VERSION "dbc-export 1 2026.26.6.5"

NS_ :

BS_:

BU_: ADSP APB APP APS APSB BB BMS CC CMP CMPD CP DAS DI DIF DIR DPB EPAS3P EPAS3S EPASTP EPASTS EPBL EPBR ESP EVSE FC GTW HCML HCMR HVP IBST ICR IDB LS OCS1P PARK PCS PCS2 PM PMF PMR PNCD PTC RADC RCM RCM2 RCM3 RCU SCCM SCM SCS SDCR TAS TCU TCU2 TPMS TRCM UI UIS UMC USM V2G VC VCBATT VCBATT0 VCBATT1 VCBATT2 VCCC VCFRONT VCFRONT1 VCFRONT2 VCLEFT VCRIGHT VCSEAT2L VCSEAT2R VCSEC VEH

BO_ 1065 APP_warningMatrix2: 8 APP
 SG_ APP_w129_mainCamExtNotCal : 0|1@1+ (1,0) [0|1] "" Vector__XXX
 SG_ APP_w130_narrowCamExtNotCal : 1|1@1+ (1,0) [0|1] "" Vector__XXX
 SG_ APP_w131_mainCamCalSaved : 2|1@1+ (1,0) [0|1] "" Vector__XXX
 SG_ APP_w132_narrowCamCalSaved : 3|1@1+ (1,0) [0|1] "" Vector__XXX
 SG_ APP_w133_mainCamInitFault : 4|1@1+ (1,0) [0|1] "" Vector__XXX
 SG_ APP_w134_narrowCamInitFault : 5|1@1+ (1,0) [0|1] "" Vector__XXX
 SG_ APP_w135_fisheyeCamInitFault : 6|1@1+ (1,0) [0|1] "" Vector__XXX
 SG_ APP_w136_lPillarCamInitFault : 7|1@1+ (1,0) [0|1] "" Vector__XXX
 SG_ APP_w137_rPillarCamInitFault : 8|1@1+ (1,0) [0|1] "" Vector__XXX
 SG_ APP_w138_lRepeatCamInitFault : 9|1@1+ (1,0) [0|1] "" Vector__XXX
 SG_ APP_w139_rRepeatCamInitFault : 10|1@1+ (1,0) [0|1] "" Vector__XXX
 SG_ APP_w140_backupCamInitFault : 11|1@1+ (1,0) [0|1] "" Vector__XXX
 SG_ APP_w141_ECU_Thermal_Issue : 12|1@1+ (1,0) [0|1] "" Vector__XXX
 SG_ APP_w142_fwdCamPitchProblem : 13|1@1+ (1,0) [0|1] "" Vector__XXX
 SG_ APP_w143_IDF_event : 14|1@1+ (1,0) [0|1] "" Vector__XXX
 SG_ APP_w144_fanctrldError : 15|1@1+ (1,0) [0|1] "" Vector__XXX
 SG_ APP_w145_camSelfCalIssue : 16|1@1+ (1,0) [0|1] "" Vector__XXX
 SG_ APP_w146_telemetryProblem : 17|1@1+ (1,0) [0|1] "" Vector__XXX
 SG_ APP_w147_selfieCamInitFault : 18|1@1+ (1,0) [0|1] "" Vector__XXX
 SG_ APP_w148_overlayActive : 19|1@1+ (1,0) [0|1] "" Vector__XXX
 SG_ APP_w149_diskFull : 20|1@1+ (1,0) [0|1] "" Vector__XXX
 SG_ APP_w150_diMiaPartyBus : 21|1@1+ (1,0) [0|1] "" Vector__XXX
 SG_ APP_w151_epasMiaPartyBus : 22|1@1+ (1,0) [0|1] "" Vector__XXX
 SG_ APP_w152_espMiaPartyBus : 23|1@1+ (1,0) [0|1] "" Vector__XXX
 SG_ APP_w153_rcmMiaPartyBus : 24|1@1+ (1,0) [0|1] "" Vector__XXX
 SG_ APP_w154_vcleftMiaPartyBus : 25|1@1+ (1,0) [0|1] "" Vector__XXX
 SG_ APP_w155_vcrightMiaPartyBus : 26|1@1+ (1,0) [0|1] "" Vector__XXX
 SG_ APP_w156_epblMiaVehBus : 27|1@1+ (1,0) [0|1] "" Vector__XXX
 SG_ APP_w157_sccmMiaVehBus : 28|1@1+ (1,0) [0|1] "" Vector__XXX
 SG_ APP_w158_vcfrontMiaVehBus : 29|1@1+ (1,0) [0|1] "" Vector__XXX
 SG_ APP_w159_vcleftMiaVehBus : 30|1@1+ (1,0) [0|1] "" Vector__XXX
 SG_ APP_w160_vcrightMiaVehBus : 31|1@1+ (1,0) [0|1] "" Vector__XXX
 SG_ APP_w161_backupCameraUnavailable : 32|1@1+ (1,0) [0|1] "" Vector__XXX
 SG_ APP_w162_mainCameraTypeError : 33|1@1+ (1,0) [0|1] "" Vector__XXX
 SG_ APP_w163_narrowCameraTypeError : 34|1@1+ (1,0) [0|1] "" Vector__XXX
 SG_ APP_w164_fisheyeCameraTypeError : 35|1@1+ (1,0) [0|1] "" Vector__XXX
 SG_ APP_w165_lPillarCameraTypeError : 36|1@1+ (1,0) [0|1] "" Vector__XXX
 SG_ APP_w166_rPillarCameraTypeError : 37|1@1+ (1,0) [0|1] "" Vector__XXX
 SG_ APP_w167_lRepeatCameraTypeError : 38|1@1+ (1,0) [0|1] "" Vector__XXX
 SG_ APP_w168_rRepeatCameraTypeError : 39|1@1+ (1,0) [0|1] "" Vector__XXX
 SG_ APP_w169_backupCameraTypeError : 40|1@1+ (1,0) [0|1] "" Vector__XXX
 SG_ APP_w170_selfieCameraTypeError : 41|1@1+ (1,0) [0|1] "" Vector__XXX
 SG_ APP_w171_appHighCoolantFlowReq : 42|1@1+ (1,0) [0|1] "" Vector__XXX
 SG_ APP_w172_fisheyeCamExtNotCal : 43|1@1+ (1,0) [0|1] "" Vector__XXX
 SG_ APP_w173_lPillarCamExtNotCal : 44|1@1+ (1,0) [0|1] "" Vector__XXX
 SG_ APP_w174_rPillarCamExtNotCal : 45|1@1+ (1,0) [0|1] "" Vector__XXX
 SG_ APP_w175_lRepeatCamExtNotCal : 46|1@1+ (1,0) [0|1] "" Vector__XXX
 SG_ APP_w176_rRepeatCamExtNotCal : 47|1@1+ (1,0) [0|1] "" Vector__XXX
 SG_ APP_w177_fisheyeCamCalSaved : 48|1@1+ (1,0) [0|1] "" Vector__XXX
 SG_ APP_w178_lPillarCamCalSaved : 49|1@1+ (1,0) [0|1] "" Vector__XXX
 SG_ APP_w179_rPillarCamCalSaved : 50|1@1+ (1,0) [0|1] "" Vector__XXX
 SG_ APP_w180_lRepeatCamCalSaved : 51|1@1+ (1,0) [0|1] "" Vector__XXX
 SG_ APP_w181_rRepeatCamCalSaved : 52|1@1+ (1,0) [0|1] "" Vector__XXX
 SG_ APP_w182_mainCameraStreamExit : 53|1@1+ (1,0) [0|1] "" Vector__XXX
 SG_ APP_w183_narrowCameraStreamExit : 54|1@1+ (1,0) [0|1] "" Vector__XXX
 SG_ APP_w184_fisheyeCameraStreamExit : 55|1@1+ (1,0) [0|1] "" Vector__XXX
 SG_ APP_w185_lPillarCameraStreamExit : 56|1@1+ (1,0) [0|1] "" Vector__XXX
 SG_ APP_w186_rPillarCameraStreamExit : 57|1@1+ (1,0) [0|1] "" Vector__XXX
 SG_ APP_w187_lRepeatCameraStreamExit : 58|1@1+ (1,0) [0|1] "" Vector__XXX
 SG_ APP_w188_rRepeatCameraStreamExit : 59|1@1+ (1,0) [0|1] "" Vector__XXX
 SG_ APP_w189_backupCameraStreamExit : 60|1@1+ (1,0) [0|1] "" Vector__XXX
 SG_ APP_w190_selfieCameraStreamExit : 61|1@1+ (1,0) [0|1] "" Vector__XXX
 SG_ APP_w191_autopilotAborting : 62|1@1+ (1,0) [0|1] "" Vector__XXX
 SG_ APP_w192_emergencySpeakerFail : 63|1@1+ (1,0) [0|1] "" Vector__XXX

BO_ 1081 APP_warningMatrix3: 8 APP
 SG_ APP_w193_camWindshieldUnclean : 0|1@1+ (1,0) [0|1] "" Vector__XXX
 SG_ APP_w194_accDriverResumeRqrd : 1|1@1+ (1,0) [0|1] "" Vector__XXX
 SG_ APP_w195_scwUnavailable : 2|1@1+ (1,0) [0|1] "" Vector__XXX
 SG_ APP_w196_stopSignWarning : 3|1@1+ (1,0) [0|1] "" Vector__XXX
 SG_ APP_w197_redLightWarning : 4|1@1+ (1,0) [0|1] "" Vector__XXX
 SG_ APP_w198_tsrUnavailable : 5|1@1+ (1,0) [0|1] "" Vector__XXX
 SG_ APP_w199_apcAbort : 6|1@1+ (1,0) [0|1] "" Vector__XXX
 SG_ APP_w200_lcSlowdown : 7|1@1+ (1,0) [0|1] "" Vector__XXX
 SG_ APP_w201_lcAborting : 8|1@1+ (1,0) [0|1] "" Vector__XXX
 SG_ APP_w202_scwNoisyEnvironment : 9|1@1+ (1,0) [0|1] "" Vector__XXX
 SG_ APP_w203_apcActivation : 10|1@1+ (1,0) [0|1] "" Vector__XXX
 SG_ APP_w204_apcFinalFront : 11|1@1+ (1,0) [0|1] "" Vector__XXX
 SG_ APP_w205_apcFinalRear : 12|1@1+ (1,0) [0|1] "" Vector__XXX
 SG_ APP_w206_autosteerNotEnabled : 13|1@1+ (1,0) [0|1] "" Vector__XXX
 SG_ APP_w207_autosteerUnavailable : 14|1@1+ (1,0) [0|1] "" Vector__XXX
 SG_ APP_w208_rackDetected : 15|1@1+ (1,0) [0|1] "" Vector__XXX
 SG_ APP_w209_autoSummonRequest : 16|1@1+ (1,0) [0|1] "" Vector__XXX
 SG_ APP_w210_camObstrcted : 17|1@1+ (1,0) [0|1] "" Vector__XXX
 SG_ APP_w211_accNoSeatBelt : 18|1@1+ (1,0) [0|1] "" Vector__XXX
 SG_ APP_w212_lcUnavailableStrikeOut : 19|1@1+ (1,0) [0|1] "" Vector__XXX
 SG_ APP_w213_autosteerStruckOut : 20|1@1+ (1,0) [0|1] "" Vector__XXX
 SG_ APP_w214_driverNotIntracting : 21|1@1+ (1,0) [0|1] "" Vector__XXX
 SG_ APP_w215_contDriverNotIntracting : 22|1@1+ (1,0) [0|1] "" Vector__XXX
 SG_ APP_w216_driverOverriding : 23|1@1+ (1,0) [0|1] "" Vector__XXX
 SG_ APP_w217_lcUnavailableSpeeding : 24|1@1+ (1,0) [0|1] "" Vector__XXX
 SG_ APP_w218_lcSpeedExceededLimit : 25|1@1+ (1,0) [0|1] "" Vector__XXX
 SG_ APP_w219_lcTempUnavailableSpeed : 26|1@1+ (1,0) [0|1] "" Vector__XXX
 SG_ APP_w220_lcTempUnavailableRoad : 27|1@1+ (1,0) [0|1] "" Vector__XXX
 SG_ APP_w221_accRadarBlind : 28|1@1+ (1,0) [0|1] "" Vector__XXX
 SG_ APP_w222_accCameraBlind : 29|1@1+ (1,0) [0|1] "" Vector__XXX
 SG_ APP_w223_accObjectInPath : 30|1@1+ (1,0) [0|1] "" Vector__XXX
 SG_ APP_w224_accCameraCalibration : 31|1@1+ (1,0) [0|1] "" Vector__XXX
 SG_ APP_w225_lcDegradedVisSpeedLmt : 32|1@1+ (1,0) [0|1] "" Vector__XXX
 SG_ APP_w226_lcCamCalNeededSpeedLmt : 33|1@1+ (1,0) [0|1] "" Vector__XXX
 SG_ APP_w227_virtualWallBlocked : 34|1@1+ (1,0) [0|1] "" Vector__XXX
 SG_ APP_w228_DEPRECATED : 35|1@1+ (1,0) [0|1] "" Vector__XXX
 SG_ APP_w229_alcUltrasoundDamaged : 36|1@1+ (1,0) [0|1] "" Vector__XXX
 SG_ APP_w230_alcUltrasoundBlocked : 37|1@1+ (1,0) [0|1] "" Vector__XXX
 SG_ APP_w231_idfEvent : 38|1@1+ (1,0) [0|1] "" Vector__XXX
 SG_ APP_w232_laneChangeRequested : 39|1@1+ (1,0) [0|1] "" Vector__XXX
 SG_ APP_w233_fsdQuizRequired : 40|1@1+ (1,0) [0|1] "" Vector__XXX
 SG_ APP_w234_activeSafetyTelemetry : 41|1@1+ (1,0) [0|1] "" Vector__XXX
 SG_ APP_w235_fsdRegionNotAllowed : 42|1@1+ (1,0) [0|1] "" Vector__XXX

BO_ 1097 APP_warningMatrix4: 8 APP
 SG_ APP_w257_brakeJerkEvent : 0|1@1+ (1,0) [0|1] "" Vector__XXX
 SG_ APP_w258_aebEvent : 1|1@1+ (1,0) [0|1] "" Vector__XXX
 SG_ APP_w259_aebOverrideEvent : 2|1@1+ (1,0) [0|1] "" Vector__XXX
 SG_ APP_w260_collisionWarningEvent : 3|1@1+ (1,0) [0|1] "" Vector__XXX
 SG_ APP_w261_pcieHardwareErrors : 4|1@1+ (1,0) [0|1] "" Vector__XXX
 SG_ APP_w262_apeCalibMode : 5|1@1+ (1,0) [0|1] "" Vector__XXX
 SG_ APP_w263_lssAbort : 6|1@1+ (1,0) [0|1] "" Vector__XXX
 SG_ APP_w264_lssFault : 7|1@1+ (1,0) [0|1] "" Vector__XXX
 SG_ APP_w265_drvOnNavUnavailable : 8|1@1+ (1,0) [0|1] "" Vector__XXX
 SG_ APP_w266_visionScheduleFallback : 9|1@1+ (1,0) [0|1] "" Vector__XXX
 SG_ APP_w267_benchtopEcu : 10|1@1+ (1,0) [0|1] "" Vector__XXX
 SG_ APP_w268_backupCamExtNotCal : 11|1@1+ (1,0) [0|1] "" Vector__XXX
 SG_ APP_w269_autopilotLimited : 12|1@1+ (1,0) [0|1] "" Vector__XXX
 SG_ APP_w270_blindspotRestricted : 13|1@1+ (1,0) [0|1] "" Vector__XXX
 SG_ APP_w271_laneChangeAborted : 14|1@1+ (1,0) [0|1] "" Vector__XXX
 SG_ APP_w272_laneChangeUnavailable : 15|1@1+ (1,0) [0|1] "" Vector__XXX
 SG_ APP_w273_lssEvent : 16|1@1+ (1,0) [0|1] "" Vector__XXX
 SG_ APP_w274_mainCameraStreamErr : 17|1@1+ (1,0) [0|1] "" Vector__XXX
 SG_ APP_w275_narrowCameraStreamErr : 18|1@1+ (1,0) [0|1] "" Vector__XXX
 SG_ APP_w276_fisheyeCameraStreamErr : 19|1@1+ (1,0) [0|1] "" Vector__XXX
 SG_ APP_w277_lPillarCameraStreamErr : 20|1@1+ (1,0) [0|1] "" Vector__XXX
 SG_ APP_w278_rPillarCameraStreamErr : 21|1@1+ (1,0) [0|1] "" Vector__XXX
 SG_ APP_w279_lRepeatCameraStreamErr : 22|1@1+ (1,0) [0|1] "" Vector__XXX
 SG_ APP_w280_rRepeatCameraStreamErr : 23|1@1+ (1,0) [0|1] "" Vector__XXX
 SG_ APP_w281_backupCameraStreamErr : 24|1@1+ (1,0) [0|1] "" Vector__XXX
 SG_ APP_w282_selfieCameraStreamErr : 25|1@1+ (1,0) [0|1] "" Vector__XXX
 SG_ APP_w283_enhancedSummonAbort : 26|1@1+ (1,0) [0|1] "" Vector__XXX
 SG_ APP_w284_gpsAntennaDisconnected : 27|1@1+ (1,0) [0|1] "" Vector__XXX
 SG_ APP_w285_gpsFaultReset : 28|1@1+ (1,0) [0|1] "" Vector__XXX
 SG_ APP_w286_gpsComIssue : 29|1@1+ (1,0) [0|1] "" Vector__XXX
 SG_ APP_w287_gpsFusionStatus : 30|1@1+ (1,0) [0|1] "" Vector__XXX
 SG_ APP_w288_trafficLightWarning : 31|1@1+ (1,0) [0|1] "" Vector__XXX
 SG_ APP_w289_dramCorrEccErrors : 32|1@1+ (1,0) [0|1] "" Vector__XXX
 SG_ APP_w290_dramUncorrEccErrors : 33|1@1+ (1,0) [0|1] "" Vector__XXX
 SG_ APP_w291_stopSignWarning : 34|1@1+ (1,0) [0|1] "" Vector__XXX
 SG_ APP_w293_mainCameraSyncFailed : 36|1@1+ (1,0) [0|1] "" Vector__XXX
 SG_ APP_w294_narrowCameraSyncFailed : 37|1@1+ (1,0) [0|1] "" Vector__XXX
 SG_ APP_w295_fisheyeCameraSyncFailed : 38|1@1+ (1,0) [0|1] "" Vector__XXX
 SG_ APP_w296_lPillarCameraSyncFailed : 39|1@1+ (1,0) [0|1] "" Vector__XXX
 SG_ APP_w297_rPillarCameraSyncFailed : 40|1@1+ (1,0) [0|1] "" Vector__XXX
 SG_ APP_w298_lRepeatCameraSyncFailed : 41|1@1+ (1,0) [0|1] "" Vector__XXX
 SG_ APP_w299_rRepeatCameraSyncFailed : 42|1@1+ (1,0) [0|1] "" Vector__XXX
 SG_ APP_w300_backupCameraSyncFailed : 43|1@1+ (1,0) [0|1] "" Vector__XXX
 SG_ APP_w301_selfieCameraSyncFailed : 44|1@1+ (1,0) [0|1] "" Vector__XXX
 SG_ APP_w302_vcfrontMiaPartyBus : 45|1@1+ (1,0) [0|1] "" Vector__XXX
 SG_ APP_w303_imuIrational : 46|1@1+ (1,0) [0|1] "" Vector__XXX
 SG_ APP_w304_lssCamBlockedStatus : 47|1@1+ (1,0) [0|1] "" Vector__XXX
 SG_ APP_w305_lssCamStreamExit : 48|1@1+ (1,0) [0|1] "" Vector__XXX
 SG_ APP_w306_lssUltrasonicsBlocked : 49|1@1+ (1,0) [0|1] "" Vector__XXX
 SG_ APP_w307_lssTurnSignalFault : 50|1@1+ (1,0) [0|1] "" Vector__XXX
 SG_ APP_w308_iboosterMia : 51|1@1+ (1,0) [0|1] "" Vector__XXX
 SG_ APP_w309_selfieDisabledOnCar : 52|1@1+ (1,0) [0|1] "" Vector__XXX
 SG_ APP_w310_eth0FrameErrors : 53|1@1+ (1,0) [0|1] "" Vector__XXX
 SG_ APP_w311_eth1FrameErrors : 54|1@1+ (1,0) [0|1] "" Vector__XXX
 SG_ APP_w312_mainCamTypeMismatch : 55|1@1+ (1,0) [0|1] "" Vector__XXX
 SG_ APP_w313_narrowCamTypeMismatch : 56|1@1+ (1,0) [0|1] "" Vector__XXX
 SG_ APP_w314_fisheyeCamTypeMismatch : 57|1@1+ (1,0) [0|1] "" Vector__XXX
 SG_ APP_w315_lPillarCamTypeMismatch : 58|1@1+ (1,0) [0|1] "" Vector__XXX
 SG_ APP_w316_rPillarCamTypeMismatch : 59|1@1+ (1,0) [0|1] "" Vector__XXX
 SG_ APP_w317_lRepeatCamTypeMismatch : 60|1@1+ (1,0) [0|1] "" Vector__XXX
 SG_ APP_w318_rRepeatCamTypeMismatch : 61|1@1+ (1,0) [0|1] "" Vector__XXX
 SG_ APP_w319_backupCamTypeMismatch : 62|1@1+ (1,0) [0|1] "" Vector__XXX
 SG_ APP_w320_selfieCamTypeMismatch : 63|1@1+ (1,0) [0|1] "" Vector__XXX

BO_ 1151 APP_warningMatrix5: 8 APP
 SG_ APP_w321_bmsMia : 0|1@1+ (1,0) [0|1] "" Vector__XXX
 SG_ APP_w322_autoWiperWash : 1|1@1+ (1,0) [0|1] "" Vector__XXX
 SG_ APP_w323_drivableSpaceFCW : 2|1@1+ (1,0) [0|1] "" Vector__XXX
 SG_ APP_w324_adspMia : 3|1@1+ (1,0) [0|1] "" Vector__XXX
 SG_ APP_w325_watchdogReset : 4|1@1+ (1,0) [0|1] "" Vector__XXX
 SG_ APP_w326_kernelPanic : 5|1@1+ (1,0) [0|1] "" Vector__XXX
 SG_ APP_w327_vehicleConfigMismatch : 6|1@1+ (1,0) [0|1] "" Vector__XXX
 SG_ APP_w328_autoparkDegraded : 7|1@1+ (1,0) [0|1] "" Vector__XXX
 SG_ APP_w329_evasiveManeuver : 8|1@1+ (1,0) [0|1] "" Vector__XXX
 SG_ APP_w330_cabinCameraFault : 9|1@1+ (1,0) [0|1] "" Vector__XXX
 SG_ APP_w331_fsdDegradedUnavailable : 10|1@1+ (1,0) [0|1] "" Vector__XXX
 SG_ APP_w332_cameraPositionsSwapped : 11|1@1+ (1,0) [0|1] "" Vector__XXX
 SG_ APP_w333_fsdUnavailableLocation : 12|1@1+ (1,0) [0|1] "" Vector__XXX
 SG_ APP_w334_frontCameraOccluded : 13|1@1+ (1,0) [0|1] "" Vector__XXX
 SG_ APP_w335_tradfcRfSensorError : 14|1@1+ (1,0) [0|1] "" Vector__XXX
 SG_ APP_w336_tradfcLfPmicError : 15|1@1+ (1,0) [0|1] "" Vector__XXX
 SG_ APP_w337_tradfcRfPmicError : 16|1@1+ (1,0) [0|1] "" Vector__XXX
 SG_ APP_w338_tradfcLfTempError : 17|1@1+ (1,0) [0|1] "" Vector__XXX
 SG_ APP_w339_tradfcRfTempError : 18|1@1+ (1,0) [0|1] "" Vector__XXX
 SG_ APP_w340_tradfcCsiError : 19|1@1+ (1,0) [0|1] "" Vector__XXX
 SG_ APP_w341_tradfcCalibError : 20|1@1+ (1,0) [0|1] "" Vector__XXX
 SG_ APP_w342_tradfcDspHwError : 21|1@1+ (1,0) [0|1] "" Vector__XXX
 SG_ APP_w343_tradfcDspSwError : 22|1@1+ (1,0) [0|1] "" Vector__XXX
 SG_ APP_w344_tradfcDspAlgoTimeout : 23|1@1+ (1,0) [0|1] "" Vector__XXX
 SG_ APP_w345_tradfcPerfDegraded : 24|1@1+ (1,0) [0|1] "" Vector__XXX
 SG_ APP_w346_gpsSwEvent : 25|1@1+ (1,0) [0|1] "" Vector__XXX
 SG_ APP_w347_vcbattMiaVehBus : 26|1@1+ (1,0) [0|1] "" Vector__XXX
 SG_ APP_w348_cameraSwUpdateRequired : 27|1@1+ (1,0) [0|1] "" Vector__XXX
 SG_ APP_w349_cameraPersistentlyFault : 28|1@1+ (1,0) [0|1] "" Vector__XXX
 SG_ APP_w350_tradfcSensorMisaligned : 29|1@1+ (1,0) [0|1] "" Vector__XXX
 SG_ APP_w351_csiDevice0Down : 30|1@1+ (1,0) [0|1] "" Vector__XXX
 SG_ APP_w352_csiDevice1Down : 31|1@1+ (1,0) [0|1] "" Vector__XXX
 SG_ APP_w353_csiDevice2Down : 32|1@1+ (1,0) [0|1] "" Vector__XXX
 SG_ APP_w354_tradfcMia : 33|1@1+ (1,0) [0|1] "" Vector__XXX
 SG_ APP_w355_camQuadPowerFault : 34|1@1+ (1,0) [0|1] "" Vector__XXX
 SG_ APP_w356_driverOverriding : 35|1@1+ (1,0) [0|1] "" Vector__XXX
 SG_ APP_w357_ddawSystemFault : 36|1@1+ (1,0) [0|1] "" Vector__XXX
 SG_ APP_w358_isaSystemFault : 37|1@1+ (1,0) [0|1] "" Vector__XXX
 SG_ APP_w359_aebDegraded : 38|1@1+ (1,0) [0|1] "" Vector__XXX
 SG_ APP_w360_apImuNoiseDetected : 39|1@1+ (1,0) [0|1] "" Vector__XXX
 SG_ APP_w361_cabinCameraLEDFault : 40|1@1+ (1,0) [0|1] "" Vector__XXX
 SG_ APP_w362_fasciaCamInitFault : 41|1@1+ (1,0) [0|1] "" Vector__XXX
 SG_ APP_w363_fasciaCameraStreamExit : 42|1@1+ (1,0) [0|1] "" Vector__XXX
 SG_ APP_w364_fasciaCameraTypeError : 43|1@1+ (1,0) [0|1] "" Vector__XXX
 SG_ APP_w365_fasciaCamExtNotCal : 44|1@1+ (1,0) [0|1] "" Vector__XXX
 SG_ APP_w366_fasciaCameraSyncFailed : 45|1@1+ (1,0) [0|1] "" Vector__XXX
 SG_ APP_w367_fasciaCamCalSaved : 46|1@1+ (1,0) [0|1] "" Vector__XXX
 SG_ APP_w368_fasciaCamTypeMismatch : 47|1@1+ (1,0) [0|1] "" Vector__XXX
 SG_ APP_w369_cruiseWithSingleClick : 48|1@1+ (1,0) [0|1] "" Vector__XXX
 SG_ APP_w370_accApUnavUserSettings : 49|1@1+ (1,0) [0|1] "" Vector__XXX
 SG_ APP_w371_networkLoadingIssue : 50|1@1+ (1,0) [0|1] "" Vector__XXX
 SG_ APP_w372_cabinCameraBlocked : 51|1@1+ (1,0) [0|1] "" Vector__XXX
 SG_ APP_w373_gnssUartError : 52|1@1+ (1,0) [0|1] "" Vector__XXX
 SG_ APP_w374_gnssDataMia : 53|1@1+ (1,0) [0|1] "" Vector__XXX
 SG_ APP_w375_gnssPpsMia : 54|1@1+ (1,0) [0|1] "" Vector__XXX
 SG_ APP_w376_wheeltickCountMia : 55|1@1+ (1,0) [0|1] "" Vector__XXX
 SG_ APP_w377_apImuMia : 56|1@1+ (1,0) [0|1] "" Vector__XXX
 SG_ APP_w378_ubloxImuMia : 57|1@1+ (1,0) [0|1] "" Vector__XXX
 SG_ APP_w379_positioningEngineMia : 58|1@1+ (1,0) [0|1] "" Vector__XXX
 SG_ APP_w380_gnssPpsTimestampIssue : 59|1@1+ (1,0) [0|1] "" Vector__XXX
 SG_ APP_w381_apImuTimestampIssue : 60|1@1+ (1,0) [0|1] "" Vector__XXX
 SG_ APP_w382_ubloxImuTimestampIssue : 61|1@1+ (1,0) [0|1] "" Vector__XXX
 SG_ APP_w383_manyApRebootsWhileInP : 62|1@1+ (1,0) [0|1] "" Vector__XXX
 SG_ APP_w384_posEngineInitInMotion : 63|1@1+ (1,0) [0|1] "" Vector__XXX

BO_ 1149 APP_warningMatrix6: 8 APP
 SG_ APP_w385_posEngineUnhealthy : 0|1@1+ (1,0) [0|1] "" Vector__XXX
 SG_ APP_w386_radarOnlyBrakingEvent : 1|1@1+ (1,0) [0|1] "" Vector__XXX
 SG_ APP_w387_radarBlockageDetected : 2|1@1+ (1,0) [0|1] "" Vector__XXX
 SG_ APP_w388_windshieldCameraHeaterF : 3|1@1+ (1,0) [0|1] "" Vector__XXX
 SG_ APP_w389_camFovResidueDetected : 4|1@1+ (1,0) [0|1] "" Vector__XXX
 SG_ APP_w390_cabinCamVisDegraded : 5|1@1+ (1,0) [0|1] "" Vector__XXX
 SG_ APP_w391_cabinCameraBlockedonAP : 6|1@1+ (1,0) [0|1] "" Vector__XXX
 SG_ APP_w392_fsdSuspended : 7|1@1+ (1,0) [0|1] "" Vector__XXX
 SG_ APP_w393_attnMntrUnavailable : 8|1@1+ (1,0) [0|1] "" Vector__XXX
 SG_ APP_w394_apImuGrossErrors : 9|1@1+ (1,0) [0|1] "" Vector__XXX
 SG_ APP_w395_cabinCameraLEDFaultSvc : 10|1@1+ (1,0) [0|1] "" Vector__XXX
 SG_ APP_w396_severeResidueDetected : 11|1@1+ (1,0) [0|1] "" Vector__XXX
 SG_ APP_w397_apFeatDisabledPermanent : 12|1@1+ (1,0) [0|1] "" Vector__XXX
 SG_ APP_w398_imuOutputUnhealthy : 13|1@1+ (1,0) [0|1] "" Vector__XXX
 SG_ APP_w399_brakeboosterMia : 14|1@1+ (1,0) [0|1] "" Vector__XXX
 SG_ APP_w400_selfieCameraFanFault : 15|1@1+ (1,0) [0|1] "" Vector__XXX
 SG_ APP_w401_leftPillarCameraHeaterF : 16|1@1+ (1,0) [0|1] "" Vector__XXX
 SG_ APP_w402_rightPillarCameraHeater : 17|1@1+ (1,0) [0|1] "" Vector__XXX
 SG_ APP_w403_notifyCameraSelfCleanAc : 18|1@1+ (1,0) [0|1] "" Vector__XXX
 SG_ APP_w404_epbrMiaVehBus : 19|1@1+ (1,0) [0|1] "" Vector__XXX
 SG_ APP_w405_apsMia : 20|1@1+ (1,0) [0|1] "" Vector__XXX
 SG_ APP_w406_gnssHWHealthDegraded : 21|1@1+ (1,0) [0|1] "" Vector__XXX
 SG_ APP_w407_autonomyDegraded1 : 22|1@1+ (1,0) [0|1] "" Vector__XXX
 SG_ APP_w408_autonomyDegraded2 : 23|1@1+ (1,0) [0|1] "" Vector__XXX
 SG_ APP_w409_autonomyDegraded3 : 24|1@1+ (1,0) [0|1] "" Vector__XXX
 SG_ APP_w410_autonomyDegraded4 : 25|1@1+ (1,0) [0|1] "" Vector__XXX
 SG_ APP_w411_backupCameraOccluded : 26|1@1+ (1,0) [0|1] "" Vector__XXX
 SG_ APP_w412_abortBackupCamOccluded : 27|1@1+ (1,0) [0|1] "" Vector__XXX
 SG_ APP_w413_autonomyDegraded5 : 28|1@1+ (1,0) [0|1] "" Vector__XXX
 SG_ APP_w415_autonomyUnavailableSyst : 30|1@1+ (1,0) [0|1] "" Vector__XXX
 SG_ APP_w416_autonomyDegradedSystem : 31|1@1+ (1,0) [0|1] "" Vector__XXX
 SG_ APP_w417_autonomyUnavailableVisi : 32|1@1+ (1,0) [0|1] "" Vector__XXX
 SG_ APP_w418_autonomyDegradedVisibil : 33|1@1+ (1,0) [0|1] "" Vector__XXX
 SG_ APP_w419_autonomyUnavailableApSy : 34|1@1+ (1,0) [0|1] "" Vector__XXX
 SG_ APP_w420_autonomyDegradedApSyste : 35|1@1+ (1,0) [0|1] "" Vector__XXX
 SG_ APP_w421_autonomyUnavailableUser : 36|1@1+ (1,0) [0|1] "" Vector__XXX
 SG_ APP_w422_autonomyDegradedUser : 37|1@1+ (1,0) [0|1] "" Vector__XXX
 SG_ APP_w423_cameraVisPopUpForward : 38|1@1+ (1,0) [0|1] "" Vector__XXX
 SG_ APP_w424_cameraVisPopUpLPillar : 39|1@1+ (1,0) [0|1] "" Vector__XXX
 SG_ APP_w425_cameraVisPopUpRPillar : 40|1@1+ (1,0) [0|1] "" Vector__XXX
 SG_ APP_w426_cameraVisPopUpLRepeater : 41|1@1+ (1,0) [0|1] "" Vector__XXX
 SG_ APP_w427_cameraVisPopUpRRepeater : 42|1@1+ (1,0) [0|1] "" Vector__XXX
 SG_ APP_w428_cameraVisPopUpBackup : 43|1@1+ (1,0) [0|1] "" Vector__XXX
 SG_ APP_w429_cameraVisPopUpFascia : 44|1@1+ (1,0) [0|1] "" Vector__XXX
 SG_ APP_w430_frontVisibilityDegraded : 45|1@1+ (1,0) [0|1] "" Vector__XXX
 SG_ APP_w431_frontVisibilityDegraded : 46|1@1+ (1,0) [0|1] "" Vector__XXX
 SG_ APP_w432_frontVisibilityDegraded : 47|1@1+ (1,0) [0|1] "" Vector__XXX
 SG_ APP_w433_leftRepeaterDowngradeDe : 48|1@1+ (1,0) [0|1] "" Vector__XXX
 SG_ APP_w434_rightRepeaterDowngradeD : 49|1@1+ (1,0) [0|1] "" Vector__XXX
 SG_ APP_w435_repeaterAeroRibInfoMism : 50|1@1+ (1,0) [0|1] "" Vector__XXX
 SG_ APP_w436_camCsiError : 51|1@1+ (1,0) [0|1] "" Vector__XXX
 SG_ APP_w437_missingCloudEepromData : 52|1@1+ (1,0) [0|1] "" Vector__XXX
 SG_ APP_w438_rcuMia : 53|1@1+ (1,0) [0|1] "" Vector__XXX
 SG_ APP_w439_ethernetCommFailure : 54|1@1+ (1,0) [0|1] "" Vector__XXX
 SG_ APP_w440_lensHoodOcclusion : 55|1@1+ (1,0) [0|1] "" Vector__XXX
 SG_ APP_w441_cabinCamLEDRailOff : 56|1@1+ (1,0) [0|1] "" Vector__XXX
 SG_ APP_w442_autonomyCancelMethod : 57|1@1+ (1,0) [0|1] "" Vector__XXX
 SG_ APP_w443_mainImagerConfigMismatc : 58|1@1+ (1,0) [0|1] "" Vector__XXX
 SG_ APP_w444_narrowImagerConfigMisma : 59|1@1+ (1,0) [0|1] "" Vector__XXX
 SG_ APP_w445_fisheyeImagerConfigMism : 60|1@1+ (1,0) [0|1] "" Vector__XXX
 SG_ APP_w446_leftPillarImagerConfigM : 61|1@1+ (1,0) [0|1] "" Vector__XXX
 SG_ APP_w447_rightPillarImagerConfig : 62|1@1+ (1,0) [0|1] "" Vector__XXX
 SG_ APP_w448_leftRepeaterImagerConfi : 63|1@1+ (1,0) [0|1] "" Vector__XXX

BO_ 1233 APP_warningMatrix7: 8 APP
 SG_ APP_w449_rightRepeaterImagerConf : 0|1@1+ (1,0) [0|1] "" Vector__XXX
 SG_ APP_w450_backupImagerConfigMisma : 1|1@1+ (1,0) [0|1] "" Vector__XXX
 SG_ APP_w451_fasciaImagerConfigMisma : 2|1@1+ (1,0) [0|1] "" Vector__XXX
 SG_ APP_w452_selfieImagerConfigMisma : 3|1@1+ (1,0) [0|1] "" Vector__XXX
 SG_ APP_w453_driverCancelBlinker : 4|1@1+ (1,0) [0|1] "" Vector__XXX
 SG_ APP_w454_appAutonomySystemUnheal : 5|1@1+ (1,0) [0|1] "" Vector__XXX
 SG_ APP_w455_apbAutonomySystemUnheal : 6|1@1+ (1,0) [0|1] "" Vector__XXX
 SG_ APP_w456_autonomyUnavailableColl : 7|1@1+ (1,0) [0|1] "" Vector__XXX
 SG_ APP_w457_autonomyDegradedCollisi : 8|1@1+ (1,0) [0|1] "" Vector__XXX
 SG_ APP_w458_aceEvent : 9|1@1+ (1,0) [0|1] "" Vector__XXX
 SG_ APP_w459_epbrMiaPartyBus : 10|1@1+ (1,0) [0|1] "" Vector__XXX
 SG_ APP_w460_epblMiaChBus : 11|1@1+ (1,0) [0|1] "" Vector__XXX
 SG_ APP_w461_autonomyReroute : 12|1@1+ (1,0) [0|1] "" Vector__XXX
 SG_ APP_w462_selfDrivingUnavailable : 13|1@1+ (1,0) [0|1] "" Vector__XXX
 SG_ APP_w463_selfDrivingCamObstrcted : 14|1@1+ (1,0) [0|1] "" Vector__XXX
 SG_ APP_w464_autonomyUnavailableODD : 15|1@1+ (1,0) [0|1] "" Vector__XXX
 SG_ APP_w465_autonomyDegradedODD : 16|1@1+ (1,0) [0|1] "" Vector__XXX
 SG_ APP_w466_missingSensorOTP : 17|1@1+ (1,0) [0|1] "" Vector__XXX
 SG_ APP_w467_imuDegraded : 18|1@1+ (1,0) [0|1] "" Vector__XXX
 SG_ APP_w477_driverSeatReclined : 28|1@1+ (1,0) [0|1] "" Vector__XXX
 SG_ APP_w478_runModeSwitch : 29|1@1+ (1,0) [0|1] "" Vector__XXX
 SG_ APP_w482_appVisionFailoverActiva : 33|1@1+ (1,0) [0|1] "" Vector__XXX
 SG_ APP_w483_apbVisionFailoverActiva : 34|1@1+ (1,0) [0|1] "" Vector__XXX

BO_ 1482 APSB_alertLog: 8 APSB
 SG_ APSB_alertID M : 0|14@1+ (1,0) [0|16383] "" Vector__XXX
 SG_ APSB_alertSource : 14|1@1+ (1,0) [0|1] "" Vector__XXX
 SG_ APSB_alertState : 15|1@1+ (1,0) [0|1] "" Vector__XXX
 SG_ APSB_sw010_a04calibNotDone m10 : 16|1@1+ (1,0) [0|1] "" Vector__XXX
 SG_ APSB_sw010_a05calibReqd m10 : 17|1@1+ (1,0) [0|1] "" Vector__XXX
 SG_ APSB_sw010_a06calibNotOK m10 : 18|1@1+ (1,0) [0|1] "" Vector__XXX
 SG_ APSB_sw010_a08PlantMode m10 : 19|1@1+ (1,0) [0|1] "" Vector__XXX
 SG_ APSB_sw010_HorizontalMisalignmen m10 : 20|16@1+ (0.00137332,-45) [-45|45.0005262] "" Vector__XXX
 SG_ APSB_sw010_VerticalMisalignment m10 : 36|10@1+ (0.087977,-45) [-45|45.000471] "" Vector__XXX
 SG_ APSB_sw010_unusedBits m10 : 46|2@1+ (1,0) [0|3] "" Vector__XXX
 SG_ APSB_sw010_VmaPlausibility m10 : 48|16@1+ (1.52587890625e-05,0) [0|0.999984741211] "" Vector__XXX
 SG_ APSB_sw019_taskId m19 : 16|8@1+ (1,0) [0|255] "" Vector__XXX
 SG_ APSB_sw019_numFreeBytes m19 : 24|8@1+ (1,-191) [-191|64] "" Vector__XXX
 SG_ APSB_sw019_timeStamp m19 : 32|32@1+ (1,0) [0|4294967295] "" Vector__XXX
 SG_ APSB_sw020_unusedW0 m20 : 16|16@1+ (1,0) [0|65535] "" Vector__XXX
 SG_ APSB_sw020_unusedW1 m20 : 32|16@1+ (1,0) [0|65535] "" Vector__XXX
 SG_ APSB_sw020_unusedW2 m20 : 48|16@1+ (1,0) [0|65535] "" Vector__XXX
 SG_ APSB_sw021_tempSensorId m21 : 16|8@1+ (1,0) [0|255] "" Vector__XXX
 SG_ APSB_sw021_minThreshold m21 : 24|8@1- (1,0) [-128|127] "" Vector__XXX
 SG_ APSB_sw021_maxThreshold m21 : 32|8@1- (1,0) [-128|127] "" Vector__XXX
 SG_ APSB_sw021_currentTemperature m21 : 40|8@1- (1,0) [-128|127] "" Vector__XXX
 SG_ APSB_sw021_unusedWord m21 : 48|16@1+ (1,0) [0|65535] "" Vector__XXX
 SG_ APSB_sw024_Task_ID m24 : 16|4@1+ (1,0) [0|15] "" Vector__XXX
 SG_ APSB_sw024_numVirtualLaneVeh m24 : 20|4@1+ (1,0) [0|15] "" Vector__XXX
 SG_ APSB_sw024_currentVehicleApp m24 : 24|8@1+ (1,0) [0|255] "" Vector__XXX
 SG_ APSB_sw024_taskProgramCounter m24 : 32|32@1+ (1,0) [0|4294967295] "" Vector__XXX
 SG_ APSB_sw027_JTAG_Reset m27 : 16|1@1+ (1,0) [0|1] "" Vector__XXX
 SG_ APSB_sw027_Core_Reset m27 : 17|1@1+ (1,0) [0|1] "" Vector__XXX
 SG_ APSB_sw027_Unused_Bit_0 m27 : 18|1@1+ (1,0) [0|1] "" Vector__XXX
 SG_ APSB_sw027_CPU_Checkstop_Error m27 : 19|1@1+ (1,0) [0|1] "" Vector__XXX
 SG_ APSB_sw027_PLL_0_Failure m27 : 20|1@1+ (1,0) [0|1] "" Vector__XXX
 SG_ APSB_sw027_Clock_Monitor_0_Low m27 : 21|1@1+ (1,0) [0|1] "" Vector__XXX
 SG_ APSB_sw027_Clock_Monitor_0_Off m27 : 22|1@1+ (1,0) [0|1] "" Vector__XXX
 SG_ APSB_sw027_LVD_4v5 m27 : 23|1@1+ (1,0) [0|1] "" Vector__XXX
 SG_ APSB_sw027_Flash_Fatal_Error m27 : 24|1@1+ (1,0) [0|1] "" Vector__XXX
 SG_ APSB_sw027_PLL_1_Failure m27 : 25|1@1+ (1,0) [0|1] "" Vector__XXX
 SG_ APSB_sw027_Unused_Bit_1 m27 : 26|1@1+ (1,0) [0|1] "" Vector__XXX
 SG_ APSB_sw027_f_PLL_1_Off m27 : 27|1@1+ (1,0) [0|1] "" Vector__XXX
 SG_ APSB_sw027_Unused_Nibble m27 : 28|4@1+ (1,0) [0|15] "" Vector__XXX
 SG_ APSB_sw027_LVD_1v2 m27 : 32|1@1+ (1,0) [0|1] "" Vector__XXX
 SG_ APSB_sw027_Unused_Bit_2 m27 : 33|1@1+ (1,0) [0|1] "" Vector__XXX
 SG_ APSB_sw027_Watchdog m27 : 34|1@1+ (1,0) [0|1] "" Vector__XXX
 SG_ APSB_sw027_Unused_Bit_3 m27 : 35|1@1+ (1,0) [0|1] "" Vector__XXX
 SG_ APSB_sw027_LVD_2v7_VREG m27 : 36|1@1+ (1,0) [0|1] "" Vector__XXX
 SG_ APSB_sw027_LVD_2v7_Flash m27 : 37|1@1+ (1,0) [0|1] "" Vector__XXX
 SG_ APSB_sw027_LVD_2v7_IO m27 : 38|1@1+ (1,0) [0|1] "" Vector__XXX
 SG_ APSB_sw027_Unused_Bit_4 m27 : 39|1@1+ (1,0) [0|1] "" Vector__XXX
 SG_ APSB_sw027_Unused_Byte m27 : 40|8@1+ (1,0) [0|255] "" Vector__XXX
 SG_ APSB_sw027_ESR0 m27 : 48|1@1+ (1,0) [0|1] "" Vector__XXX
 SG_ APSB_sw027_ESR1 m27 : 49|1@1+ (1,0) [0|1] "" Vector__XXX
 SG_ APSB_sw027_SW m27 : 50|1@1+ (1,0) [0|1] "" Vector__XXX
 SG_ APSB_sw027_STM0 m27 : 51|1@1+ (1,0) [0|1] "" Vector__XXX
 SG_ APSB_sw027_STM1 m27 : 52|1@1+ (1,0) [0|1] "" Vector__XXX
 SG_ APSB_sw027_STM2 m27 : 53|1@1+ (1,0) [0|1] "" Vector__XXX
 SG_ APSB_sw027_CBS_SYSTEM m27 : 54|1@1+ (1,0) [0|1] "" Vector__XXX
 SG_ APSB_sw027_CBS_DEBUG m27 : 55|1@1+ (1,0) [0|1] "" Vector__XXX
 SG_ APSB_sw027_CBS_APP m27 : 56|1@1+ (1,0) [0|1] "" Vector__XXX
 SG_ APSB_sw027_EVR13 m27 : 57|1@1+ (1,0) [0|1] "" Vector__XXX
 SG_ APSB_sw027_EVR33 m27 : 58|1@1+ (1,0) [0|1] "" Vector__XXX
 SG_ APSB_sw027_SWD m27 : 59|1@1+ (1,0) [0|1] "" Vector__XXX
 SG_ APSB_sw027_STDBY_WDG m27 : 60|1@1+ (1,0) [0|1] "" Vector__XXX
 SG_ APSB_sw027_PORST m27 : 61|1@1+ (1,0) [0|1] "" Vector__XXX
 SG_ APSB_sw027_Unused_word m27 : 62|2@1+ (1,0) [0|3] "" Vector__XXX
 SG_ APSB_sw030_heaterState m30 : 16|8@1+ (1,0) [0|255] "" Vector__XXX
 SG_ APSB_sw030_unusedByte m30 : 24|8@1+ (1,0) [0|255] "" Vector__XXX
 SG_ APSB_sw030_unusedW0 m30 : 32|16@1+ (1,0) [0|65535] "" Vector__XXX
 SG_ APSB_sw030_unusedW1 m30 : 48|16@1+ (1,0) [0|65535] "" Vector__XXX
 SG_ APSB_sw033_carConfig m33 : 16|1@1+ (1,0) [0|1] "" Vector__XXX
 SG_ APSB_sw033_chNm m33 : 17|1@1+ (1,0) [0|1] "" Vector__XXX
 SG_ APSB_sw033_vin m33 : 18|1@1+ (1,0) [0|1] "" Vector__XXX
 SG_ APSB_sw033_carState m33 : 19|1@1+ (1,0) [0|1] "" Vector__XXX
 SG_ APSB_sw034_sccmMia m34 : 16|8@1+ (1,0) [0|255] "" Vector__XXX
 SG_ APSB_sw034_unusedByte m34 : 24|8@1+ (1,0) [0|255] "" Vector__XXX
 SG_ APSB_sw034_unusedW0 m34 : 32|16@1+ (1,0) [0|65535] "" Vector__XXX
 SG_ APSB_sw034_unusedW1 m34 : 48|16@1+ (1,0) [0|65535] "" Vector__XXX
 SG_ APSB_sw035_wheelSpeeds m35 : 16|1@1+ (1,0) [0|1] "" Vector__XXX
 SG_ APSB_sw035_status m35 : 17|1@1+ (1,0) [0|1] "" Vector__XXX
 SG_ APSB_sw035_wheelRotation m35 : 18|1@1+ (1,0) [0|1] "" Vector__XXX
 SG_ APSB_sw035_redundantBrakingStatu m35 : 19|1@1+ (1,0) [0|1] "" Vector__XXX
 SG_ APSB_sw036_bdyMia m36 : 16|8@1+ (1,0) [0|255] "" Vector__XXX
 SG_ APSB_sw036_unusedByte m36 : 24|8@1+ (1,0) [0|255] "" Vector__XXX
 SG_ APSB_sw036_unusedW0 m36 : 32|16@1+ (1,0) [0|65535] "" Vector__XXX
 SG_ APSB_sw036_unusedW1 m36 : 48|16@1+ (1,0) [0|65535] "" Vector__XXX
 SG_ APSB_sw039_sdm_rcm_Mia m39 : 16|8@1+ (1,0) [0|255] "" Vector__XXX
 SG_ APSB_sw039_unusedByte m39 : 24|8@1+ (1,0) [0|255] "" Vector__XXX
 SG_ APSB_sw039_unusedW0 m39 : 32|16@1+ (1,0) [0|65535] "" Vector__XXX
 SG_ APSB_sw039_unusedW1 m39 : 48|16@1+ (1,0) [0|65535] "" Vector__XXX
 SG_ APSB_sw045_radMia m45 : 16|8@1+ (1,0) [0|255] "" Vector__XXX
 SG_ APSB_sw045_unusedByte m45 : 24|8@1+ (1,0) [0|255] "" Vector__XXX
 SG_ APSB_sw045_unusedW0 m45 : 32|16@1+ (1,0) [0|65535] "" Vector__XXX
 SG_ APSB_sw045_unusedW1 m45 : 48|16@1+ (1,0) [0|65535] "" Vector__XXX
 SG_ APSB_sw048_swAssert m48 : 16|1@1+ (1,0) [0|1] "" Vector__XXX
 SG_ APSB_sw048_thermalIssue m48 : 17|1@1+ (1,0) [0|1] "" Vector__XXX
 SG_ APSB_sw048_powerIssue m48 : 18|1@1+ (1,0) [0|1] "" Vector__XXX
 SG_ APSB_sw048_stackOverflow m48 : 19|1@1+ (1,0) [0|1] "" Vector__XXX
 SG_ APSB_sw048_checkStop m48 : 20|1@1+ (1,0) [0|1] "" Vector__XXX
 SG_ APSB_sw048_ecuWatchdog m48 : 21|1@1+ (1,0) [0|1] "" Vector__XXX
 SG_ APSB_sw048_ecuReset m48 : 22|1@1+ (1,0) [0|1] "" Vector__XXX
 SG_ APSB_sw048_radcVersionMismatch m48 : 23|1@1+ (1,0) [0|1] "" Vector__XXX
 SG_ APSB_sw048_radcCalibration m48 : 24|1@1+ (1,0) [0|1] "" Vector__XXX
 SG_ APSB_sw048_radcMia m48 : 25|1@1+ (1,0) [0|1] "" Vector__XXX
 SG_ APSB_sw048_eyeQVersionMismatch m48 : 26|1@1+ (1,0) [0|1] "" Vector__XXX
 SG_ APSB_sw048_camIssue m48 : 27|1@1+ (1,0) [0|1] "" Vector__XXX
 SG_ APSB_sw048_parkerIssue m48 : 28|1@1+ (1,0) [0|1] "" Vector__XXX
 SG_ APSB_sw048_prolongedUiMia m48 : 29|1@1+ (1,0) [0|1] "" Vector__XXX
 SG_ APSB_sw048_uiMiaAtBootup m48 : 30|1@1+ (1,0) [0|1] "" Vector__XXX
 SG_ APSB_sw051_a01ecuInternalPerf m51 : 16|1@1+ (1,0) [0|1] "" Vector__XXX
 SG_ APSB_sw051_a02flashPerformance m51 : 17|1@1+ (1,0) [0|1] "" Vector__XXX
 SG_ APSB_sw051_a03vBatHigh m51 : 18|1@1+ (1,0) [0|1] "" Vector__XXX
 SG_ APSB_sw051_a09configMismatch m51 : 19|1@1+ (1,0) [0|1] "" Vector__XXX
 SG_ APSB_sw051_a52radomeHtrInop m51 : 20|1@1+ (1,0) [0|1] "" Vector__XXX
 SG_ APSB_sw051_unused m51 : 21|3@1+ (1,0) [0|7] "" Vector__XXX
 SG_ APSB_sw051_SCUTemperature m51 : 24|8@1- (1,0) [-128|127] "" Vector__XXX
 SG_ APSB_sw051_HWFail m51 : 32|1@1+ (1,0) [0|1] "" Vector__XXX
 SG_ APSB_sw051_SGUFail m51 : 33|1@1+ (1,0) [0|1] "" Vector__XXX
 SG_ APSB_sw051_unusedBits m51 : 34|6@1+ (1,0) [0|63] "" Vector__XXX
 SG_ APSB_sw051_unusedB0 m51 : 40|8@1+ (1,0) [0|255] "" Vector__XXX
 SG_ APSB_sw051_unusedW1 m51 : 48|16@1+ (1,0) [0|65535] "" Vector__XXX
 SG_ APSB_sw052_a07sensorBlinded m52 : 16|1@1+ (1,0) [0|1] "" Vector__XXX
 SG_ APSB_sw052_sensorDirty m52 : 17|1@1+ (1,0) [0|1] "" Vector__XXX
 SG_ APSB_sw052_HWFail m52 : 18|1@1+ (1,0) [0|1] "" Vector__XXX
 SG_ APSB_sw052_overTemperature m52 : 19|1@1+ (1,0) [0|1] "" Vector__XXX
 SG_ APSB_sw052_underTemperature m52 : 20|1@1+ (1,0) [0|1] "" Vector__XXX
 SG_ APSB_sw052_chirpError m52 : 21|1@1+ (1,0) [0|1] "" Vector__XXX
 SG_ APSB_sw052_rspError m52 : 22|1@1+ (1,0) [0|1] "" Vector__XXX
 SG_ APSB_sw052_sensorBlocked m52 : 23|1@1+ (1,0) [0|1] "" Vector__XXX
 SG_ APSB_sw053_a10canBusOff m53 : 16|1@1+ (1,0) [0|1] "" Vector__XXX
 SG_ APSB_sw053_a11bdyMIA m53 : 17|1@1+ (1,0) [0|1] "" Vector__XXX
 SG_ APSB_sw053_a12espMIA m53 : 18|1@1+ (1,0) [0|1] "" Vector__XXX
 SG_ APSB_sw053_a13gtwMIA m53 : 19|1@1+ (1,0) [0|1] "" Vector__XXX
 SG_ APSB_sw053_a14sccmMIA m53 : 20|1@1+ (1,0) [0|1] "" Vector__XXX
 SG_ APSB_sw053_a15adasMIA m53 : 21|1@1+ (1,0) [0|1] "" Vector__XXX
 SG_ APSB_sw053_a16bdyInvalidCount m53 : 22|1@1+ (1,0) [0|1] "" Vector__XXX
 SG_ APSB_sw053_a17adasInvalidCount m53 : 23|1@1+ (1,0) [0|1] "" Vector__XXX
 SG_ APSB_sw053_a18espInvalidCount m53 : 24|1@1+ (1,0) [0|1] "" Vector__XXX
 SG_ APSB_sw053_a19sccmInvalidCount m53 : 25|1@1+ (1,0) [0|1] "" Vector__XXX
 SG_ APSB_sw053_a20bdyInvalidChkSm m53 : 26|1@1+ (1,0) [0|1] "" Vector__XXX
 SG_ APSB_sw053_a21espInvalidChkSm m53 : 27|1@1+ (1,0) [0|1] "" Vector__XXX
 SG_ APSB_sw053_a22sccmInvalidChkSm m53 : 28|1@1+ (1,0) [0|1] "" Vector__XXX
 SG_ APSB_sw053_a23sccmInvalidChkSm m53 : 29|1@1+ (1,0) [0|1] "" Vector__XXX
 SG_ APSB_sw053_a24absValidity m53 : 30|1@1+ (1,0) [0|1] "" Vector__XXX
 SG_ APSB_sw053_a25ambTValidity m53 : 31|1@1+ (1,0) [0|1] "" Vector__XXX
 SG_ APSB_sw053_a26brakeValidity m53 : 32|1@1+ (1,0) [0|1] "" Vector__XXX
 SG_ APSB_sw053_a27CntryCdValidity m53 : 33|1@1+ (1,0) [0|1] "" Vector__XXX
 SG_ APSB_sw053_a28espValidity m53 : 34|1@1+ (1,0) [0|1] "" Vector__XXX
 SG_ APSB_sw053_a29longAccOffValidity m53 : 35|1@1+ (1,0) [0|1] "" Vector__XXX
 SG_ APSB_sw053_a30longAccValidity m53 : 36|1@1+ (1,0) [0|1] "" Vector__XXX
 SG_ APSB_sw053_a31odoValidity m53 : 37|1@1+ (1,0) [0|1] "" Vector__XXX
 SG_ APSB_sw053_a32gearValidity m53 : 38|1@1+ (1,0) [0|1] "" Vector__XXX
 SG_ APSB_sw053_a33steerAngValidity m53 : 39|1@1+ (1,0) [0|1] "" Vector__XXX
 SG_ APSB_sw053_a34steerAngSpdValidit m53 : 40|1@1+ (1,0) [0|1] "" Vector__XXX
 SG_ APSB_sw053_a35indctrValidity m53 : 41|1@1+ (1,0) [0|1] "" Vector__XXX
 SG_ APSB_sw053_a36vehStndStllValidty m53 : 42|1@1+ (1,0) [0|1] "" Vector__XXX
 SG_ APSB_sw053_a37vinValidity m53 : 43|1@1+ (1,0) [0|1] "" Vector__XXX
 SG_ APSB_sw053_a38whlRotValidity m53 : 44|1@1+ (1,0) [0|1] "" Vector__XXX
 SG_ APSB_sw053_a39whlSpdValidity m53 : 45|1@1+ (1,0) [0|1] "" Vector__XXX
 SG_ APSB_sw053_a40whlStndStllValidty m53 : 46|1@1+ (1,0) [0|1] "" Vector__XXX
 SG_ APSB_sw053_a41wiperValidity m53 : 47|1@1+ (1,0) [0|1] "" Vector__XXX
 SG_ APSB_sw053_a42xwdValidity m53 : 48|1@1+ (1,0) [0|1] "" Vector__XXX
 SG_ APSB_sw053_a43yawOffValidity m53 : 49|1@1+ (1,0) [0|1] "" Vector__XXX
 SG_ APSB_sw053_a44yawValidity m53 : 50|1@1+ (1,0) [0|1] "" Vector__XXX
 SG_ APSB_sw053_a48steerAngOffSanity m53 : 51|1@1+ (1,0) [0|1] "" Vector__XXX
 SG_ APSB_sw053_a49tireSizeSanity m53 : 52|1@1+ (1,0) [0|1] "" Vector__XXX
 SG_ APSB_sw053_a50velocitySanity m53 : 53|1@1+ (1,0) [0|1] "" Vector__XXX
 SG_ APSB_sw053_a51yawSanity m53 : 54|1@1+ (1,0) [0|1] "" Vector__XXX
 SG_ APSB_sw053_a53espmodValidity m53 : 55|1@1+ (1,0) [0|1] "" Vector__XXX
 SG_ APSB_sw053_a54gtwmodValidity m53 : 56|1@1+ (1,0) [0|1] "" Vector__XXX
 SG_ APSB_sw053_a55stwmodValidity m53 : 57|1@1+ (1,0) [0|1] "" Vector__XXX
 SG_ APSB_sw053_a56bcmodValidity m53 : 58|1@1+ (1,0) [0|1] "" Vector__XXX
 SG_ APSB_sw053_a57dimodValidity m53 : 59|1@1+ (1,0) [0|1] "" Vector__XXX
 SG_ APSB_sw053_a59drmiInvalidChkSm m53 : 60|1@1+ (1,0) [0|1] "" Vector__XXX
 SG_ APSB_sw053_a60drmiInvalidCount m53 : 61|1@1+ (1,0) [0|1] "" Vector__XXX
 SG_ APSB_sw053_a61radPositionMismatc m53 : 62|1@1+ (1,0) [0|1] "" Vector__XXX
 SG_ APSB_sw053_a62strRackMismatch m53 : 63|1@1+ (1,0) [0|1] "" Vector__XXX
 SG_ APSB_sw055_detectedRadcVersion m55 : 16|32@1+ (1,0) [0|4294967295] "" Vector__XXX
 SG_ APSB_sw055_expectedCrcLsw m55 : 48|16@1+ (1,0) [0|65535] "" Vector__XXX
 SG_ APSB_sw056_diMia m56 : 16|8@1+ (1,0) [0|255] "" Vector__XXX
 SG_ APSB_sw056_unusedByte m56 : 24|8@1+ (1,0) [0|255] "" Vector__XXX
 SG_ APSB_sw056_unusedW0 m56 : 32|16@1+ (1,0) [0|65535] "" Vector__XXX
 SG_ APSB_sw056_unusedW1 m56 : 48|16@1+ (1,0) [0|65535] "" Vector__XXX
 SG_ APSB_sw058_epbMia m58 : 16|8@1+ (1,0) [0|255] "" Vector__XXX
 SG_ APSB_sw058_unusedByte m58 : 24|8@1+ (1,0) [0|255] "" Vector__XXX
 SG_ APSB_sw058_unusedW0 m58 : 32|16@1+ (1,0) [0|65535] "" Vector__XXX
 SG_ APSB_sw058_unusedW1 m58 : 48|16@1+ (1,0) [0|65535] "" Vector__XXX
 SG_ APSB_sw059_sdiFront m59 : 16|1@1+ (1,0) [0|1] "" Vector__XXX
 SG_ APSB_sw059_sdiRear m59 : 17|1@1+ (1,0) [0|1] "" Vector__XXX
 SG_ APSB_sw059_status m59 : 18|1@1+ (1,0) [0|1] "" Vector__XXX
 SG_ APSB_sw059_sensorStatusFront m59 : 19|1@1+ (1,0) [0|1] "" Vector__XXX
 SG_ APSB_sw059_pasFrontMiddle m59 : 20|1@1+ (1,0) [0|1] "" Vector__XXX
 SG_ APSB_sw059_sensorStatusRear m59 : 21|1@1+ (1,0) [0|1] "" Vector__XXX
 SG_ APSB_sw059_pasRearMiddle m59 : 22|1@1+ (1,0) [0|1] "" Vector__XXX
 SG_ APSB_sw059_pscStatus m59 : 23|1@1+ (1,0) [0|1] "" Vector__XXX
 SG_ APSB_sw059_pscVehSlot m59 : 24|1@1+ (1,0) [0|1] "" Vector__XXX
 SG_ APSB_sw059_status2 m59 : 25|1@1+ (1,0) [0|1] "" Vector__XXX
 SG_ APSB_sw059_oloDict m59 : 26|1@1+ (1,0) [0|1] "" Vector__XXX
 SG_ APSB_sw059_oocStatus m59 : 27|1@1+ (1,0) [0|1] "" Vector__XXX
 SG_ APSB_sw061_states m61 : 16|1@1+ (1,0) [0|1] "" Vector__XXX
 SG_ APSB_sw063_expectedMajorVer m63 : 16|8@1+ (1,0) [0|255] "" Vector__XXX
 SG_ APSB_sw063_detectedMajorVer m63 : 24|8@1+ (1,0) [0|255] "" Vector__XXX
 SG_ APSB_sw063_expectedMinorVer m63 : 32|8@1+ (1,0) [0|255] "" Vector__XXX
 SG_ APSB_sw063_detectedMinorVer m63 : 40|8@1+ (1,0) [0|255] "" Vector__XXX
 SG_ APSB_sw063_expectedSubMinorVer m63 : 48|8@1+ (1,0) [0|255] "" Vector__XXX
 SG_ APSB_sw063_detectedSubMinorVer m63 : 56|8@1+ (1,0) [0|255] "" Vector__XXX
 SG_ APSB_sw064_sysStatus m64 : 16|1@1+ (1,0) [0|1] "" Vector__XXX
 SG_ APSB_sw064_status m64 : 17|1@1+ (1,0) [0|1] "" Vector__XXX
 SG_ APSB_sw070_currTireFitment m70 : 16|3@1+ (1,0) [0|7] "" Vector__XXX
 SG_ APSB_sw070_lastTireFitment m70 : 19|3@1+ (1,0) [0|7] "" Vector__XXX
 SG_ APSB_sw070_diGear m70 : 24|3@1+ (1,0) [0|7] "" Vector__XXX
 SG_ APSB_sw070_driveRail m70 : 27|1@1+ (1,0) [0|1] "" Vector__XXX
 SG_ APSB_sw070_accRail m70 : 28|1@1+ (1,0) [0|1] "" Vector__XXX
 SG_ APSB_sw070_temperature m70 : 32|8@1+ (0.5,-40) [-40|87.5] "" Vector__XXX
 SG_ APSB_sw070_currentSpeed m70 : 40|12@1+ (0.1,-204.7) [-204.7|204.8] "" Vector__XXX
 SG_ APSB_sw071_selfParkType m71 : 16|4@1+ (1,0) [0|15] "" Vector__XXX
 SG_ APSB_sw071_endPosX m71 : 20|10@1+ (0.05,-25.6) [-25.6|25.55] "" Vector__XXX
 SG_ APSB_sw071_endPosY m71 : 30|10@1+ (0.05,-25.6) [-25.6|25.55] "" Vector__XXX
 SG_ APSB_sw071_roadClass m71 : 40|3@1+ (1,0) [0|7] "" Vector__XXX
 SG_ APSB_sw071_driverPresent m71 : 43|1@1+ (1,0) [0|1] "" Vector__XXX
 SG_ APSB_sw071_airSuspension m71 : 44|3@1+ (1,0) [0|7] "" Vector__XXX
 SG_ APSB_sw071_temperature m71 : 48|8@1+ (0.5,-40) [-40|87.5] "" Vector__XXX
 SG_ APSB_sw071_activationType m71 : 56|2@1+ (1,0) [0|3] "" Vector__XXX
 SG_ APSB_sw072_vehicleX m72 : 16|10@1+ (0.05,-25.6) [-25.6|25.55] "" Vector__XXX
 SG_ APSB_sw072_vehicleY m72 : 26|10@1+ (0.05,-25.6) [-25.6|25.55] "" Vector__XXX
 SG_ APSB_sw072_vehicleHeading m72 : 36|10@1+ (0.005,-2.56) [-2.56|2.555] "" Vector__XXX
 SG_ APSB_sw072_endDistance m72 : 48|8@1+ (1,0) [0|255] "" Vector__XXX
 SG_ APSB_sw072_guidanceComplete m72 : 56|1@1+ (1,0) [0|1] "" Vector__XXX
 SG_ APSB_sw072_guidanceRunaway m72 : 57|1@1+ (1,0) [0|1] "" Vector__XXX
 SG_ APSB_sw072_guidanceTimer m72 : 58|1@1+ (1,0) [0|1] "" Vector__XXX
 SG_ APSB_sw072_handlePress m72 : 59|1@1+ (1,0) [0|1] "" Vector__XXX
 SG_ APSB_sw072_keyfobPress m72 : 60|1@1+ (1,0) [0|1] "" Vector__XXX
 SG_ APSB_sw072_garageOpened m72 : 61|1@1+ (1,0) [0|1] "" Vector__XXX
 SG_ APSB_sw072_userTimeout m72 : 62|1@1+ (1,0) [0|1] "" Vector__XXX
 SG_ APSB_sw075_scMia m75 : 16|8@1+ (1,0) [0|255] "" Vector__XXX
 SG_ APSB_sw075_unusedByte m75 : 24|8@1+ (1,0) [0|255] "" Vector__XXX
 SG_ APSB_sw075_unusedW0 m75 : 32|16@1+ (1,0) [0|65535] "" Vector__XXX
 SG_ APSB_sw075_unusedW1 m75 : 48|16@1+ (1,0) [0|65535] "" Vector__XXX
 SG_ APSB_sw077_oocDistance m77 : 16|9@1+ (1,0) [0|511] "" Vector__XXX
 SG_ APSB_sw077_oocConfidence m77 : 25|7@1+ (1,0) [0|127] "" Vector__XXX
 SG_ APSB_sw077_oocCollisionSide m77 : 32|3@1+ (1,0) [0|7] "" Vector__XXX
 SG_ APSB_sw077_oocHeight m77 : 35|2@1+ (1,0) [0|3] "" Vector__XXX
 SG_ APSB_sw077_vehicleSpeed m77 : 37|10@1+ (0.05,-25) [-25|26.15] "" Vector__XXX
 SG_ APSB_sw077_oocUntrackedTime m77 : 48|6@1+ (0.1,0) [0|6.3] "" Vector__XXX
 SG_ APSB_sw077_oocOffCourseDist_cm m77 : 54|10@1- (1,0) [-512|511] "" Vector__XXX
 SG_ APSB_sw081_radarDistance m81 : 16|8@1+ (0.0625,0) [0|15.9375] "" Vector__XXX
 SG_ APSB_sw081_radarTTC m81 : 24|8@1+ (0.02,0) [0|5.1] "" Vector__XXX
 SG_ APSB_sw081_cameraDistance m81 : 32|8@1+ (0.0625,0) [0|15.9375] "" Vector__XXX
 SG_ APSB_sw081_cameraTTC m81 : 40|8@1+ (0.02,0) [0|5.1] "" Vector__XXX
 SG_ APSB_sw081_pedalPosition m81 : 48|7@1+ (1,0) [0|127] "" Vector__XXX
 SG_ APSB_sw129_currentVoltage m129 : 16|14@1+ (1,0) [0|16383] "" Vector__XXX
 SG_ APSB_sw129_maxThreshold m129 : 30|13@1+ (1,50) [50|8241] "" Vector__XXX
 SG_ APSB_sw129_minThreshold m129 : 43|13@1+ (1,0) [0|8191] "" Vector__XXX
 SG_ APSB_sw129_powerSequnceError m129 : 56|1@1+ (1,0) [0|1] "" Vector__XXX
 SG_ APSB_sw129_railControl m129 : 57|1@1+ (1,0) [0|1] "" Vector__XXX
 SG_ APSB_sw129_railID m129 : 58|6@1+ (1,0) [0|63] "" Vector__XXX
 SG_ APSB_sw130_currentTemperature m130 : 16|8@1- (1,0) [-128|127] "" Vector__XXX
 SG_ APSB_sw130_maxThreshold m130 : 24|8@1- (1,0) [-128|127] "" Vector__XXX
 SG_ APSB_sw130_minThreshold m130 : 32|8@1- (1,0) [-128|127] "" Vector__XXX
 SG_ APSB_sw130_tempSensorId m130 : 40|6@1+ (1,0) [0|63] "" Vector__XXX
 SG_ APSB_sw130_shouldForceApPowerOn m130 : 46|1@1+ (1,0) [0|1] "" Vector__XXX
 SG_ APSB_sw130_shouldBlockOkToPowerA m130 : 47|1@1+ (1,0) [0|1] "" Vector__XXX
 SG_ APSB_sw132_mismatchType m132 : 16|1@1+ (1,0) [0|1] "" Vector__XXX
 SG_ APSB_sw132_actualHash m132 : 24|24@1+ (1,0) [0|16777215] "" Vector__XXX
 SG_ APSB_sw132_expectedHash m132 : 48|16@1+ (1,0) [0|65535] "" Vector__XXX
 SG_ APSB_sw133_failedInitStep m133 : 16|8@1+ (1,0) [0|255] "" Vector__XXX
 SG_ APSB_sw133_switchInReset m133 : 24|1@1+ (1,0) [0|1] "" Vector__XXX
 SG_ APSB_sw133_phyIsNotRMIIMode m133 : 25|1@1+ (1,0) [0|1] "" Vector__XXX
 SG_ APSB_sw133_phyInterruptStorm m133 : 26|1@1+ (1,0) [0|1] "" Vector__XXX
 SG_ APSB_sw133_switchEthernetInterLi m133 : 27|1@1+ (1,0) [0|1] "" Vector__XXX
 SG_ APSB_sw133_ethSwitchReadFwVerFai m133 : 28|1@1+ (1,0) [0|1] "" Vector__XXX
 SG_ APSB_sw133_ethSwitchFailedToBoot m133 : 29|1@1+ (1,0) [0|1] "" Vector__XXX
 SG_ APSB_sw133_ethSwitchTimedoutUpda m133 : 30|1@1+ (1,0) [0|1] "" Vector__XXX
 SG_ APSB_sw133_ethSwitchMcuLinkFailo m133 : 31|1@1+ (1,0) [0|1] "" Vector__XXX
 SG_ APSB_sw133_ethSwitchMcuLinkDupli m133 : 32|1@1+ (1,0) [0|1] "" Vector__XXX
 SG_ APSB_sw133_ethSwitchMcuLinkDisco m133 : 33|1@1+ (1,0) [0|1] "" Vector__XXX
 SG_ APSB_sw133_unused m133 : 34|30@1+ (1,0) [0|1073741823] "" Vector__XXX
 SG_ APSB_sw134_appCamCalibStatus m134 : 16|1@1+ (1,0) [0|1] "" Vector__XXX
 SG_ APSB_sw134_appCameraLux m134 : 17|1@1+ (1,0) [0|1] "" Vector__XXX
 SG_ APSB_sw134_appInfo m134 : 18|1@1+ (1,0) [0|1] "" Vector__XXX
 SG_ APSB_sw134_appStatus m134 : 19|1@1+ (1,0) [0|1] "" Vector__XXX
 SG_ APSB_sw134_dasAutonomyControlPar m134 : 20|1@1+ (1,0) [0|1] "" Vector__XXX
 SG_ APSB_sw134_dasAutonomyControlVeh m134 : 21|1@1+ (1,0) [0|1] "" Vector__XXX
 SG_ APSB_sw134_dasBodyControlsVEH m134 : 22|1@1+ (1,0) [0|1] "" Vector__XXX
 SG_ APSB_sw134_dasControl m134 : 23|1@1+ (1,0) [0|1] "" Vector__XXX
 SG_ APSB_sw134_dasControlPty m134 : 24|1@1+ (1,0) [0|1] "" Vector__XXX
 SG_ APSB_sw134_dasIntSafetyFrontPty m134 : 25|1@1+ (1,0) [0|1] "" Vector__XXX
 SG_ APSB_sw134_dasLanes m134 : 26|1@1+ (1,0) [0|1] "" Vector__XXX
 SG_ APSB_sw134_dasObject m134 : 27|1@1+ (1,0) [0|1] "" Vector__XXX
 SG_ APSB_sw134_dasPscControl m134 : 28|1@1+ (1,0) [0|1] "" Vector__XXX
 SG_ APSB_sw134_dasStatus m134 : 29|1@1+ (1,0) [0|1] "" Vector__XXX
 SG_ APSB_sw134_dasStatus2 m134 : 30|1@1+ (1,0) [0|1] "" Vector__XXX
 SG_ APSB_sw134_dasSteeringControl m134 : 31|1@1+ (1,0) [0|1] "" Vector__XXX
 SG_ APSB_sw134_dasVisualDebug m134 : 32|1@1+ (1,0) [0|1] "" Vector__XXX
 SG_ APSB_sw134_dasSteeringControlPty m134 : 33|1@1+ (1,0) [0|1] "" Vector__XXX
 SG_ APSB_sw134_dasChNm m134 : 34|1@1+ (1,0) [0|1] "" Vector__XXX
 SG_ APSB_sw134_appSummon m134 : 35|1@1+ (1,0) [0|1] "" Vector__XXX
 SG_ APSB_sw134_appEnvironment m134 : 36|1@1+ (1,0) [0|1] "" Vector__XXX
 SG_ APSB_sw134_dasStatusPty m134 : 37|1@1+ (1,0) [0|1] "" Vector__XXX
 SG_ APSB_sw134_dasStatus2Pty m134 : 38|1@1+ (1,0) [0|1] "" Vector__XXX
 SG_ APSB_sw134_dasMatrixHighBeamRqVE m134 : 39|1@1+ (1,0) [0|1] "" Vector__XXX
 SG_ APSB_sw134_dasMatrixBendAngleRqP m134 : 40|1@1+ (1,0) [0|1] "" Vector__XXX
 SG_ APSB_sw134_dasBodyControls2VEH m134 : 41|1@1+ (1,0) [0|1] "" Vector__XXX
 SG_ APSB_sw134_dasRedundantBrakingCo m134 : 42|1@1+ (1,0) [0|1] "" Vector__XXX
 SG_ APSB_sw134_dasRedundantBrak_0001 m134 : 43|1@1+ (1,0) [0|1] "" Vector__XXX
 SG_ APSB_sw134_timeSinceLastMsg m134 : 48|16@1+ (1,0) [0|65535] "" Vector__XXX
 SG_ APSB_sw135_appCriticalReason m135 : 16|4@1+ (1,0) [0|15] "" Vector__XXX
 SG_ APSB_sw135_appTimesyncStatus m135 : 24|32@1+ (1,0) [0|4294967295] "" Vector__XXX
 SG_ APSB_sw136_gpsCommIrrecoverable m136 : 16|1@1+ (1,0) [0|1] "" Vector__XXX
 SG_ APSB_sw136_fusionIrrecoverable m136 : 17|1@1+ (1,0) [0|1] "" Vector__XXX
 SG_ APSB_sw136_antennaUnplugged m136 : 18|1@1+ (1,0) [0|1] "" Vector__XXX
 SG_ APSB_sw136_badgpsfix m136 : 19|1@1+ (1,0) [0|1] "" Vector__XXX
 SG_ APSB_sw137_gpsCommMissing m137 : 16|1@1+ (1,0) [0|1] "" Vector__XXX
 SG_ APSB_sw137_gpsJunkData m137 : 17|1@1+ (1,0) [0|1] "" Vector__XXX
 SG_ APSB_sw137_gpsNMEAmissing m137 : 18|1@1+ (1,0) [0|1] "" Vector__XXX
 SG_ APSB_sw137_gpsUBXmissing m137 : 19|1@1+ (1,0) [0|1] "" Vector__XXX
 SG_ APSB_sw137_fusionModeDisabled m137 : 20|1@1+ (1,0) [0|1] "" Vector__XXX
 SG_ APSB_sw137_gpsCfgFail m137 : 21|1@1+ (1,0) [0|1] "" Vector__XXX
 SG_ APSB_sw137_esfStatusMsgMIA m137 : 22|1@1+ (1,0) [0|1] "" Vector__XXX
 SG_ APSB_sw137_wheelTickCfgMissmatch m137 : 23|1@1+ (1,0) [0|1] "" Vector__XXX
 SG_ APSB_sw137_exitTransportMode m137 : 24|1@1+ (1,0) [0|1] "" Vector__XXX
 SG_ APSB_sw137_satRejectionTimeout m137 : 25|1@1+ (1,0) [0|1] "" Vector__XXX
 SG_ APSB_sw137_gpsPPSMissing m137 : 26|1@1+ (1,0) [0|1] "" Vector__XXX
 SG_ APSB_sw138_cfgBufNull m138 : 16|1@1+ (1,0) [0|1] "" Vector__XXX
 SG_ APSB_sw138_invalidID m138 : 17|1@1+ (1,0) [0|1] "" Vector__XXX
 SG_ APSB_sw138_gpsBufferOverflow m138 : 18|1@1+ (1,0) [0|1] "" Vector__XXX
 SG_ APSB_sw138_navx5CfgFailed m138 : 19|1@1+ (1,0) [0|1] "" Vector__XXX
 SG_ APSB_sw138_mcuNMEAmsgUDPinvalid m138 : 20|1@1+ (1,0) [0|1] "" Vector__XXX
 SG_ APSB_sw138_mcuDbgMsgInvalid m138 : 21|1@1+ (1,0) [0|1] "" Vector__XXX
 SG_ APSB_sw138_mcuDbgMsgTooBig m138 : 22|1@1+ (1,0) [0|1] "" Vector__XXX
 SG_ APSB_sw138_mcuFwdNMEAfail m138 : 23|1@1+ (1,0) [0|1] "" Vector__XXX
 SG_ APSB_sw138_NMEAinvalidChecksum m138 : 24|1@1+ (1,0) [0|1] "" Vector__XXX
 SG_ APSB_sw138_unexpectedNMEAmsg m138 : 25|1@1+ (1,0) [0|1] "" Vector__XXX
 SG_ APSB_sw138_UARTbusFull m138 : 26|1@1+ (1,0) [0|1] "" Vector__XXX
 SG_ APSB_sw138_UARTframeError m138 : 27|1@1+ (1,0) [0|1] "" Vector__XXX
 SG_ APSB_sw138_UBXrxFrameTooBig m138 : 28|1@1+ (1,0) [0|1] "" Vector__XXX
 SG_ APSB_sw138_emptyValidNMEA m138 : 29|1@1+ (1,0) [0|1] "" Vector__XXX
 SG_ APSB_sw138_invalidAsciiNMEA m138 : 30|1@1+ (1,0) [0|1] "" Vector__XXX
 SG_ APSB_sw138_wheeltickUARTfault m138 : 31|1@1+ (1,0) [0|1] "" Vector__XXX
 SG_ APSB_sw138_baudrateMismatch m138 : 32|1@1+ (1,0) [0|1] "" Vector__XXX
 SG_ APSB_sw138_wheelTickInvalidSrc m138 : 33|1@1+ (1,0) [0|1] "" Vector__XXX
 SG_ APSB_sw138_UARTparityError m138 : 34|1@1+ (1,0) [0|1] "" Vector__XXX
 SG_ APSB_sw138_UARTrxFifoOverflow m138 : 35|1@1+ (1,0) [0|1] "" Vector__XXX
 SG_ APSB_sw138_UARTrxFifoUnderflow m138 : 36|1@1+ (1,0) [0|1] "" Vector__XXX
 SG_ APSB_sw138_UARTtxFifoOverflow m138 : 37|1@1+ (1,0) [0|1] "" Vector__XXX
 SG_ APSB_sw138_esfWtMsgTimeout m138 : 38|1@1+ (1,0) [0|1] "" Vector__XXX
 SG_ APSB_sw138_PFLASHReadError m138 : 39|1@1+ (1,0) [0|1] "" Vector__XXX
 SG_ APSB_sw138_PFLASHWriteError m138 : 40|1@1+ (1,0) [0|1] "" Vector__XXX
 SG_ APSB_sw138_gpsCfgNack m138 : 41|1@1+ (1,0) [0|1] "" Vector__XXX
 SG_ APSB_sw138_gpsCfgIdFail m138 : 42|6@1+ (1,0) [0|63] "" Vector__XXX
 SG_ APSB_sw138_gpsSetCfgNoAck m138 : 48|1@1+ (1,0) [0|1] "" Vector__XXX
 SG_ APSB_sw138_gpsReadCfgNoResponse m138 : 49|1@1+ (1,0) [0|1] "" Vector__XXX
 SG_ APSB_sw138_ubxErrorReported m138 : 50|1@1+ (1,0) [0|1] "" Vector__XXX
 SG_ APSB_sw140_lvPowerState m140 : 16|1@1+ (1,0) [0|1] "" Vector__XXX
 SG_ APSB_sw140_vehicleStatus m140 : 17|1@1+ (1,0) [0|1] "" Vector__XXX
 SG_ APSB_sw140_status m140 : 18|1@1+ (1,0) [0|1] "" Vector__XXX
 SG_ APSB_sw140_lighting m140 : 19|1@1+ (1,0) [0|1] "" Vector__XXX
 SG_ APSB_sw140_sensors m140 : 20|1@1+ (1,0) [0|1] "" Vector__XXX
 SG_ APSB_sw140_coolant m140 : 21|1@1+ (1,0) [0|1] "" Vector__XXX
 SG_ APSB_sw140_okToUseHighPower m140 : 22|1@1+ (1,0) [0|1] "" Vector__XXX
 SG_ APSB_sw141_inertial1 m141 : 16|1@1+ (1,0) [0|1] "" Vector__XXX
 SG_ APSB_sw141_inertial2 m141 : 17|1@1+ (1,0) [0|1] "" Vector__XXX
 SG_ APSB_sw142_speed m142 : 16|1@1+ (1,0) [0|1] "" Vector__XXX
 SG_ APSB_sw142_locStatus m142 : 17|1@1+ (1,0) [0|1] "" Vector__XXX
 SG_ APSB_sw142_locStatus2 m142 : 18|1@1+ (1,0) [0|1] "" Vector__XXX
 SG_ APSB_sw142_systemStatus m142 : 19|1@1+ (1,0) [0|1] "" Vector__XXX
 SG_ APSB_sw142_chassisControl m142 : 20|1@1+ (1,0) [0|1] "" Vector__XXX
 SG_ APSB_sw142_epbStatus m142 : 21|1@1+ (1,0) [0|1] "" Vector__XXX
 SG_ APSB_sw142_brakeSystem m142 : 22|1@1+ (1,0) [0|1] "" Vector__XXX
 SG_ APSB_sw143_status m143 : 16|1@1+ (1,0) [0|1] "" Vector__XXX
 SG_ APSB_sw143_wheelRotation m143 : 17|1@1+ (1,0) [0|1] "" Vector__XXX
 SG_ APSB_sw143_wheelSpeeds m143 : 18|1@1+ (1,0) [0|1] "" Vector__XXX
 SG_ APSB_sw143_redundantBrakingStatu m143 : 19|1@1+ (1,0) [0|1] "" Vector__XXX
 SG_ APSB_sw144_restraintStatus m144 : 16|1@1+ (1,0) [0|1] "" Vector__XXX
 SG_ APSB_sw145_restraintStatus m145 : 16|1@1+ (1,0) [0|1] "" Vector__XXX
 SG_ APSB_sw146_sysStatus m146 : 16|1@1+ (1,0) [0|1] "" Vector__XXX
 SG_ APSB_sw146_status m146 : 17|1@1+ (1,0) [0|1] "" Vector__XXX
 SG_ APSB_sw147_doorStatus m147 : 16|1@1+ (1,0) [0|1] "" Vector__XXX
 SG_ APSB_sw147_switchStatus m147 : 17|1@1+ (1,0) [0|1] "" Vector__XXX
 SG_ APSB_sw148_doorStatus m148 : 16|1@1+ (1,0) [0|1] "" Vector__XXX
 SG_ APSB_sw148_hvacStatus m148 : 17|1@1+ (1,0) [0|1] "" Vector__XXX
 SG_ APSB_sw149_status m149 : 16|1@1+ (1,0) [0|1] "" Vector__XXX
 SG_ APSB_sw150_steeringAngleSensor m150 : 16|1@1+ (1,0) [0|1] "" Vector__XXX
 SG_ APSB_sw150_rightStalk m150 : 17|1@1+ (1,0) [0|1] "" Vector__XXX
 SG_ APSB_sw150_leftStalk m150 : 18|1@1+ (1,0) [0|1] "" Vector__XXX
 SG_ APSB_sw153_eacInhibitReason m153 : 16|4@1+ (1,0) [0|15] "" Vector__XXX
 SG_ APSB_sw153_eacInternalState m153 : 20|3@1+ (1,0) [0|7] "" Vector__XXX
 SG_ APSB_sw155_InUnicastError m155 : 16|1@1+ (1,0) [0|1] "" Vector__XXX
 SG_ APSB_sw155_UDPRecvError m155 : 17|1@1+ (1,0) [0|1] "" Vector__XXX
 SG_ APSB_sw155_UDPMiscError m155 : 18|1@1+ (1,0) [0|1] "" Vector__XXX
 SG_ APSB_sw155_UDPRTEError m155 : 19|1@1+ (1,0) [0|1] "" Vector__XXX
 SG_ APSB_sw155_UDPCheckError m155 : 20|1@1+ (1,0) [0|1] "" Vector__XXX
 SG_ APSB_sw155_UDPDropError m155 : 21|1@1+ (1,0) [0|1] "" Vector__XXX
 SG_ APSB_sw155_UDPMemError m155 : 22|1@1+ (1,0) [0|1] "" Vector__XXX
 SG_ APSB_sw155_UDPProtoError m155 : 23|1@1+ (1,0) [0|1] "" Vector__XXX
 SG_ APSB_sw155_IPRecvError m155 : 24|1@1+ (1,0) [0|1] "" Vector__XXX
 SG_ APSB_sw155_IPMiscError m155 : 25|1@1+ (1,0) [0|1] "" Vector__XXX
 SG_ APSB_sw155_IPRTEError m155 : 26|1@1+ (1,0) [0|1] "" Vector__XXX
 SG_ APSB_sw155_IPCheckError m155 : 27|1@1+ (1,0) [0|1] "" Vector__XXX
 SG_ APSB_sw155_IPMemError m155 : 28|1@1+ (1,0) [0|1] "" Vector__XXX
 SG_ APSB_sw155_IPDropError m155 : 29|1@1+ (1,0) [0|1] "" Vector__XXX
 SG_ APSB_sw155_IPProtoError m155 : 30|1@1+ (1,0) [0|1] "" Vector__XXX
 SG_ APSB_sw158_apbInfo m158 : 16|1@1+ (1,0) [0|1] "" Vector__XXX
 SG_ APSB_sw158_apbStatus m158 : 17|1@1+ (1,0) [0|1] "" Vector__XXX
 SG_ APSB_sw158_dasAutonomyControlPar m158 : 18|1@1+ (1,0) [0|1] "" Vector__XXX
 SG_ APSB_sw158_dasAutonomyControlVeh m158 : 19|1@1+ (1,0) [0|1] "" Vector__XXX
 SG_ APSB_sw158_dasBodyControlsVEH m158 : 20|1@1+ (1,0) [0|1] "" Vector__XXX
 SG_ APSB_sw158_dasControl m158 : 21|1@1+ (1,0) [0|1] "" Vector__XXX
 SG_ APSB_sw158_dasControlPty m158 : 22|1@1+ (1,0) [0|1] "" Vector__XXX
 SG_ APSB_sw158_dasIntSafetyFrontPty m158 : 23|1@1+ (1,0) [0|1] "" Vector__XXX
 SG_ APSB_sw158_dasLanes m158 : 24|1@1+ (1,0) [0|1] "" Vector__XXX
 SG_ APSB_sw158_dasObject m158 : 25|1@1+ (1,0) [0|1] "" Vector__XXX
 SG_ APSB_sw158_dasPscControl m158 : 26|1@1+ (1,0) [0|1] "" Vector__XXX
 SG_ APSB_sw158_dasStatus m158 : 27|1@1+ (1,0) [0|1] "" Vector__XXX
 SG_ APSB_sw158_dasStatus2 m158 : 28|1@1+ (1,0) [0|1] "" Vector__XXX
 SG_ APSB_sw158_dasSteeringControl m158 : 29|1@1+ (1,0) [0|1] "" Vector__XXX
 SG_ APSB_sw158_dasVisualDebug m158 : 30|1@1+ (1,0) [0|1] "" Vector__XXX
 SG_ APSB_sw158_dasSteeringControlPty m158 : 31|1@1+ (1,0) [0|1] "" Vector__XXX
 SG_ APSB_sw158_dasChNm m158 : 32|1@1+ (1,0) [0|1] "" Vector__XXX
 SG_ APSB_sw158_dasStatusPty m158 : 33|1@1+ (1,0) [0|1] "" Vector__XXX
 SG_ APSB_sw158_dasStatus2Pty m158 : 34|1@1+ (1,0) [0|1] "" Vector__XXX
 SG_ APSB_sw158_dasMatrixHighBeamRqVE m158 : 35|1@1+ (1,0) [0|1] "" Vector__XXX
 SG_ APSB_sw158_dasMatrixBendAngleRqP m158 : 36|1@1+ (1,0) [0|1] "" Vector__XXX
 SG_ APSB_sw158_dasBodyControls2VEH m158 : 37|1@1+ (1,0) [0|1] "" Vector__XXX
 SG_ APSB_sw158_dasRedundantBrakingCo m158 : 38|1@1+ (1,0) [0|1] "" Vector__XXX
 SG_ APSB_sw158_dasRedundantBrak_0001 m158 : 39|1@1+ (1,0) [0|1] "" Vector__XXX
 SG_ APSB_sw158_timeSinceLastMsg m158 : 40|24@1+ (1,0) [0|16777215] "" Vector__XXX
 SG_ APSB_sw159_apbCriticalReason m159 : 16|4@1+ (1,0) [0|15] "" Vector__XXX
 SG_ APSB_sw159_apbTimesyncStatus m159 : 24|32@1+ (1,0) [0|4294967295] "" Vector__XXX
 SG_ APSB_sw160_mismatchType m160 : 16|1@1+ (1,0) [0|1] "" Vector__XXX
 SG_ APSB_sw160_actualHash m160 : 24|24@1+ (1,0) [0|16777215] "" Vector__XXX
 SG_ APSB_sw160_expectedHash m160 : 48|16@1+ (1,0) [0|65535] "" Vector__XXX
 SG_ APSB_sw161_antennaDisconnected m161 : 16|1@1+ (1,0) [0|1] "" Vector__XXX
 SG_ APSB_sw172_prolongedUiMia m172 : 16|1@1+ (1,0) [0|1] "" Vector__XXX
 SG_ APSB_sw172_uiMiaAtBootup m172 : 17|1@1+ (1,0) [0|1] "" Vector__XXX
 SG_ APSB_sw188_otherTurbo m188 : 16|2@1+ (1,0) [0|3] "" Vector__XXX
 SG_ APSB_sw188_arbUartMiaState m188 : 18|1@1+ (1,0) [0|1] "" Vector__XXX
 SG_ APSB_sw188_powerUartMiaState m188 : 19|1@1+ (1,0) [0|1] "" Vector__XXX
 SG_ APSB_sw188_faultsUartMiaState m188 : 20|1@1+ (1,0) [0|1] "" Vector__XXX
 SG_ APSB_sw188_sleepUartMiaState m188 : 21|1@1+ (1,0) [0|1] "" Vector__XXX
 SG_ APSB_sw188_resetUartMiaState m188 : 22|1@1+ (1,0) [0|1] "" Vector__XXX
 SG_ APSB_sw188_statMonUartMiaState m188 : 23|1@1+ (1,0) [0|1] "" Vector__XXX
 SG_ APSB_sw188_wdogStateUartMiaState m188 : 24|1@1+ (1,0) [0|1] "" Vector__XXX
 SG_ APSB_sw188_critReasUartMiaState m188 : 25|1@1+ (1,0) [0|1] "" Vector__XXX
 SG_ APSB_sw189_AP_vehicleState10Hz m189 : 16|1@1+ (1,0) [0|1] "" Vector__XXX
 SG_ APSB_sw189_AP_vehicleState1Hz m189 : 17|1@1+ (1,0) [0|1] "" Vector__XXX
 SG_ APSB_sw190_IBST_status m190 : 16|1@1+ (1,0) [0|1] "" Vector__XXX
 SG_ APSB_sw192_CANbus m192 : 16|3@1+ (1,0) [0|7] "" Vector__XXX
 SG_ APSB_sw192_SWTxQueueFull m192 : 19|1@1+ (1,0) [0|1] "" Vector__XXX
 SG_ APSB_sw192_Busoff m192 : 20|1@1+ (1,0) [0|1] "" Vector__XXX
 SG_ APSB_sw192_UncorrectedBitError m192 : 21|1@1+ (1,0) [0|1] "" Vector__XXX
 SG_ APSB_sw192_CorrectedBitError m192 : 22|1@1+ (1,0) [0|1] "" Vector__XXX
 SG_ APSB_sw192_ErrorPassive m192 : 23|1@1+ (1,0) [0|1] "" Vector__XXX
 SG_ APSB_sw192_RamAccessFailed m192 : 24|1@1+ (1,0) [0|1] "" Vector__XXX
 SG_ APSB_sw192_RxMsgLost m192 : 25|1@1+ (1,0) [0|1] "" Vector__XXX
 SG_ APSB_sw192_msgIo m192 : 26|2@1+ (1,0) [0|3] "" Vector__XXX
 SG_ APSB_sw192_queueFailure m192 : 28|2@1+ (1,0) [0|3] "" Vector__XXX
 SG_ APSB_sw192_msgId m192 : 32|11@1+ (1,0) [0|2047] "" Vector__XXX
 SG_ APSB_sw199_abortCodeDas m199 : 16|6@1+ (1,0) [0|63] "" Vector__XXX
 SG_ APSB_sw199_abortCodePARK m199 : 22|5@1+ (1,0) [0|31] "" Vector__XXX
 SG_ APSB_sw199_currentSTW m199 : 27|14@1+ (0.1,-819.2) [-819.2|819.1] "" Vector__XXX
 SG_ APSB_sw199_currentSpeed m199 : 41|8@1+ (0.1,-12.2) [-12.2|13.3] "" Vector__XXX
 SG_ APSB_sw199_internalState m199 : 49|4@1+ (1,0) [0|15] "" Vector__XXX
 SG_ APSB_sw199_maxSpeed m199 : 53|7@1+ (0.2,-12.2) [-12.2|13.2] "" Vector__XXX
 SG_ APSB_sw199_numShifts m199 : 60|4@1+ (1,0) [0|15] "" Vector__XXX
 SG_ APSB_sw203_controlType m203 : 16|4@1+ (1,0) [0|15] "" Vector__XXX
 SG_ APSB_sw203_curbType m203 : 20|2@1+ (1,0) [0|3] "" Vector__XXX
 SG_ APSB_sw203_roadClass m203 : 22|3@1+ (1,0) [0|7] "" Vector__XXX
 SG_ APSB_sw203_slotSizeX m203 : 25|8@1+ (4,0) [0|1020] "" Vector__XXX
 SG_ APSB_sw203_slotSizeY m203 : 33|8@1+ (4,0) [0|1020] "" Vector__XXX
 SG_ APSB_sw203_startDistance m203 : 41|11@1+ (1,0) [0|2047] "" Vector__XXX
 SG_ APSB_sw203_vehicleSkew m203 : 52|12@1+ (0.002,0) [0|8.19] "" Vector__XXX
 SG_ APSB_sw204_frLeft m204 : 16|8@1+ (1,0) [0|255] "" Vector__XXX
 SG_ APSB_sw204_frLeftMiddle m204 : 24|8@1+ (1,0) [0|255] "" Vector__XXX
 SG_ APSB_sw204_frMiddle m204 : 32|8@1+ (1,0) [0|255] "" Vector__XXX
 SG_ APSB_sw204_frRight m204 : 40|8@1+ (1,0) [0|255] "" Vector__XXX
 SG_ APSB_sw204_frRightMiddle m204 : 48|8@1+ (1,0) [0|255] "" Vector__XXX
 SG_ APSB_sw204_maxSpeed m204 : 56|8@1+ (0.1,-12.2) [-12.2|13.3] "" Vector__XXX
 SG_ APSB_sw205_oocDistance m205 : 16|8@1+ (1,0) [0|255] "" Vector__XXX
 SG_ APSB_sw205_rrLeft m205 : 24|8@1+ (1,0) [0|255] "" Vector__XXX
 SG_ APSB_sw205_rrLeftMiddle m205 : 32|8@1+ (1,0) [0|255] "" Vector__XXX
 SG_ APSB_sw205_rrMiddle m205 : 40|8@1+ (1,0) [0|255] "" Vector__XXX
 SG_ APSB_sw205_rrRight m205 : 48|8@1+ (1,0) [0|255] "" Vector__XXX
 SG_ APSB_sw205_rrRightMiddle m205 : 56|8@1+ (1,0) [0|255] "" Vector__XXX
 SG_ APSB_sw235_resetOrigin m235 : 16|2@1+ (1,0) [0|3] "" Vector__XXX
 SG_ APSB_sw235_generalUnrecoverable m235 : 18|1@1+ (1,0) [0|1] "" Vector__XXX
 SG_ APSB_sw235_pgoodUnrecoverable m235 : 19|1@1+ (1,0) [0|1] "" Vector__XXX
 SG_ APSB_sw235_faultUnrecoverable m235 : 20|1@1+ (1,0) [0|1] "" Vector__XXX
 SG_ APSB_sw235_12VFuseUnrecoverable m235 : 21|1@1+ (1,0) [0|1] "" Vector__XXX
 SG_ APSB_sw235_pgoodLevelUnrcvrble m235 : 22|1@1+ (1,0) [0|1] "" Vector__XXX
 SG_ APSB_sw235_faultLevelUnrcvrble m235 : 23|1@1+ (1,0) [0|1] "" Vector__XXX
 SG_ APSB_sw235_12VFuseLvlUnrcvrble m235 : 24|1@1+ (1,0) [0|1] "" Vector__XXX
 SG_ APSB_sw235_localSoftwareFault m235 : 25|1@1+ (1,0) [0|1] "" Vector__XXX
 SG_ APSB_sw235_unrecoverableFailRese m235 : 26|1@1+ (1,0) [0|1] "" Vector__XXX
 SG_ APSB_sw235_generalGic m235 : 27|1@1+ (1,0) [0|1] "" Vector__XXX
 SG_ APSB_sw235_a72WdtTimeout m235 : 28|1@1+ (1,0) [0|1] "" Vector__XXX
 SG_ APSB_sw235_generalScs m235 : 29|1@1+ (1,0) [0|1] "" Vector__XXX
 SG_ APSB_sw235_generalUnexpected m235 : 30|1@1+ (1,0) [0|1] "" Vector__XXX
 SG_ APSB_sw235_canUncorrectedBitErro m235 : 31|1@1+ (1,0) [0|1] "" Vector__XXX
 SG_ APSB_sw235_canExitBusoffFailed m235 : 32|1@1+ (1,0) [0|1] "" Vector__XXX
 SG_ APSB_sw235_txEnFdbckNotExpected m235 : 33|1@1+ (1,0) [0|1] "" Vector__XXX
 SG_ APSB_sw235_nocSmsFailed m235 : 34|1@1+ (1,0) [0|1] "" Vector__XXX
 SG_ APSB_sw235_nocCamFailed m235 : 35|1@1+ (1,0) [0|1] "" Vector__XXX
 SG_ APSB_sw235_nocCoreFailed m235 : 36|1@1+ (1,0) [0|1] "" Vector__XXX
 SG_ APSB_sw235_nocScsFailed m235 : 37|1@1+ (1,0) [0|1] "" Vector__XXX
 SG_ APSB_sw235_model3UiReset m235 : 38|1@1+ (1,0) [0|1] "" Vector__XXX
 SG_ APSB_sw235_modelsUiReset m235 : 39|1@1+ (1,0) [0|1] "" Vector__XXX
 SG_ APSB_sw235_pmicApOnPrpUnrcvrble m235 : 40|1@1+ (1,0) [0|1] "" Vector__XXX
 SG_ APSB_sw235_apOnReadyTimeout m235 : 41|1@1+ (1,0) [0|1] "" Vector__XXX
 SG_ APSB_sw235_pmicApOnWaitUnrcvrble m235 : 42|1@1+ (1,0) [0|1] "" Vector__XXX
 SG_ APSB_sw235_apBootingTimeout m235 : 43|1@1+ (1,0) [0|1] "" Vector__XXX
 SG_ APSB_sw235_pmicApOffWaitUnrcvrbl m235 : 44|1@1+ (1,0) [0|1] "" Vector__XXX
 SG_ APSB_sw235_resetBeingSent m235 : 45|1@1+ (1,0) [0|1] "" Vector__XXX
 SG_ APSB_sw235_udsResetBeingSent m235 : 46|1@1+ (1,0) [0|1] "" Vector__XXX
 SG_ APSB_sw235_smsWdtTimeout m235 : 47|1@1+ (1,0) [0|1] "" Vector__XXX
 SG_ APSB_sw235_smsCanApHealthTimeout m235 : 48|1@1+ (1,0) [0|1] "" Vector__XXX
 SG_ APSB_sw235_smsTaskWdtTimeout m235 : 49|1@1+ (1,0) [0|1] "" Vector__XXX
 SG_ APSB_sw237_faultSource m237 : 16|7@1+ (1,0) [0|127] "" Vector__XXX
 SG_ APSB_sw237_peerSoCFaulted m237 : 23|1@1+ (1,0) [0|1] "" Vector__XXX
 SG_ APSB_sw241_unknownVendorOnResume m241 : 16|1@1+ (1,0) [0|1] "" Vector__XXX
 SG_ APSB_sw241_unknownVendorOnNonRes m241 : 17|1@1+ (1,0) [0|1] "" Vector__XXX
 SG_ APSB_sw241_phyReinitFailedOnResu m241 : 18|1@1+ (1,0) [0|1] "" Vector__XXX
 SG_ APSB_sw241_phyReinitFailedOnNonR m241 : 19|1@1+ (1,0) [0|1] "" Vector__XXX
 SG_ APSB_sw241_illTestFailed m241 : 20|1@1+ (1,0) [0|1] "" Vector__XXX
 SG_ APSB_sw241_memTestFailed m241 : 21|1@1+ (1,0) [0|1] "" Vector__XXX
 SG_ APSB_sw241_dfiInitCompleteTimeou m241 : 22|1@1+ (1,0) [0|1] "" Vector__XXX
 SG_ APSB_sw241_phy0TimeoutWaitingFor m241 : 23|1@1+ (1,0) [0|1] "" Vector__XXX
 SG_ APSB_sw241_phy0Ch0ReadGateOffset m241 : 24|1@1+ (1,0) [0|1] "" Vector__XXX
 SG_ APSB_sw241_phy0Ch1ReadGateOffset m241 : 25|1@1+ (1,0) [0|1] "" Vector__XXX
 SG_ APSB_sw241_phy0RdlvlReinitTraini m241 : 26|1@1+ (1,0) [0|1] "" Vector__XXX
 SG_ APSB_sw241_phy0RdlvlReinitFailed m241 : 27|1@1+ (1,0) [0|1] "" Vector__XXX
 SG_ APSB_sw241_phy0WdqlvlReinitTrain m241 : 28|1@1+ (1,0) [0|1] "" Vector__XXX
 SG_ APSB_sw241_phy0WdqlvlPhaseMargin m241 : 29|1@1+ (1,0) [0|1] "" Vector__XXX
 SG_ APSB_sw241_phy0WdqlvlReinitFaile m241 : 30|1@1+ (1,0) [0|1] "" Vector__XXX
 SG_ APSB_sw241_phy1TimeoutWaitingFor m241 : 31|1@1+ (1,0) [0|1] "" Vector__XXX
 SG_ APSB_sw241_phy1Ch0ReadGateOffset m241 : 32|1@1+ (1,0) [0|1] "" Vector__XXX
 SG_ APSB_sw241_phy1Ch1ReadGateOffset m241 : 33|1@1+ (1,0) [0|1] "" Vector__XXX
 SG_ APSB_sw241_phy1RdlvlReinitTraini m241 : 34|1@1+ (1,0) [0|1] "" Vector__XXX
 SG_ APSB_sw241_phy1RdlvlReinitFailed m241 : 35|1@1+ (1,0) [0|1] "" Vector__XXX
 SG_ APSB_sw241_phy1WdqlvlReinitTrain m241 : 36|1@1+ (1,0) [0|1] "" Vector__XXX
 SG_ APSB_sw241_phy1WdqlvlPhaseMargin m241 : 37|1@1+ (1,0) [0|1] "" Vector__XXX
 SG_ APSB_sw241_phy1WdqlvlReinitFaile m241 : 38|1@1+ (1,0) [0|1] "" Vector__XXX
 SG_ APSB_sw241_phy2TimeoutWaitingFor m241 : 39|1@1+ (1,0) [0|1] "" Vector__XXX
 SG_ APSB_sw241_phy2Ch0ReadGateOffset m241 : 40|1@1+ (1,0) [0|1] "" Vector__XXX
 SG_ APSB_sw241_phy2Ch1ReadGateOffset m241 : 41|1@1+ (1,0) [0|1] "" Vector__XXX
 SG_ APSB_sw241_phy2RdlvlReinitTraini m241 : 42|1@1+ (1,0) [0|1] "" Vector__XXX
 SG_ APSB_sw241_phy2RdlvlReinitFailed m241 : 43|1@1+ (1,0) [0|1] "" Vector__XXX
 SG_ APSB_sw241_phy2WdqlvlReinitTrain m241 : 44|1@1+ (1,0) [0|1] "" Vector__XXX
 SG_ APSB_sw241_phy2WdqlvlPhaseMargin m241 : 45|1@1+ (1,0) [0|1] "" Vector__XXX
 SG_ APSB_sw241_phy2WdqlvlReinitFaile m241 : 46|1@1+ (1,0) [0|1] "" Vector__XXX
 SG_ APSB_sw241_phy3TimeoutWaitingFor m241 : 47|1@1+ (1,0) [0|1] "" Vector__XXX
 SG_ APSB_sw241_phy3Ch0ReadGateOffset m241 : 48|1@1+ (1,0) [0|1] "" Vector__XXX
 SG_ APSB_sw241_phy3Ch1ReadGateOffset m241 : 49|1@1+ (1,0) [0|1] "" Vector__XXX
 SG_ APSB_sw241_phy3RdlvlReinitTraini m241 : 50|1@1+ (1,0) [0|1] "" Vector__XXX
 SG_ APSB_sw241_phy3RdlvlReinitFailed m241 : 51|1@1+ (1,0) [0|1] "" Vector__XXX
 SG_ APSB_sw241_phy3WdqlvlReinitTrain m241 : 52|1@1+ (1,0) [0|1] "" Vector__XXX
 SG_ APSB_sw241_phy3WdqlvlPhaseMargin m241 : 53|1@1+ (1,0) [0|1] "" Vector__XXX
 SG_ APSB_sw241_phy3WdqlvlReinitFaile m241 : 54|1@1+ (1,0) [0|1] "" Vector__XXX
 SG_ APSB_sw242_instance m242 : 16|3@1+ (1,0) [0|7] "" Vector__XXX
 SG_ APSB_sw242_clusterSRAMMBISTFaile m242 : 19|1@1+ (1,0) [0|1] "" Vector__XXX
 SG_ APSB_sw242_SRAMBankMBISTFailed m242 : 20|1@1+ (1,0) [0|1] "" Vector__XXX
 SG_ APSB_sw243_instance m243 : 16|3@1+ (1,0) [0|7] "" Vector__XXX
 SG_ APSB_sw243_errorStatus m243 : 24|8@1+ (1,0) [0|255] "" Vector__XXX
 SG_ APSB_sw243_extendedErrorStatus m243 : 32|24@1+ (1,0) [0|16777215] "" Vector__XXX
 SG_ APSB_sw244_instance m244 : 16|3@1+ (1,0) [0|7] "" Vector__XXX
 SG_ APSB_sw244_exceptionCode m244 : 24|8@1+ (1,0) [0|255] "" Vector__XXX
 SG_ APSB_sw245_unknownMACAddrByte0 m245 : 16|8@1+ (1,0) [0|255] "" Vector__XXX
 SG_ APSB_sw245_unknownMACAddrByte1 m245 : 24|8@1+ (1,0) [0|255] "" Vector__XXX
 SG_ APSB_sw245_unknownMACAddrByte2 m245 : 32|8@1+ (1,0) [0|255] "" Vector__XXX
 SG_ APSB_sw245_unknownMACAddrByte3 m245 : 40|8@1+ (1,0) [0|255] "" Vector__XXX
 SG_ APSB_sw245_unknownMACAddrByte4 m245 : 48|8@1+ (1,0) [0|255] "" Vector__XXX
 SG_ APSB_sw245_unknownMACAddrByte5 m245 : 56|8@1+ (1,0) [0|255] "" Vector__XXX
 SG_ APSB_sw246_ethloopSwitchPort0 m246 : 16|1@1+ (1,0) [0|1] "" Vector__XXX
 SG_ APSB_sw246_ethloopSwitchPort1 m246 : 17|1@1+ (1,0) [0|1] "" Vector__XXX
 SG_ APSB_sw246_ethloopSwitchPort2 m246 : 18|1@1+ (1,0) [0|1] "" Vector__XXX
 SG_ APSB_sw246_ethloopSwitchPort3 m246 : 19|1@1+ (1,0) [0|1] "" Vector__XXX
 SG_ APSB_sw246_ethloopSwitchPort4 m246 : 20|1@1+ (1,0) [0|1] "" Vector__XXX
 SG_ APSB_sw246_ethloopSwitchPort5 m246 : 21|1@1+ (1,0) [0|1] "" Vector__XXX
 SG_ APSB_sw246_ethloopSwitchPort6 m246 : 22|1@1+ (1,0) [0|1] "" Vector__XXX
 SG_ APSB_sw246_ethloopSwitchPort7 m246 : 23|1@1+ (1,0) [0|1] "" Vector__XXX
 SG_ APSB_sw247_crcError m247 : 16|1@1+ (1,0) [0|1] "" Vector__XXX
 SG_ APSB_sw247_dribbleError m247 : 17|1@1+ (1,0) [0|1] "" Vector__XXX
 SG_ APSB_sw247_receiveError m247 : 18|1@1+ (1,0) [0|1] "" Vector__XXX
 SG_ APSB_sw247_wdogTimeout m247 : 19|1@1+ (1,0) [0|1] "" Vector__XXX
 SG_ APSB_sw247_overflowError m247 : 20|1@1+ (1,0) [0|1] "" Vector__XXX
 SG_ APSB_sw247_giantPacket m247 : 21|1@1+ (1,0) [0|1] "" Vector__XXX
 SG_ APSB_sw247_destAddrFilterFail m247 : 22|1@1+ (1,0) [0|1] "" Vector__XXX
 SG_ APSB_sw247_saAddressFilterFail m247 : 23|1@1+ (1,0) [0|1] "" Vector__XXX
 SG_ APSB_sw248_ethloopSwitchPort2Sqi m248 : 16|3@1+ (1,0) [0|7] "" Vector__XXX
 SG_ APSB_sw248_ethloopSwitchPort3Sqi m248 : 19|3@1+ (1,0) [0|7] "" Vector__XXX
 SG_ APSB_sw249_ufsInitFailureReason m249 : 16|3@1+ (1,0) [0|7] "" Vector__XXX
 SG_ APSB_sw252_ethSwitchPort2 m252 : 16|1@1+ (1,0) [0|1] "" Vector__XXX
 SG_ APSB_sw253_apWaitForShutdownTime m253 : 16|1@1+ (1,0) [0|1] "" Vector__XXX
 SG_ APSB_sw253_apOffPrepareTimeout m253 : 17|1@1+ (1,0) [0|1] "" Vector__XXX
 SG_ APSB_sw253_apSuspendedTimeout m253 : 18|1@1+ (1,0) [0|1] "" Vector__XXX
 SG_ APSB_sw253_socOffReadyTimeout m253 : 19|1@1+ (1,0) [0|1] "" Vector__XXX
 SG_ APSB_sw253_apInLinuxTimeout m253 : 20|1@1+ (1,0) [0|1] "" Vector__XXX
 SG_ APSB_sw253_apInCorebootTimeout m253 : 21|1@1+ (1,0) [0|1] "" Vector__XXX
 SG_ APSB_sw253_apBootingTimeout m253 : 22|1@1+ (1,0) [0|1] "" Vector__XXX
 SG_ APSB_sw253_apOnTimeout m253 : 23|1@1+ (1,0) [0|1] "" Vector__XXX
 SG_ APSB_sw254_waitForBusSilenceTime m254 : 16|1@1+ (1,0) [0|1] "" Vector__XXX
 SG_ APSB_sw254_sleepReadyTimeout m254 : 17|1@1+ (1,0) [0|1] "" Vector__XXX
 SG_ APSB_sw254_sleepingTimeout m254 : 18|1@1+ (1,0) [0|1] "" Vector__XXX
 SG_ APSB_sw255_unknownBootError m255 : 16|1@1+ (1,0) [0|1] "" Vector__XXX
 SG_ APSB_sw255_adcWrapperInitBootErr m255 : 17|1@1+ (1,0) [0|1] "" Vector__XXX
 SG_ APSB_sw255_boardRevisionInitBoot m255 : 18|1@1+ (1,0) [0|1] "" Vector__XXX
 SG_ APSB_sw255_i2cInitBootError m255 : 19|1@1+ (1,0) [0|1] "" Vector__XXX
 SG_ APSB_sw255_provisionInitBootErro m255 : 20|1@1+ (1,0) [0|1] "" Vector__XXX
 SG_ APSB_sw255_rtcInitBootError m255 : 21|1@1+ (1,0) [0|1] "" Vector__XXX
 SG_ APSB_sw255_vrmInitConfigBootErro m255 : 22|1@1+ (1,0) [0|1] "" Vector__XXX
 SG_ APSB_sw255_powerAonIoBootError m255 : 23|1@1+ (1,0) [0|1] "" Vector__XXX
 SG_ APSB_sw255_bl1TocInitBootError m255 : 24|1@1+ (1,0) [0|1] "" Vector__XXX
 SG_ APSB_sw255_tmuInitBootError m255 : 25|1@1+ (1,0) [0|1] "" Vector__XXX
 SG_ APSB_sw255_udpInitBootError m255 : 26|1@1+ (1,0) [0|1] "" Vector__XXX
 SG_ APSB_sw255_gpsInitBootError m255 : 27|1@1+ (1,0) [0|1] "" Vector__XXX
 SG_ APSB_sw255_canInitBootError m255 : 28|1@1+ (1,0) [0|1] "" Vector__XXX
 SG_ APSB_sw255_dfuCheckinSubsystemBo m255 : 29|1@1+ (1,0) [0|1] "" Vector__XXX
 SG_ APSB_sw255_sectorProtectionBootE m255 : 30|1@1+ (1,0) [0|1] "" Vector__XXX
 SG_ APSB_sw255_flashOpBootError m255 : 31|1@1+ (1,0) [0|1] "" Vector__XXX
 SG_ APSB_sw255_socIdInitBootError m255 : 32|1@1+ (1,0) [0|1] "" Vector__XXX
 SG_ APSB_sw260_pgoodTripSramStatus m260 : 16|8@1+ (1,0) [0|255] "" Vector__XXX
 SG_ APSB_sw260_pgoodPmicFaultSd0 m260 : 24|1@1+ (1,0) [0|1] "" Vector__XXX
 SG_ APSB_sw260_pgoodPmicFaultSd1 m260 : 25|1@1+ (1,0) [0|1] "" Vector__XXX
 SG_ APSB_sw260_pgoodPmicFaultSd2 m260 : 26|1@1+ (1,0) [0|1] "" Vector__XXX
 SG_ APSB_sw260_pgoodPmicFaultSd3 m260 : 27|1@1+ (1,0) [0|1] "" Vector__XXX
 SG_ APSB_sw260_pgoodPmicFaultSd4 m260 : 28|1@1+ (1,0) [0|1] "" Vector__XXX
 SG_ APSB_sw260_pgoodPmicFaultLdo0 m260 : 29|1@1+ (1,0) [0|1] "" Vector__XXX
 SG_ APSB_sw260_pgoodPmicFaultLdo1 m260 : 30|1@1+ (1,0) [0|1] "" Vector__XXX
 SG_ APSB_sw260_pgoodPmicFaultLdo2 m260 : 31|1@1+ (1,0) [0|1] "" Vector__XXX
 SG_ APSB_sw260_pgoodPmicFaultLdo3 m260 : 32|1@1+ (1,0) [0|1] "" Vector__XXX
 SG_ APSB_sw260_pgoodPmicFaultLdo4 m260 : 33|1@1+ (1,0) [0|1] "" Vector__XXX
 SG_ APSB_sw260_pgoodPmicFaultLdo5 m260 : 34|1@1+ (1,0) [0|1] "" Vector__XXX
 SG_ APSB_sw260_pgoodPmicFaultLdo6 m260 : 35|1@1+ (1,0) [0|1] "" Vector__XXX
 SG_ APSB_sw260_pgoodPmicFaultLdo7 m260 : 36|1@1+ (1,0) [0|1] "" Vector__XXX
 SG_ APSB_sw260_pgoodPmicFaultLdo8 m260 : 37|1@1+ (1,0) [0|1] "" Vector__XXX
 SG_ APSB_sw260_pgoodUfs3V3Fail m260 : 38|1@1+ (1,0) [0|1] "" Vector__XXX
 SG_ APSB_sw260_pgoodTripVrmRailFail m260 : 39|1@1+ (1,0) [0|1] "" Vector__XXX
 SG_ APSB_sw260_pgoodIntVrmRailFail m260 : 40|1@1+ (1,0) [0|1] "" Vector__XXX
 SG_ APSB_sw260_pgoodCpuVrmRailFail m260 : 41|1@1+ (1,0) [0|1] "" Vector__XXX
 SG_ APSB_sw260_pgoodGpuVrmRailFail m260 : 42|1@1+ (1,0) [0|1] "" Vector__XXX
 SG_ APSB_sw260_pgoodDdr0V75VrmRailFa m260 : 43|1@1+ (1,0) [0|1] "" Vector__XXX
 SG_ APSB_sw260_pgoodDdr1V25VrmRailFa m260 : 44|1@1+ (1,0) [0|1] "" Vector__XXX
 SG_ APSB_sw260_unknownSource m260 : 45|1@1+ (1,0) [0|1] "" Vector__XXX
 SG_ APSB_sw261_vrmPublicFaultValues m261 : 16|16@1+ (1,0) [0|65535] "" Vector__XXX
 SG_ APSB_sw261_vrmRail1FaultValues m261 : 32|8@1+ (1,0) [0|255] "" Vector__XXX
 SG_ APSB_sw261_vrmRail2FaultValues m261 : 40|8@1+ (1,0) [0|255] "" Vector__XXX
 SG_ APSB_sw261_vrmRail3FaultValues m261 : 48|8@1+ (1,0) [0|255] "" Vector__XXX
 SG_ APSB_sw261_vrmType m261 : 56|3@1+ (1,0) [0|7] "" Vector__XXX
 SG_ APSB_sw262_vrmPublicFaultValues m262 : 16|16@1+ (1,0) [0|65535] "" Vector__XXX
 SG_ APSB_sw262_vrmRail1FaultValues m262 : 32|8@1+ (1,0) [0|255] "" Vector__XXX
 SG_ APSB_sw262_vrmRail2FaultValues m262 : 40|8@1+ (1,0) [0|255] "" Vector__XXX
 SG_ APSB_sw262_vrmRail3FaultValues m262 : 48|8@1+ (1,0) [0|255] "" Vector__XXX
 SG_ APSB_sw262_vrmType m262 : 56|3@1+ (1,0) [0|7] "" Vector__XXX
 SG_ APSB_sw263_vrmPublicFaultValues m263 : 16|16@1+ (1,0) [0|65535] "" Vector__XXX
 SG_ APSB_sw263_vrmRail1FaultValues m263 : 32|8@1+ (1,0) [0|255] "" Vector__XXX
 SG_ APSB_sw263_vrmRail2FaultValues m263 : 40|8@1+ (1,0) [0|255] "" Vector__XXX
 SG_ APSB_sw263_vrmType m263 : 48|3@1+ (1,0) [0|7] "" Vector__XXX
 SG_ APSB_sw279_corruptDirectorySourc m279 : 16|3@1+ (1,0) [0|7] "" Vector__XXX
 SG_ APSB_sw279_errorCode m279 : 24|8@1+ (1,0) [0|255] "" Vector__XXX
 SG_ APSB_sw280_pepsStatus m280 : 16|1@1+ (1,0) [0|1] "" Vector__XXX
 SG_ APSB_sw281_rearSteerStatus m281 : 16|1@1+ (1,0) [0|1] "" Vector__XXX
 SG_ APSB_sw283_psfaStatus m283 : 16|1@1+ (1,0) [0|1] "" Vector__XXX
 SG_ APSB_sw288_status m288 : 16|1@1+ (1,0) [0|1] "" Vector__XXX
 SG_ APSB_sw289_turboTemperature m289 : 16|8@1- (1,0) [-128|127] "" Vector__XXX
 SG_ APSB_sw289_turboProbe m289 : 24|6@1+ (1,0) [0|63] "" Vector__XXX
 SG_ APSB_sw289_peer_turboTemperature m289 : 32|8@1- (1,0) [-128|127] "" Vector__XXX
 SG_ APSB_sw289_peer_turboProbe m289 : 40|6@1+ (1,0) [0|63] "" Vector__XXX
 SG_ APSB_sw315_sysStatus m315 : 16|1@1+ (1,0) [0|1] "" Vector__XXX
 SG_ APSB_sw315_status m315 : 17|1@1+ (1,0) [0|1] "" Vector__XXX
 SG_ APSB_sw317_motionControlCommand m317 : 16|1@1+ (1,0) [0|1] "" Vector__XXX
 SG_ APSB_sw317_vehicleControl2 m317 : 17|1@1+ (1,0) [0|1] "" Vector__XXX

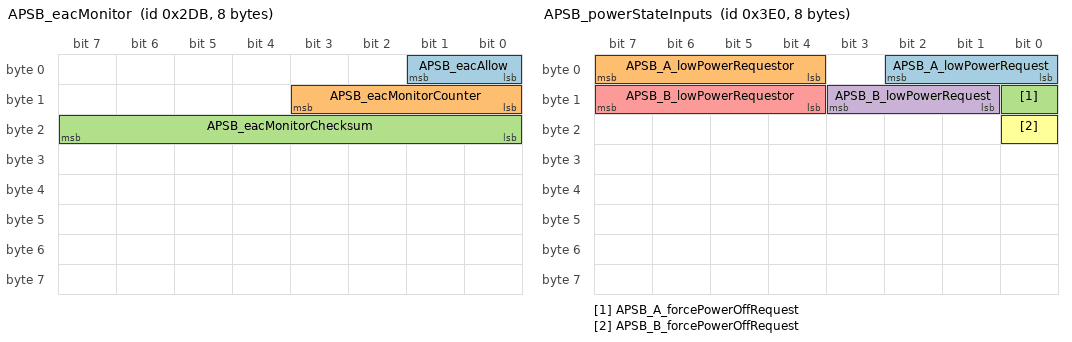
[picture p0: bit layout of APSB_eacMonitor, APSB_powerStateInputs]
BO_ 731 APSB_eacMonitor: 8 APSB
 SG_ APSB_eacAllow : 0|2@1+ (1,0) [0|3] "" Vector__XXX
 SG_ APSB_eacMonitorCounter : 8|4@1+ (1,0) [0|15] "" Vector__XXX
 SG_ APSB_eacMonitorChecksum : 16|8@1+ (1,0) [0|255] "" Vector__XXX

BO_ 992 APSB_powerStateInputs: 8 APSB
 SG_ APSB_A_lowPowerRequest : 0|3@1+ (1,0) [0|7] "" Vector__XXX
 SG_ APSB_A_lowPowerRequestor : 4|4@1+ (1,0) [0|15] "" Vector__XXX
 SG_ APSB_A_forcePowerOffRequest : 8|1@1+ (1,0) [0|1] "" Vector__XXX
 SG_ APSB_B_lowPowerRequest : 9|3@1+ (1,0) [0|7] "" Vector__XXX
 SG_ APSB_B_lowPowerRequestor : 12|4@1+ (1,0) [0|15] "" Vector__XXX
 SG_ APSB_B_forcePowerOffRequest : 16|1@1+ (1,0) [0|1] "" Vector__XXX

BO_ 1864 APSB_state: 8 APSB
 SG_ APSB_primaryTurbo : 0|2@1+ (1,0) [0|3] "" Vector__XXX
 SG_ APSB_A_arbState : 2|3@1+ (1,0) [0|7] "" Vector__XXX
 SG_ APSB_A_powerState : 5|5@1+ (1,0) [0|31] "" Vector__XXX
 SG_ APSB_A_sleepState : 10|4@1+ (1,0) [0|15] "" Vector__XXX
 SG_ APSB_A_resetState : 14|3@1+ (1,0) [0|7] "" Vector__XXX
 SG_ APSB_A_faultState : 17|5@1+ (1,0) [0|31] "" Vector__XXX
 SG_ APSB_secondaryTurbo : 22|2@1+ (1,0) [0|3] "" Vector__XXX
 SG_ APSB_B_arbState : 24|3@1+ (1,0) [0|7] "" Vector__XXX
 SG_ APSB_B_powerState : 27|5@1+ (1,0) [0|31] "" Vector__XXX
 SG_ APSB_B_sleepState : 32|4@1+ (1,0) [0|15] "" Vector__XXX
 SG_ APSB_B_resetState : 36|3@1+ (1,0) [0|7] "" Vector__XXX
 SG_ APSB_B_faultState : 39|5@1+ (1,0) [0|31] "" Vector__XXX
 SG_ APSB_A_autosteerMonitorState : 44|3@1+ (1,0) [0|7] "" Vector__XXX
 SG_ APSB_B_autosteerMonitorState : 47|3@1+ (1,0) [0|7] "" Vector__XXX
 SG_ APSB_eplannerState : 50|3@1+ (1,0) [0|7] "" Vector__XXX
 SG_ APSB_A_faultInduced : 53|1@1+ (1,0) [0|1] "" Vector__XXX
 SG_ APSB_B_faultInduced : 54|1@1+ (1,0) [0|1] "" Vector__XXX
 SG_ APSB_stateCounter : 55|4@1+ (1,0) [0|15] "" Vector__XXX

BO_ 971 APSB_status: 8 APSB
 SG_ APSB_appStatusMonitorState : 0|3@1+ (1,0) [0|7] "" Vector__XXX
 SG_ APSB_vehBehaviorState : 4|4@1+ (1,0) [0|15] "" Vector__XXX
 SG_ APSB_canMaster : 8|2@1+ (1,0) [0|3] "" Vector__XXX
 SG_ APSB_appGpioState : 10|2@1+ (1,0) [0|3] "" Vector__XXX
 SG_ APSB_eacInternalState : 12|3@1+ (1,0) [0|7] "" Vector__XXX
 SG_ APSB_switchState : 15|1@1+ (1,0) [0|1] "" Vector__XXX
 SG_ APSB_apbStatusMonitorState : 16|3@1+ (1,0) [0|7] "" Vector__XXX
 SG_ APSB_apbGpioState : 20|2@1+ (1,0) [0|3] "" Vector__XXX
 SG_ APSB_statusCounter : 22|4@1+ (1,0) [0|15] "" Vector__XXX
 SG_ APSB_locLimitReason : 26|3@1+ (1,0) [0|7] "" Vector__XXX
 SG_ APSB_appPowerStateRequest : 29|2@1+ (1,0) [0|3] "" Vector__XXX
 SG_ APSB_appPowerStateReason : 31|4@1+ (1,0) [0|15] "" Vector__XXX
 SG_ APSB_apbPowerStateRequest : 36|2@1+ (1,0) [0|3] "" Vector__XXX
 SG_ APSB_apbPowerStateReason : 38|4@1+ (1,0) [0|15] "" Vector__XXX
 SG_ APSB_heaterStateDebug : 43|3@1+ (1,0) [0|7] "" Vector__XXX
 SG_ APSB_autosummonCounter : 46|3@1+ (1,0) [0|7] "" Vector__XXX
 SG_ APSB_autosummonAlert : 49|1@1+ (1,0) [0|1] "" Vector__XXX
 SG_ APSB_gpsAntennaState : 50|2@1+ (1,0) [0|3] "" Vector__XXX
 SG_ APSB_arbState : 52|3@1+ (1,0) [0|7] "" Vector__XXX
 SG_ APSB_socPowerOperatingMode : 55|2@1+ (1,0) [0|3] "" Vector__XXX

CM_ BO_ 1065 "Driver assistance computer (primary) message: warning matrix2";
CM_ SG_ 1065 APP_w129_mainCamExtNotCal "Driver assistance computer (primary): w129 main cam ext not cal";
CM_ SG_ 1065 APP_w130_narrowCamExtNotCal "Driver assistance computer (primary): w130 narrow cam ext not cal";
CM_ SG_ 1065 APP_w131_mainCamCalSaved "Driver assistance computer (primary): w131 main cam cal saved";
CM_ SG_ 1065 APP_w132_narrowCamCalSaved "Driver assistance computer (primary): w132 narrow cam cal saved";
CM_ SG_ 1065 APP_w133_mainCamInitFault "Driver assistance computer (primary): w133 main cam init fault";
CM_ SG_ 1065 APP_w134_narrowCamInitFault "Driver assistance computer (primary): w134 narrow cam init fault";
CM_ SG_ 1065 APP_w135_fisheyeCamInitFault "Driver assistance computer (primary): w135 fisheye cam init fault";
CM_ SG_ 1065 APP_w136_lPillarCamInitFault "Driver assistance computer (primary): w136 l pillar cam init fault";
CM_ SG_ 1065 APP_w137_rPillarCamInitFault "Driver assistance computer (primary): w137 r pillar cam init fault";
CM_ SG_ 1065 APP_w138_lRepeatCamInitFault "Driver assistance computer (primary): w138 l repeat cam init fault";
CM_ SG_ 1065 APP_w139_rRepeatCamInitFault "Driver assistance computer (primary): w139 r repeat cam init fault";
CM_ SG_ 1065 APP_w140_backupCamInitFault "Driver assistance computer (primary): w140 backup cam init fault";
CM_ SG_ 1065 APP_w141_ECU_Thermal_Issue "Driver assistance computer (primary): w141 ECU thermal issue";
CM_ SG_ 1065 APP_w142_fwdCamPitchProblem "Driver assistance computer (primary): w142 fwd cam pitch problem";
CM_ SG_ 1065 APP_w143_IDF_event "Driver assistance computer (primary): w143 IDF event";
CM_ SG_ 1065 APP_w144_fanctrldError "Driver assistance computer (primary): w144 fanctrld error";
CM_ SG_ 1065 APP_w145_camSelfCalIssue "Driver assistance computer (primary): w145 cam self cal issue";
CM_ SG_ 1065 APP_w146_telemetryProblem "Driver assistance computer (primary): w146 telemetry problem";
CM_ SG_ 1065 APP_w147_selfieCamInitFault "Driver assistance computer (primary): w147 selfie cam init fault";
CM_ SG_ 1065 APP_w148_overlayActive "Driver assistance computer (primary): w148 overlay active";
CM_ SG_ 1065 APP_w149_diskFull "Driver assistance computer (primary): w149 disk full";
CM_ SG_ 1065 APP_w150_diMiaPartyBus "Driver assistance computer (primary): w150 di mia party bus";
CM_ SG_ 1065 APP_w151_epasMiaPartyBus "Driver assistance computer (primary): w151 epas mia party bus";
CM_ SG_ 1065 APP_w152_espMiaPartyBus "Driver assistance computer (primary): w152 esp mia party bus";
CM_ SG_ 1065 APP_w153_rcmMiaPartyBus "Driver assistance computer (primary): w153 rcm mia party bus";
CM_ SG_ 1065 APP_w154_vcleftMiaPartyBus "Driver assistance computer (primary): w154 vcleft mia party bus";
CM_ SG_ 1065 APP_w155_vcrightMiaPartyBus "Driver assistance computer (primary): w155 vcright mia party bus";
CM_ SG_ 1065 APP_w156_epblMiaVehBus "Driver assistance computer (primary): w156 epbl mia veh bus";
CM_ SG_ 1065 APP_w157_sccmMiaVehBus "Driver assistance computer (primary): w157 sccm mia veh bus";
CM_ SG_ 1065 APP_w158_vcfrontMiaVehBus "Driver assistance computer (primary): w158 vcfront mia veh bus";
CM_ SG_ 1065 APP_w159_vcleftMiaVehBus "Driver assistance computer (primary): w159 vcleft mia veh bus";
CM_ SG_ 1065 APP_w160_vcrightMiaVehBus "Driver assistance computer (primary): w160 vcright mia veh bus";
CM_ SG_ 1065 APP_w161_backupCameraUnavailable "Driver assistance computer (primary): w161 backup camera unavailable";
CM_ SG_ 1065 APP_w162_mainCameraTypeError "Driver assistance computer (primary): w162 main camera type error";
CM_ SG_ 1065 APP_w163_narrowCameraTypeError "Driver assistance computer (primary): w163 narrow camera type error";
CM_ SG_ 1065 APP_w164_fisheyeCameraTypeError "Driver assistance computer (primary): w164 fisheye camera type error";
CM_ SG_ 1065 APP_w165_lPillarCameraTypeError "Driver assistance computer (primary): w165 l pillar camera type error";
CM_ SG_ 1065 APP_w166_rPillarCameraTypeError "Driver assistance computer (primary): w166 r pillar camera type error";
CM_ SG_ 1065 APP_w167_lRepeatCameraTypeError "Driver assistance computer (primary): w167 l repeat camera type error";
CM_ SG_ 1065 APP_w168_rRepeatCameraTypeError "Driver assistance computer (primary): w168 r repeat camera type error";
CM_ SG_ 1065 APP_w169_backupCameraTypeError "Driver assistance computer (primary): w169 backup camera type error";
CM_ SG_ 1065 APP_w170_selfieCameraTypeError "Driver assistance computer (primary): w170 selfie camera type error";
CM_ SG_ 1065 APP_w171_appHighCoolantFlowReq "Driver assistance computer (primary): w171 app high coolant flow req";
CM_ SG_ 1065 APP_w172_fisheyeCamExtNotCal "Driver assistance computer (primary): w172 fisheye cam ext not cal";
CM_ SG_ 1065 APP_w173_lPillarCamExtNotCal "Driver assistance computer (primary): w173 l pillar cam ext not cal";
CM_ SG_ 1065 APP_w174_rPillarCamExtNotCal "Driver assistance computer (primary): w174 r pillar cam ext not cal";
CM_ SG_ 1065 APP_w175_lRepeatCamExtNotCal "Driver assistance computer (primary): w175 l repeat cam ext not cal";
CM_ SG_ 1065 APP_w176_rRepeatCamExtNotCal "Driver assistance computer (primary): w176 r repeat cam ext not cal";
CM_ SG_ 1065 APP_w177_fisheyeCamCalSaved "Driver assistance computer (primary): w177 fisheye cam cal saved";
CM_ SG_ 1065 APP_w178_lPillarCamCalSaved "Driver assistance computer (primary): w178 l pillar cam cal saved";
CM_ SG_ 1065 APP_w179_rPillarCamCalSaved "Driver assistance computer (primary): w179 r pillar cam cal saved";
CM_ SG_ 1065 APP_w180_lRepeatCamCalSaved "Driver assistance computer (primary): w180 l repeat cam cal saved";
CM_ SG_ 1065 APP_w181_rRepeatCamCalSaved "Driver assistance computer (primary): w181 r repeat cam cal saved";
CM_ SG_ 1065 APP_w182_mainCameraStreamExit "Driver assistance computer (primary): w182 main camera stream exit";
CM_ SG_ 1065 APP_w183_narrowCameraStreamExit "Driver assistance computer (primary): w183 narrow camera stream exit";
CM_ SG_ 1065 APP_w184_fisheyeCameraStreamExit "Driver assistance computer (primary): w184 fisheye camera stream exit";
CM_ SG_ 1065 APP_w185_lPillarCameraStreamExit "Driver assistance computer (primary): w185 l pillar camera stream exit";
CM_ SG_ 1065 APP_w186_rPillarCameraStreamExit "Driver assistance computer (primary): w186 r pillar camera stream exit";
CM_ SG_ 1065 APP_w187_lRepeatCameraStreamExit "Driver assistance computer (primary): w187 l repeat camera stream exit";
CM_ SG_ 1065 APP_w188_rRepeatCameraStreamExit "Driver assistance computer (primary): w188 r repeat camera stream exit";
CM_ SG_ 1065 APP_w189_backupCameraStreamExit "Driver assistance computer (primary): w189 backup camera stream exit";
CM_ SG_ 1065 APP_w190_selfieCameraStreamExit "Driver assistance computer (primary): w190 selfie camera stream exit";
CM_ SG_ 1065 APP_w191_autopilotAborting "Driver assistance computer (primary): w191 autopilot aborting";
CM_ SG_ 1065 APP_w192_emergencySpeakerFail "Driver assistance computer (primary): w192 emergency speaker fail";
CM_ BO_ 1081 "Driver assistance computer (primary) message: warning matrix3";
CM_ SG_ 1081 APP_w193_camWindshieldUnclean "Driver assistance computer (primary): w193 cam windshield unclean";
CM_ SG_ 1081 APP_w194_accDriverResumeRqrd "Driver assistance computer (primary): w194 acc driver resume rqrd";
CM_ SG_ 1081 APP_w195_scwUnavailable "Driver assistance computer (primary): w195 scw unavailable";
CM_ SG_ 1081 APP_w196_stopSignWarning "Driver assistance computer (primary): w196 stop sign warning";
CM_ SG_ 1081 APP_w197_redLightWarning "Driver assistance computer (primary): w197 red light warning";
CM_ SG_ 1081 APP_w198_tsrUnavailable "Driver assistance computer (primary): w198 tsr unavailable";
CM_ SG_ 1081 APP_w199_apcAbort "Driver assistance computer (primary): w199 apc abort";
CM_ SG_ 1081 APP_w200_lcSlowdown "Driver assistance computer (primary): w200 lc slowdown";
CM_ SG_ 1081 APP_w201_lcAborting "Driver assistance computer (primary): w201 lc aborting";
CM_ SG_ 1081 APP_w202_scwNoisyEnvironment "Driver assistance computer (primary): w202 scw noisy environment";
CM_ SG_ 1081 APP_w203_apcActivation "Driver assistance computer (primary): w203 apc activation";
CM_ SG_ 1081 APP_w204_apcFinalFront "Driver assistance computer (primary): w204 apc final front";
CM_ SG_ 1081 APP_w205_apcFinalRear "Driver assistance computer (primary): w205 apc final rear";
CM_ SG_ 1081 APP_w206_autosteerNotEnabled "Driver assistance computer (primary): w206 autosteer not enabled";
CM_ SG_ 1081 APP_w207_autosteerUnavailable "Driver assistance computer (primary): w207 autosteer unavailable";
CM_ SG_ 1081 APP_w208_rackDetected "Driver assistance computer (primary): w208 rack detected";
CM_ SG_ 1081 APP_w209_autoSummonRequest "Driver assistance computer (primary): w209 auto summon request";
CM_ SG_ 1081 APP_w210_camObstrcted "Driver assistance computer (primary): w210 cam obstrcted";
CM_ SG_ 1081 APP_w211_accNoSeatBelt "Driver assistance computer (primary): w211 acc no seat belt";
CM_ SG_ 1081 APP_w212_lcUnavailableStrikeOut "Driver assistance computer (primary): w212 lc unavailable strike out";
CM_ SG_ 1081 APP_w213_autosteerStruckOut "Driver assistance computer (primary): w213 autosteer struck out";
CM_ SG_ 1081 APP_w214_driverNotIntracting "Driver assistance computer (primary): w214 driver not intracting";
CM_ SG_ 1081 APP_w215_contDriverNotIntracting "Driver assistance computer (primary): w215 cont driver not intracting";
CM_ SG_ 1081 APP_w216_driverOverriding "Driver assistance computer (primary): w216 driver overriding";
CM_ SG_ 1081 APP_w217_lcUnavailableSpeeding "Driver assistance computer (primary): w217 lc unavailable speeding";
CM_ SG_ 1081 APP_w218_lcSpeedExceededLimit "Driver assistance computer (primary): w218 lc speed exceeded limit";
CM_ SG_ 1081 APP_w219_lcTempUnavailableSpeed "Driver assistance computer (primary): w219 lc temp unavailable speed";
CM_ SG_ 1081 APP_w220_lcTempUnavailableRoad "Driver assistance computer (primary): w220 lc temp unavailable road";
CM_ SG_ 1081 APP_w221_accRadarBlind "Driver assistance computer (primary): w221 acc radar blind";
CM_ SG_ 1081 APP_w222_accCameraBlind "Driver assistance computer (primary): w222 acc camera blind";
CM_ SG_ 1081 APP_w223_accObjectInPath "Driver assistance computer (primary): w223 acc object in path";
CM_ SG_ 1081 APP_w224_accCameraCalibration "Driver assistance computer (primary): w224 acc camera calibration";
CM_ SG_ 1081 APP_w225_lcDegradedVisSpeedLmt "Driver assistance computer (primary): w225 lc degraded vis speed lmt";
CM_ SG_ 1081 APP_w226_lcCamCalNeededSpeedLmt "Driver assistance computer (primary): w226 lc cam cal needed speed lmt";
CM_ SG_ 1081 APP_w227_virtualWallBlocked "Driver assistance computer (primary): w227 virtual wall blocked";
CM_ SG_ 1081 APP_w228_DEPRECATED "Driver assistance computer (primary): w228 DEPRECATED";
CM_ SG_ 1081 APP_w229_alcUltrasoundDamaged "Driver assistance computer (primary): w229 alc ultrasound damaged";
CM_ SG_ 1081 APP_w230_alcUltrasoundBlocked "Driver assistance computer (primary): w230 alc ultrasound blocked";
CM_ SG_ 1081 APP_w231_idfEvent "Driver assistance computer (primary): w231 idf event";
CM_ SG_ 1081 APP_w232_laneChangeRequested "Driver assistance computer (primary): w232 lane change requested";
CM_ SG_ 1081 APP_w233_fsdQuizRequired "Driver assistance computer (primary): w233 fsd quiz required";
CM_ SG_ 1081 APP_w234_activeSafetyTelemetry "Driver assistance computer (primary): w234 active safety telemetry";
CM_ SG_ 1081 APP_w235_fsdRegionNotAllowed "Driver assistance computer (primary): w235 fsd region not allowed";
CM_ BO_ 1097 "Driver assistance computer (primary) message: warning matrix4";
CM_ SG_ 1097 APP_w257_brakeJerkEvent "Driver assistance computer (primary): w257 brake jerk event";
CM_ SG_ 1097 APP_w258_aebEvent "Driver assistance computer (primary): w258 aeb event";
CM_ SG_ 1097 APP_w259_aebOverrideEvent "Driver assistance computer (primary): w259 aeb override event";
CM_ SG_ 1097 APP_w260_collisionWarningEvent "Driver assistance computer (primary): w260 collision warning event";
CM_ SG_ 1097 APP_w261_pcieHardwareErrors "Driver assistance computer (primary): w261 pcie hardware errors";
CM_ SG_ 1097 APP_w262_apeCalibMode "Driver assistance computer (primary): w262 ape calib mode";
CM_ SG_ 1097 APP_w263_lssAbort "Driver assistance computer (primary): w263 lss abort";
CM_ SG_ 1097 APP_w264_lssFault "Driver assistance computer (primary): w264 lss fault";
CM_ SG_ 1097 APP_w265_drvOnNavUnavailable "Driver assistance computer (primary): w265 drv on nav unavailable";
CM_ SG_ 1097 APP_w266_visionScheduleFallback "Driver assistance computer (primary): w266 vision schedule fallback";
CM_ SG_ 1097 APP_w267_benchtopEcu "Driver assistance computer (primary): w267 benchtop ecu";
CM_ SG_ 1097 APP_w268_backupCamExtNotCal "Driver assistance computer (primary): w268 backup cam ext not cal";
CM_ SG_ 1097 APP_w269_autopilotLimited "Driver assistance computer (primary): w269 autopilot limited";
CM_ SG_ 1097 APP_w270_blindspotRestricted "Driver assistance computer (primary): w270 blindspot restricted";
CM_ SG_ 1097 APP_w271_laneChangeAborted "Driver assistance computer (primary): w271 lane change aborted";
CM_ SG_ 1097 APP_w272_laneChangeUnavailable "Driver assistance computer (primary): w272 lane change unavailable";
CM_ SG_ 1097 APP_w273_lssEvent "Driver assistance computer (primary): w273 lss event";
CM_ SG_ 1097 APP_w274_mainCameraStreamErr "Driver assistance computer (primary): w274 main camera stream err";
CM_ SG_ 1097 APP_w275_narrowCameraStreamErr "Driver assistance computer (primary): w275 narrow camera stream err";
CM_ SG_ 1097 APP_w276_fisheyeCameraStreamErr "Driver assistance computer (primary): w276 fisheye camera stream err";
CM_ SG_ 1097 APP_w277_lPillarCameraStreamErr "Driver assistance computer (primary): w277 l pillar camera stream err";
CM_ SG_ 1097 APP_w278_rPillarCameraStreamErr "Driver assistance computer (primary): w278 r pillar camera stream err";
CM_ SG_ 1097 APP_w279_lRepeatCameraStreamErr "Driver assistance computer (primary): w279 l repeat camera stream err";
CM_ SG_ 1097 APP_w280_rRepeatCameraStreamErr "Driver assistance computer (primary): w280 r repeat camera stream err";
CM_ SG_ 1097 APP_w281_backupCameraStreamErr "Driver assistance computer (primary): w281 backup camera stream err";
CM_ SG_ 1097 APP_w282_selfieCameraStreamErr "Driver assistance computer (primary): w282 selfie camera stream err";
CM_ SG_ 1097 APP_w283_enhancedSummonAbort "Driver assistance computer (primary): w283 enhanced summon abort";
CM_ SG_ 1097 APP_w284_gpsAntennaDisconnected "Driver assistance computer (primary): w284 gps antenna disconnected";
CM_ SG_ 1097 APP_w285_gpsFaultReset "Driver assistance computer (primary): w285 gps fault reset";
CM_ SG_ 1097 APP_w286_gpsComIssue "Driver assistance computer (primary): w286 gps com issue";
CM_ SG_ 1097 APP_w287_gpsFusionStatus "Driver assistance computer (primary): w287 gps fusion status";
CM_ SG_ 1097 APP_w288_trafficLightWarning "Driver assistance computer (primary): w288 traffic light warning";
CM_ SG_ 1097 APP_w289_dramCorrEccErrors "Driver assistance computer (primary): w289 dram corr ecc errors";
CM_ SG_ 1097 APP_w290_dramUncorrEccErrors "Driver assistance computer (primary): w290 dram uncorr ecc errors";
CM_ SG_ 1097 APP_w291_stopSignWarning "Driver assistance computer (primary): w291 stop sign warning";
CM_ SG_ 1097 APP_w293_mainCameraSyncFailed "Driver assistance computer (primary): w293 main camera sync failed";
CM_ SG_ 1097 APP_w294_narrowCameraSyncFailed "Driver assistance computer (primary): w294 narrow camera sync failed";
CM_ SG_ 1097 APP_w295_fisheyeCameraSyncFailed "Driver assistance computer (primary): w295 fisheye camera sync failed";
CM_ SG_ 1097 APP_w296_lPillarCameraSyncFailed "Driver assistance computer (primary): w296 l pillar camera sync failed";
CM_ SG_ 1097 APP_w297_rPillarCameraSyncFailed "Driver assistance computer (primary): w297 r pillar camera sync failed";
CM_ SG_ 1097 APP_w298_lRepeatCameraSyncFailed "Driver assistance computer (primary): w298 l repeat camera sync failed";
CM_ SG_ 1097 APP_w299_rRepeatCameraSyncFailed "Driver assistance computer (primary): w299 r repeat camera sync failed";
CM_ SG_ 1097 APP_w300_backupCameraSyncFailed "Driver assistance computer (primary): w300 backup camera sync failed";
CM_ SG_ 1097 APP_w301_selfieCameraSyncFailed "Driver assistance computer (primary): w301 selfie camera sync failed";
CM_ SG_ 1097 APP_w302_vcfrontMiaPartyBus "Driver assistance computer (primary): w302 vcfront mia party bus";
CM_ SG_ 1097 APP_w303_imuIrational "Driver assistance computer (primary): w303 imu irational";
CM_ SG_ 1097 APP_w304_lssCamBlockedStatus "Driver assistance computer (primary): w304 lss cam blocked status";
CM_ SG_ 1097 APP_w305_lssCamStreamExit "Driver assistance computer (primary): w305 lss cam stream exit";
CM_ SG_ 1097 APP_w306_lssUltrasonicsBlocked "Driver assistance computer (primary): w306 lss ultrasonics blocked";
CM_ SG_ 1097 APP_w307_lssTurnSignalFault "Driver assistance computer (primary): w307 lss turn signal fault";
CM_ SG_ 1097 APP_w308_iboosterMia "Driver assistance computer (primary): w308 ibooster mia";
CM_ SG_ 1097 APP_w309_selfieDisabledOnCar "Driver assistance computer (primary): w309 selfie disabled on car";
CM_ SG_ 1097 APP_w310_eth0FrameErrors "Driver assistance computer (primary): w310 eth0 frame errors";
CM_ SG_ 1097 APP_w311_eth1FrameErrors "Driver assistance computer (primary): w311 eth1 frame errors";
CM_ SG_ 1097 APP_w312_mainCamTypeMismatch "Driver assistance computer (primary): w312 main cam type mismatch";
CM_ SG_ 1097 APP_w313_narrowCamTypeMismatch "Driver assistance computer (primary): w313 narrow cam type mismatch";
CM_ SG_ 1097 APP_w314_fisheyeCamTypeMismatch "Driver assistance computer (primary): w314 fisheye cam type mismatch";
CM_ SG_ 1097 APP_w315_lPillarCamTypeMismatch "Driver assistance computer (primary): w315 l pillar cam type mismatch";
CM_ SG_ 1097 APP_w316_rPillarCamTypeMismatch "Driver assistance computer (primary): w316 r pillar cam type mismatch";
CM_ SG_ 1097 APP_w317_lRepeatCamTypeMismatch "Driver assistance computer (primary): w317 l repeat cam type mismatch";
CM_ SG_ 1097 APP_w318_rRepeatCamTypeMismatch "Driver assistance computer (primary): w318 r repeat cam type mismatch";
CM_ SG_ 1097 APP_w319_backupCamTypeMismatch "Driver assistance computer (primary): w319 backup cam type mismatch";
CM_ SG_ 1097 APP_w320_selfieCamTypeMismatch "Driver assistance computer (primary): w320 selfie cam type mismatch";
CM_ BO_ 1151 "Driver assistance computer (primary) message: warning matrix5";
CM_ SG_ 1151 APP_w321_bmsMia "Driver assistance computer (primary): w321 bms mia";
CM_ SG_ 1151 APP_w322_autoWiperWash "Driver assistance computer (primary): w322 auto wiper wash";
CM_ SG_ 1151 APP_w323_drivableSpaceFCW "Driver assistance computer (primary): w323 drivable space FCW";
CM_ SG_ 1151 APP_w324_adspMia "Driver assistance computer (primary): w324 adsp mia";
CM_ SG_ 1151 APP_w325_watchdogReset "Driver assistance computer (primary): w325 watchdog reset";
CM_ SG_ 1151 APP_w326_kernelPanic "Driver assistance computer (primary): w326 kernel panic";
CM_ SG_ 1151 APP_w327_vehicleConfigMismatch "Driver assistance computer (primary): w327 vehicle config mismatch";
CM_ SG_ 1151 APP_w328_autoparkDegraded "Driver assistance computer (primary): w328 autopark degraded";
CM_ SG_ 1151 APP_w329_evasiveManeuver "Driver assistance computer (primary): w329 evasive maneuver";
CM_ SG_ 1151 APP_w330_cabinCameraFault "Driver assistance computer (primary): w330 cabin camera fault";
CM_ SG_ 1151 APP_w331_fsdDegradedUnavailable "Driver assistance computer (primary): w331 fsd degraded unavailable";
CM_ SG_ 1151 APP_w332_cameraPositionsSwapped "Driver assistance computer (primary): w332 camera positions swapped";
CM_ SG_ 1151 APP_w333_fsdUnavailableLocation "Driver assistance computer (primary): w333 fsd unavailable location";
CM_ SG_ 1151 APP_w334_frontCameraOccluded "Driver assistance computer (primary): w334 front camera occluded";
CM_ SG_ 1151 APP_w335_tradfcRfSensorError "Driver assistance computer (primary): w335 tradfc rf sensor error";
CM_ SG_ 1151 APP_w336_tradfcLfPmicError "Driver assistance computer (primary): w336 tradfc lf pmic error";
CM_ SG_ 1151 APP_w337_tradfcRfPmicError "Driver assistance computer (primary): w337 tradfc rf pmic error";
CM_ SG_ 1151 APP_w338_tradfcLfTempError "Driver assistance computer (primary): w338 tradfc lf temp error";
CM_ SG_ 1151 APP_w339_tradfcRfTempError "Driver assistance computer (primary): w339 tradfc rf temp error";
CM_ SG_ 1151 APP_w340_tradfcCsiError "Driver assistance computer (primary): w340 tradfc csi error";
CM_ SG_ 1151 APP_w341_tradfcCalibError "Driver assistance computer (primary): w341 tradfc calib error";
CM_ SG_ 1151 APP_w342_tradfcDspHwError "Driver assistance computer (primary): w342 tradfc dsp hw error";
CM_ SG_ 1151 APP_w343_tradfcDspSwError "Driver assistance computer (primary): w343 tradfc dsp sw error";
CM_ SG_ 1151 APP_w344_tradfcDspAlgoTimeout "Driver assistance computer (primary): w344 tradfc dsp algo timeout";
CM_ SG_ 1151 APP_w345_tradfcPerfDegraded "Driver assistance computer (primary): w345 tradfc perf degraded";
CM_ SG_ 1151 APP_w346_gpsSwEvent "Driver assistance computer (primary): w346 gps sw event";
CM_ SG_ 1151 APP_w347_vcbattMiaVehBus "Driver assistance computer (primary): w347 vcbatt mia veh bus";
CM_ SG_ 1151 APP_w348_cameraSwUpdateRequired "Driver assistance computer (primary): w348 camera sw update required";
CM_ SG_ 1151 APP_w349_cameraPersistentlyFault "Driver assistance computer (primary): w349 camera persistently faulted";
CM_ SG_ 1151 APP_w350_tradfcSensorMisaligned "Driver assistance computer (primary): w350 tradfc sensor misaligned";
CM_ SG_ 1151 APP_w351_csiDevice0Down "Driver assistance computer (primary): w351 csi device0 down";
CM_ SG_ 1151 APP_w352_csiDevice1Down "Driver assistance computer (primary): w352 csi device1 down";
CM_ SG_ 1151 APP_w353_csiDevice2Down "Driver assistance computer (primary): w353 csi device2 down";
CM_ SG_ 1151 APP_w354_tradfcMia "Driver assistance computer (primary): w354 tradfc mia";
CM_ SG_ 1151 APP_w355_camQuadPowerFault "Driver assistance computer (primary): w355 cam quad power fault";
CM_ SG_ 1151 APP_w356_driverOverriding "Driver assistance computer (primary): w356 driver overriding";
CM_ SG_ 1151 APP_w357_ddawSystemFault "Driver assistance computer (primary): w357 ddaw system fault";
CM_ SG_ 1151 APP_w358_isaSystemFault "Driver assistance computer (primary): w358 isa system fault";
CM_ SG_ 1151 APP_w359_aebDegraded "Driver assistance computer (primary): w359 aeb degraded";
CM_ SG_ 1151 APP_w360_apImuNoiseDetected "Driver assistance computer (primary): w360 ap imu noise detected";
CM_ SG_ 1151 APP_w361_cabinCameraLEDFault "Driver assistance computer (primary): w361 cabin camera LED fault";
CM_ SG_ 1151 APP_w362_fasciaCamInitFault "Driver assistance computer (primary): w362 fascia cam init fault";
CM_ SG_ 1151 APP_w363_fasciaCameraStreamExit "Driver assistance computer (primary): w363 fascia camera stream exit";
CM_ SG_ 1151 APP_w364_fasciaCameraTypeError "Driver assistance computer (primary): w364 fascia camera type error";
CM_ SG_ 1151 APP_w365_fasciaCamExtNotCal "Driver assistance computer (primary): w365 fascia cam ext not cal";
CM_ SG_ 1151 APP_w366_fasciaCameraSyncFailed "Driver assistance computer (primary): w366 fascia camera sync failed";
CM_ SG_ 1151 APP_w367_fasciaCamCalSaved "Driver assistance computer (primary): w367 fascia cam cal saved";
CM_ SG_ 1151 APP_w368_fasciaCamTypeMismatch "Driver assistance computer (primary): w368 fascia cam type mismatch";
CM_ SG_ 1151 APP_w369_cruiseWithSingleClick "Driver assistance computer (primary): w369 cruise with single click";
CM_ SG_ 1151 APP_w370_accApUnavUserSettings "Driver assistance computer (primary): w370 acc ap unav user settings";
CM_ SG_ 1151 APP_w371_networkLoadingIssue "Driver assistance computer (primary): w371 network loading issue";
CM_ SG_ 1151 APP_w372_cabinCameraBlocked "Driver assistance computer (primary): w372 cabin camera blocked";
CM_ SG_ 1151 APP_w373_gnssUartError "Driver assistance computer (primary): w373 gnss uart error";
CM_ SG_ 1151 APP_w374_gnssDataMia "Driver assistance computer (primary): w374 gnss data mia";
CM_ SG_ 1151 APP_w375_gnssPpsMia "Driver assistance computer (primary): w375 gnss pps mia";
CM_ SG_ 1151 APP_w376_wheeltickCountMia "Driver assistance computer (primary): w376 wheeltick count mia";
CM_ SG_ 1151 APP_w377_apImuMia "Driver assistance computer (primary): w377 ap imu mia";
CM_ SG_ 1151 APP_w378_ubloxImuMia "Driver assistance computer (primary): w378 ublox imu mia";
CM_ SG_ 1151 APP_w379_positioningEngineMia "Driver assistance computer (primary): w379 positioning engine mia";
CM_ SG_ 1151 APP_w380_gnssPpsTimestampIssue "Driver assistance computer (primary): w380 gnss pps timestamp issue";
CM_ SG_ 1151 APP_w381_apImuTimestampIssue "Driver assistance computer (primary): w381 ap imu timestamp issue";
CM_ SG_ 1151 APP_w382_ubloxImuTimestampIssue "Driver assistance computer (primary): w382 ublox imu timestamp issue";
CM_ SG_ 1151 APP_w383_manyApRebootsWhileInP "Driver assistance computer (primary): w383 many ap reboots while in p";
CM_ SG_ 1151 APP_w384_posEngineInitInMotion "Driver assistance computer (primary): w384 pos engine init in motion";
CM_ BO_ 1149 "Driver assistance computer (primary) message: warning matrix6";
CM_ SG_ 1149 APP_w385_posEngineUnhealthy "Driver assistance computer (primary): w385 pos engine unhealthy";
CM_ SG_ 1149 APP_w386_radarOnlyBrakingEvent "Driver assistance computer (primary): w386 radar only braking event";
CM_ SG_ 1149 APP_w387_radarBlockageDetected "Driver assistance computer (primary): w387 radar blockage detected";
CM_ SG_ 1149 APP_w388_windshieldCameraHeaterF "Driver assistance computer (primary): w388 windshield camera heater faulted";
CM_ SG_ 1149 APP_w389_camFovResidueDetected "Driver assistance computer (primary): w389 cam fov residue detected";
CM_ SG_ 1149 APP_w390_cabinCamVisDegraded "Driver assistance computer (primary): w390 cabin cam vis degraded";
CM_ SG_ 1149 APP_w391_cabinCameraBlockedonAP "Driver assistance computer (primary): w391 cabin camera blockedon AP";
CM_ SG_ 1149 APP_w392_fsdSuspended "Driver assistance computer (primary): w392 fsd suspended";
CM_ SG_ 1149 APP_w393_attnMntrUnavailable "Driver assistance computer (primary): w393 attn mntr unavailable";
CM_ SG_ 1149 APP_w394_apImuGrossErrors "Driver assistance computer (primary): w394 ap imu gross errors";
CM_ SG_ 1149 APP_w395_cabinCameraLEDFaultSvc "Driver assistance computer (primary): w395 cabin camera LED fault svc";
CM_ SG_ 1149 APP_w396_severeResidueDetected "Driver assistance computer (primary): w396 severe residue detected";
CM_ SG_ 1149 APP_w397_apFeatDisabledPermanent "Driver assistance computer (primary): w397 ap feat disabled permanent";
CM_ SG_ 1149 APP_w398_imuOutputUnhealthy "Driver assistance computer (primary): w398 imu output unhealthy";
CM_ SG_ 1149 APP_w399_brakeboosterMia "Driver assistance computer (primary): w399 brakebooster mia";
CM_ SG_ 1149 APP_w400_selfieCameraFanFault "Driver assistance computer (primary): w400 selfie camera fan fault";
CM_ SG_ 1149 APP_w401_leftPillarCameraHeaterF "Driver assistance computer (primary): w401 left pillar camera heater faulted";
CM_ SG_ 1149 APP_w402_rightPillarCameraHeater "Driver assistance computer (primary): w402 right pillar camera heater faulted";
CM_ SG_ 1149 APP_w403_notifyCameraSelfCleanAc "Driver assistance computer (primary): w403 notify camera self clean action";
CM_ SG_ 1149 APP_w404_epbrMiaVehBus "Driver assistance computer (primary): w404 epbr mia veh bus";
CM_ SG_ 1149 APP_w405_apsMia "Driver assistance computer (primary): w405 aps mia";
CM_ SG_ 1149 APP_w406_gnssHWHealthDegraded "Driver assistance computer (primary): w406 gnss HW health degraded";
CM_ SG_ 1149 APP_w407_autonomyDegraded1 "Driver assistance computer (primary): w407 autonomy degraded1";
CM_ SG_ 1149 APP_w408_autonomyDegraded2 "Driver assistance computer (primary): w408 autonomy degraded2";
CM_ SG_ 1149 APP_w409_autonomyDegraded3 "Driver assistance computer (primary): w409 autonomy degraded3";
CM_ SG_ 1149 APP_w410_autonomyDegraded4 "Driver assistance computer (primary): w410 autonomy degraded4";
CM_ SG_ 1149 APP_w411_backupCameraOccluded "Driver assistance computer (primary): w411 backup camera occluded";
CM_ SG_ 1149 APP_w412_abortBackupCamOccluded "Driver assistance computer (primary): w412 abort backup cam occluded";
CM_ SG_ 1149 APP_w413_autonomyDegraded5 "Driver assistance computer (primary): w413 autonomy degraded5";
CM_ SG_ 1149 APP_w415_autonomyUnavailableSyst "Driver assistance computer (primary): w415 autonomy unavailable system";
CM_ SG_ 1149 APP_w416_autonomyDegradedSystem "Driver assistance computer (primary): w416 autonomy degraded system";
CM_ SG_ 1149 APP_w417_autonomyUnavailableVisi "Driver assistance computer (primary): w417 autonomy unavailable visibility";
CM_ SG_ 1149 APP_w418_autonomyDegradedVisibil "Driver assistance computer (primary): w418 autonomy degraded visibility";
CM_ SG_ 1149 APP_w419_autonomyUnavailableApSy "Driver assistance computer (primary): w419 autonomy unavailable ap system";
CM_ SG_ 1149 APP_w420_autonomyDegradedApSyste "Driver assistance computer (primary): w420 autonomy degraded ap system";
CM_ SG_ 1149 APP_w421_autonomyUnavailableUser "Driver assistance computer (primary): w421 autonomy unavailable user";
CM_ SG_ 1149 APP_w422_autonomyDegradedUser "Driver assistance computer (primary): w422 autonomy degraded user";
CM_ SG_ 1149 APP_w423_cameraVisPopUpForward "Driver assistance computer (primary): w423 camera vis pop up forward";
CM_ SG_ 1149 APP_w424_cameraVisPopUpLPillar "Driver assistance computer (primary): w424 camera vis pop up l pillar";
CM_ SG_ 1149 APP_w425_cameraVisPopUpRPillar "Driver assistance computer (primary): w425 camera vis pop up r pillar";
CM_ SG_ 1149 APP_w426_cameraVisPopUpLRepeater "Driver assistance computer (primary): w426 camera vis pop up l repeater";
CM_ SG_ 1149 APP_w427_cameraVisPopUpRRepeater "Driver assistance computer (primary): w427 camera vis pop up r repeater";
CM_ SG_ 1149 APP_w428_cameraVisPopUpBackup "Driver assistance computer (primary): w428 camera vis pop up backup";
CM_ SG_ 1149 APP_w429_cameraVisPopUpFascia "Driver assistance computer (primary): w429 camera vis pop up fascia";
CM_ SG_ 1149 APP_w430_frontVisibilityDegraded "Driver assistance computer (primary): w430 front visibility degraded LOW";
CM_ SG_ 1149 APP_w431_frontVisibilityDegraded "Driver assistance computer (primary): w431 front visibility degraded MEDIUM";
CM_ SG_ 1149 APP_w432_frontVisibilityDegraded "Driver assistance computer (primary): w432 front visibility degraded HIGH";
CM_ SG_ 1149 APP_w433_leftRepeaterDowngradeDe "Driver assistance computer (primary): w433 left repeater downgrade detected";
CM_ SG_ 1149 APP_w434_rightRepeaterDowngradeD "Driver assistance computer (primary): w434 right repeater downgrade detected";
CM_ SG_ 1149 APP_w435_repeaterAeroRibInfoMism "Driver assistance computer (primary): w435 repeater aero rib info mismatched";
CM_ SG_ 1149 APP_w436_camCsiError "Driver assistance computer (primary): w436 cam csi error";
CM_ SG_ 1149 APP_w437_missingCloudEepromData "Driver assistance computer (primary): w437 missing cloud eeprom data";
CM_ SG_ 1149 APP_w438_rcuMia "Driver assistance computer (primary): w438 rcu mia";
CM_ SG_ 1149 APP_w439_ethernetCommFailure "Driver assistance computer (primary): w439 ethernet comm failure";
CM_ SG_ 1149 APP_w440_lensHoodOcclusion "Driver assistance computer (primary): w440 lens hood occlusion";
CM_ SG_ 1149 APP_w441_cabinCamLEDRailOff "Driver assistance computer (primary): w441 cabin cam LED rail off";
CM_ SG_ 1149 APP_w442_autonomyCancelMethod "Driver assistance computer (primary): w442 autonomy cancel method";
CM_ SG_ 1149 APP_w443_mainImagerConfigMismatc "Driver assistance computer (primary): w443 main imager config mismatch";
CM_ SG_ 1149 APP_w444_narrowImagerConfigMisma "Driver assistance computer (primary): w444 narrow imager config mismatch";
CM_ SG_ 1149 APP_w445_fisheyeImagerConfigMism "Driver assistance computer (primary): w445 fisheye imager config mismatch";
CM_ SG_ 1149 APP_w446_leftPillarImagerConfigM "Driver assistance computer (primary): w446 left pillar imager config mismatch";
CM_ SG_ 1149 APP_w447_rightPillarImagerConfig "Driver assistance computer (primary): w447 right pillar imager config mismatch";
CM_ SG_ 1149 APP_w448_leftRepeaterImagerConfi "Driver assistance computer (primary): w448 left repeater imager config mismatch";
CM_ BO_ 1233 "Driver assistance computer (primary) message: warning matrix7";
CM_ SG_ 1233 APP_w449_rightRepeaterImagerConf "Driver assistance computer (primary): w449 right repeater imager config mismatch";
CM_ SG_ 1233 APP_w450_backupImagerConfigMisma "Driver assistance computer (primary): w450 backup imager config mismatch";
CM_ SG_ 1233 APP_w451_fasciaImagerConfigMisma "Driver assistance computer (primary): w451 fascia imager config mismatch";
CM_ SG_ 1233 APP_w452_selfieImagerConfigMisma "Driver assistance computer (primary): w452 selfie imager config mismatch";
CM_ SG_ 1233 APP_w453_driverCancelBlinker "Driver assistance computer (primary): w453 driver cancel blinker";
CM_ SG_ 1233 APP_w454_appAutonomySystemUnheal "Driver assistance computer (primary): w454 app autonomy system unhealthy";
CM_ SG_ 1233 APP_w455_apbAutonomySystemUnheal "Driver assistance computer (primary): w455 apb autonomy system unhealthy";
CM_ SG_ 1233 APP_w456_autonomyUnavailableColl "Driver assistance computer (primary): w456 autonomy unavailable collision";
CM_ SG_ 1233 APP_w457_autonomyDegradedCollisi "Driver assistance computer (primary): w457 autonomy degraded collision";
CM_ SG_ 1233 APP_w458_aceEvent "Driver assistance computer (primary): w458 ace event";
CM_ SG_ 1233 APP_w459_epbrMiaPartyBus "Driver assistance computer (primary): w459 epbr mia party bus";
CM_ SG_ 1233 APP_w460_epblMiaChBus "Driver assistance computer (primary): w460 epbl mia ch bus";
CM_ SG_ 1233 APP_w461_autonomyReroute "Driver assistance computer (primary): w461 autonomy reroute";
CM_ SG_ 1233 APP_w462_selfDrivingUnavailable "Driver assistance computer (primary): w462 self driving unavailable";
CM_ SG_ 1233 APP_w463_selfDrivingCamObstrcted "Driver assistance computer (primary): w463 self driving cam obstrcted";
CM_ SG_ 1233 APP_w464_autonomyUnavailableODD "Driver assistance computer (primary): w464 autonomy unavailable ODD";
CM_ SG_ 1233 APP_w465_autonomyDegradedODD "Driver assistance computer (primary): w465 autonomy degraded ODD";
CM_ SG_ 1233 APP_w466_missingSensorOTP "Driver assistance computer (primary): w466 missing sensor OTP";
CM_ SG_ 1233 APP_w467_imuDegraded "Driver assistance computer (primary): w467 imu degraded";
CM_ SG_ 1233 APP_w477_driverSeatReclined "Driver assistance computer (primary): w477 driver seat reclined";
CM_ SG_ 1233 APP_w478_runModeSwitch "Driver assistance computer (primary): w478 run mode switch";
CM_ SG_ 1233 APP_w482_appVisionFailoverActiva "Driver assistance computer (primary): w482 app vision failover activated";
CM_ SG_ 1233 APP_w483_apbVisionFailoverActiva "Driver assistance computer (primary): w483 apb vision failover activated";
CM_ BO_ 1482 "APSB ECU message: alert log";
CM_ SG_ 1482 APSB_alertID "APSB ECU: alert ID";
CM_ SG_ 1482 APSB_alertSource "APSB ECU: alert source";
CM_ SG_ 1482 APSB_alertState "APSB ECU: alert state";
CM_ SG_ 1482 APSB_sw010_a04calibNotDone "APSB ECU: sw010 a04calib not done";
CM_ SG_ 1482 APSB_sw010_a05calibReqd "APSB ECU: sw010 a05calib reqd";
CM_ SG_ 1482 APSB_sw010_a06calibNotOK "APSB ECU: sw010 a06calib not OK";
CM_ SG_ 1482 APSB_sw010_a08PlantMode "APSB ECU: sw010 a08 plant mode";
CM_ SG_ 1482 APSB_sw010_HorizontalMisalignmen "APSB ECU: sw010 horizontal misalignment";
CM_ SG_ 1482 APSB_sw010_VerticalMisalignment "APSB ECU: sw010 vertical misalignment";
CM_ SG_ 1482 APSB_sw010_unusedBits "APSB ECU: sw010 unused bits";
CM_ SG_ 1482 APSB_sw010_VmaPlausibility "APSB ECU: sw010 vma plausibility";
CM_ SG_ 1482 APSB_sw019_taskId "APSB ECU: sw019 task id";
CM_ SG_ 1482 APSB_sw019_numFreeBytes "APSB ECU: sw019 num free bytes";
CM_ SG_ 1482 APSB_sw019_timeStamp "APSB ECU: sw019 time stamp";
CM_ SG_ 1482 APSB_sw020_unusedW0 "APSB ECU: sw020 unused W0";
CM_ SG_ 1482 APSB_sw020_unusedW1 "APSB ECU: sw020 unused W1";
CM_ SG_ 1482 APSB_sw020_unusedW2 "APSB ECU: sw020 unused W2";
CM_ SG_ 1482 APSB_sw021_tempSensorId "APSB ECU: sw021 temp sensor id";
CM_ SG_ 1482 APSB_sw021_minThreshold "APSB ECU: sw021 min threshold";
CM_ SG_ 1482 APSB_sw021_maxThreshold "APSB ECU: sw021 max threshold";
CM_ SG_ 1482 APSB_sw021_currentTemperature "APSB ECU: sw021 current temperature";
CM_ SG_ 1482 APSB_sw021_unusedWord "APSB ECU: sw021 unused word";
CM_ SG_ 1482 APSB_sw024_Task_ID "APSB ECU: sw024 task ID";
CM_ SG_ 1482 APSB_sw024_numVirtualLaneVeh "APSB ECU: sw024 num virtual lane veh";
CM_ SG_ 1482 APSB_sw024_currentVehicleApp "APSB ECU: sw024 current vehicle app";
CM_ SG_ 1482 APSB_sw024_taskProgramCounter "APSB ECU: sw024 task program counter";
CM_ SG_ 1482 APSB_sw027_JTAG_Reset "APSB ECU: sw027 JTAG reset";
CM_ SG_ 1482 APSB_sw027_Core_Reset "APSB ECU: sw027 core reset";
CM_ SG_ 1482 APSB_sw027_Unused_Bit_0 "APSB ECU: sw027 unused bit 0";
CM_ SG_ 1482 APSB_sw027_CPU_Checkstop_Error "APSB ECU: sw027 CPU checkstop error";
CM_ SG_ 1482 APSB_sw027_PLL_0_Failure "APSB ECU: sw027 PLL 0 failure";
CM_ SG_ 1482 APSB_sw027_Clock_Monitor_0_Low "APSB ECU: sw027 clock monitor 0 low";
CM_ SG_ 1482 APSB_sw027_Clock_Monitor_0_Off "APSB ECU: sw027 clock monitor 0 off";
CM_ SG_ 1482 APSB_sw027_LVD_4v5 "APSB ECU: sw027 LVD 4v5";
CM_ SG_ 1482 APSB_sw027_Flash_Fatal_Error "APSB ECU: sw027 flash fatal error";
CM_ SG_ 1482 APSB_sw027_PLL_1_Failure "APSB ECU: sw027 PLL 1 failure";
CM_ SG_ 1482 APSB_sw027_Unused_Bit_1 "APSB ECU: sw027 unused bit 1";
CM_ SG_ 1482 APSB_sw027_f_PLL_1_Off "APSB ECU: sw027 f PLL 1 off";
CM_ SG_ 1482 APSB_sw027_Unused_Nibble "APSB ECU: sw027 unused nibble";
CM_ SG_ 1482 APSB_sw027_LVD_1v2 "APSB ECU: sw027 LVD 1v2";
CM_ SG_ 1482 APSB_sw027_Unused_Bit_2 "APSB ECU: sw027 unused bit 2";
CM_ SG_ 1482 APSB_sw027_Watchdog "APSB ECU: sw027 watchdog";
CM_ SG_ 1482 APSB_sw027_Unused_Bit_3 "APSB ECU: sw027 unused bit 3";
CM_ SG_ 1482 APSB_sw027_LVD_2v7_VREG "APSB ECU: sw027 LVD 2v7 VREG";
CM_ SG_ 1482 APSB_sw027_LVD_2v7_Flash "APSB ECU: sw027 LVD 2v7 flash";
CM_ SG_ 1482 APSB_sw027_LVD_2v7_IO "APSB ECU: sw027 LVD 2v7 IO";
CM_ SG_ 1482 APSB_sw027_Unused_Bit_4 "APSB ECU: sw027 unused bit 4";
CM_ SG_ 1482 APSB_sw027_Unused_Byte "APSB ECU: sw027 unused byte";
CM_ SG_ 1482 APSB_sw027_ESR0 "APSB ECU: sw027 ESR0";
CM_ SG_ 1482 APSB_sw027_ESR1 "APSB ECU: sw027 ESR1";
CM_ SG_ 1482 APSB_sw027_SW "APSB ECU: sw027 SW";
CM_ SG_ 1482 APSB_sw027_STM0 "APSB ECU: sw027 STM0";
CM_ SG_ 1482 APSB_sw027_STM1 "APSB ECU: sw027 STM1";
CM_ SG_ 1482 APSB_sw027_STM2 "APSB ECU: sw027 STM2";
CM_ SG_ 1482 APSB_sw027_CBS_SYSTEM "APSB ECU: sw027 CBS SYSTEM";
CM_ SG_ 1482 APSB_sw027_CBS_DEBUG "APSB ECU: sw027 CBS DEBUG";
CM_ SG_ 1482 APSB_sw027_CBS_APP "APSB ECU: sw027 CBS APP";
CM_ SG_ 1482 APSB_sw027_EVR13 "APSB ECU: sw027 EVR13";
CM_ SG_ 1482 APSB_sw027_EVR33 "APSB ECU: sw027 EVR33";
CM_ SG_ 1482 APSB_sw027_SWD "APSB ECU: sw027 SWD";
CM_ SG_ 1482 APSB_sw027_STDBY_WDG "APSB ECU: sw027 STDBY WDG";
CM_ SG_ 1482 APSB_sw027_PORST "APSB ECU: sw027 PORST";
CM_ SG_ 1482 APSB_sw027_Unused_word "APSB ECU: sw027 unused word";
CM_ SG_ 1482 APSB_sw030_heaterState "APSB ECU: sw030 heater state";
CM_ SG_ 1482 APSB_sw030_unusedByte "APSB ECU: sw030 unused byte";
CM_ SG_ 1482 APSB_sw030_unusedW0 "APSB ECU: sw030 unused W0";
CM_ SG_ 1482 APSB_sw030_unusedW1 "APSB ECU: sw030 unused W1";
CM_ SG_ 1482 APSB_sw033_carConfig "APSB ECU: sw033 car config";
CM_ SG_ 1482 APSB_sw033_chNm "APSB ECU: sw033 ch nm";
CM_ SG_ 1482 APSB_sw033_vin "APSB ECU: sw033 vin";
CM_ SG_ 1482 APSB_sw033_carState "APSB ECU: sw033 car state";
CM_ SG_ 1482 APSB_sw034_sccmMia "APSB ECU: sw034 sccm mia";
CM_ SG_ 1482 APSB_sw034_unusedByte "APSB ECU: sw034 unused byte";
CM_ SG_ 1482 APSB_sw034_unusedW0 "APSB ECU: sw034 unused W0";
CM_ SG_ 1482 APSB_sw034_unusedW1 "APSB ECU: sw034 unused W1";
CM_ SG_ 1482 APSB_sw035_wheelSpeeds "APSB ECU: sw035 wheel speeds";
CM_ SG_ 1482 APSB_sw035_status "APSB ECU: sw035 status";
CM_ SG_ 1482 APSB_sw035_wheelRotation "APSB ECU: sw035 wheel rotation";
CM_ SG_ 1482 APSB_sw035_redundantBrakingStatu "APSB ECU: sw035 redundant braking status";
CM_ SG_ 1482 APSB_sw036_bdyMia "APSB ECU: sw036 bdy mia";
CM_ SG_ 1482 APSB_sw036_unusedByte "APSB ECU: sw036 unused byte";
CM_ SG_ 1482 APSB_sw036_unusedW0 "APSB ECU: sw036 unused W0";
CM_ SG_ 1482 APSB_sw036_unusedW1 "APSB ECU: sw036 unused W1";
CM_ SG_ 1482 APSB_sw039_sdm_rcm_Mia "APSB ECU: sw039 sdm rcm mia";
CM_ SG_ 1482 APSB_sw039_unusedByte "APSB ECU: sw039 unused byte";
CM_ SG_ 1482 APSB_sw039_unusedW0 "APSB ECU: sw039 unused W0";
CM_ SG_ 1482 APSB_sw039_unusedW1 "APSB ECU: sw039 unused W1";
CM_ SG_ 1482 APSB_sw045_radMia "APSB ECU: sw045 rad mia";
CM_ SG_ 1482 APSB_sw045_unusedByte "APSB ECU: sw045 unused byte";
CM_ SG_ 1482 APSB_sw045_unusedW0 "APSB ECU: sw045 unused W0";
CM_ SG_ 1482 APSB_sw045_unusedW1 "APSB ECU: sw045 unused W1";
CM_ SG_ 1482 APSB_sw048_swAssert "APSB ECU: sw048 sw assert";
CM_ SG_ 1482 APSB_sw048_thermalIssue "APSB ECU: sw048 thermal issue";
CM_ SG_ 1482 APSB_sw048_powerIssue "APSB ECU: sw048 power issue";
CM_ SG_ 1482 APSB_sw048_stackOverflow "APSB ECU: sw048 stack overflow";
CM_ SG_ 1482 APSB_sw048_checkStop "APSB ECU: sw048 check stop";
CM_ SG_ 1482 APSB_sw048_ecuWatchdog "APSB ECU: sw048 ecu watchdog";
CM_ SG_ 1482 APSB_sw048_ecuReset "APSB ECU: sw048 ecu reset";
CM_ SG_ 1482 APSB_sw048_radcVersionMismatch "APSB ECU: sw048 radc version mismatch";
CM_ SG_ 1482 APSB_sw048_radcCalibration "APSB ECU: sw048 radc calibration";
CM_ SG_ 1482 APSB_sw048_radcMia "APSB ECU: sw048 radc mia";
CM_ SG_ 1482 APSB_sw048_eyeQVersionMismatch "APSB ECU: sw048 eye q version mismatch";
CM_ SG_ 1482 APSB_sw048_camIssue "APSB ECU: sw048 cam issue";
CM_ SG_ 1482 APSB_sw048_parkerIssue "APSB ECU: sw048 parker issue";
CM_ SG_ 1482 APSB_sw048_prolongedUiMia "APSB ECU: sw048 prolonged ui mia";
CM_ SG_ 1482 APSB_sw048_uiMiaAtBootup "APSB ECU: sw048 ui mia at bootup";
CM_ SG_ 1482 APSB_sw051_a01ecuInternalPerf "APSB ECU: sw051 a01ecu internal perf";
CM_ SG_ 1482 APSB_sw051_a02flashPerformance "APSB ECU: sw051 a02flash performance";
CM_ SG_ 1482 APSB_sw051_a03vBatHigh "APSB ECU: sw051 a03v bat high";
CM_ SG_ 1482 APSB_sw051_a09configMismatch "APSB ECU: sw051 a09config mismatch";
CM_ SG_ 1482 APSB_sw051_a52radomeHtrInop "APSB ECU: sw051 a52radome htr inop";
CM_ SG_ 1482 APSB_sw051_unused "APSB ECU: sw051 unused";
CM_ SG_ 1482 APSB_sw051_SCUTemperature "APSB ECU: sw051 SCU temperature";
CM_ SG_ 1482 APSB_sw051_HWFail "APSB ECU: sw051 HW fail";
CM_ SG_ 1482 APSB_sw051_SGUFail "APSB ECU: sw051 SGU fail";
CM_ SG_ 1482 APSB_sw051_unusedBits "APSB ECU: sw051 unused bits";
CM_ SG_ 1482 APSB_sw051_unusedB0 "APSB ECU: sw051 unused B0";
CM_ SG_ 1482 APSB_sw051_unusedW1 "APSB ECU: sw051 unused W1";
CM_ SG_ 1482 APSB_sw052_a07sensorBlinded "APSB ECU: sw052 a07sensor blinded";
CM_ SG_ 1482 APSB_sw052_sensorDirty "APSB ECU: sw052 sensor dirty";
CM_ SG_ 1482 APSB_sw052_HWFail "APSB ECU: sw052 HW fail";
CM_ SG_ 1482 APSB_sw052_overTemperature "APSB ECU: sw052 over temperature";
CM_ SG_ 1482 APSB_sw052_underTemperature "APSB ECU: sw052 under temperature";
CM_ SG_ 1482 APSB_sw052_chirpError "APSB ECU: sw052 chirp error";
CM_ SG_ 1482 APSB_sw052_rspError "APSB ECU: sw052 rsp error";
CM_ SG_ 1482 APSB_sw052_sensorBlocked "APSB ECU: sw052 sensor blocked";
CM_ SG_ 1482 APSB_sw053_a10canBusOff "APSB ECU: sw053 a10can bus off";
CM_ SG_ 1482 APSB_sw053_a11bdyMIA "APSB ECU: sw053 a11bdy MIA";
CM_ SG_ 1482 APSB_sw053_a12espMIA "APSB ECU: sw053 a12esp MIA";
CM_ SG_ 1482 APSB_sw053_a13gtwMIA "APSB ECU: sw053 a13gtw MIA";
CM_ SG_ 1482 APSB_sw053_a14sccmMIA "APSB ECU: sw053 a14sccm MIA";
CM_ SG_ 1482 APSB_sw053_a15adasMIA "APSB ECU: sw053 a15adas MIA";
CM_ SG_ 1482 APSB_sw053_a16bdyInvalidCount "APSB ECU: sw053 a16bdy invalid count";
CM_ SG_ 1482 APSB_sw053_a17adasInvalidCount "APSB ECU: sw053 a17adas invalid count";
CM_ SG_ 1482 APSB_sw053_a18espInvalidCount "APSB ECU: sw053 a18esp invalid count";
CM_ SG_ 1482 APSB_sw053_a19sccmInvalidCount "APSB ECU: sw053 a19sccm invalid count";
CM_ SG_ 1482 APSB_sw053_a20bdyInvalidChkSm "APSB ECU: sw053 a20bdy invalid chk sm";
CM_ SG_ 1482 APSB_sw053_a21espInvalidChkSm "APSB ECU: sw053 a21esp invalid chk sm";
CM_ SG_ 1482 APSB_sw053_a22sccmInvalidChkSm "APSB ECU: sw053 a22sccm invalid chk sm";
CM_ SG_ 1482 APSB_sw053_a23sccmInvalidChkSm "APSB ECU: sw053 a23sccm invalid chk sm";
CM_ SG_ 1482 APSB_sw053_a24absValidity "APSB ECU: sw053 a24abs validity";
CM_ SG_ 1482 APSB_sw053_a25ambTValidity "APSB ECU: sw053 a25amb t validity";
CM_ SG_ 1482 APSB_sw053_a26brakeValidity "APSB ECU: sw053 a26brake validity";
CM_ SG_ 1482 APSB_sw053_a27CntryCdValidity "APSB ECU: sw053 a27 cntry cd validity";
CM_ SG_ 1482 APSB_sw053_a28espValidity "APSB ECU: sw053 a28esp validity";
CM_ SG_ 1482 APSB_sw053_a29longAccOffValidity "APSB ECU: sw053 a29long acc off validity";
CM_ SG_ 1482 APSB_sw053_a30longAccValidity "APSB ECU: sw053 a30long acc validity";
CM_ SG_ 1482 APSB_sw053_a31odoValidity "APSB ECU: sw053 a31odo validity";
CM_ SG_ 1482 APSB_sw053_a32gearValidity "APSB ECU: sw053 a32gear validity";
CM_ SG_ 1482 APSB_sw053_a33steerAngValidity "APSB ECU: sw053 a33steer ang validity";
CM_ SG_ 1482 APSB_sw053_a34steerAngSpdValidit "APSB ECU: sw053 a34steer ang spd validity";
CM_ SG_ 1482 APSB_sw053_a35indctrValidity "APSB ECU: sw053 a35indctr validity";
CM_ SG_ 1482 APSB_sw053_a36vehStndStllValidty "APSB ECU: sw053 a36veh stnd stll validty";
CM_ SG_ 1482 APSB_sw053_a37vinValidity "APSB ECU: sw053 a37vin validity";
CM_ SG_ 1482 APSB_sw053_a38whlRotValidity "APSB ECU: sw053 a38whl rot validity";
CM_ SG_ 1482 APSB_sw053_a39whlSpdValidity "APSB ECU: sw053 a39whl spd validity";
CM_ SG_ 1482 APSB_sw053_a40whlStndStllValidty "APSB ECU: sw053 a40whl stnd stll validty";
CM_ SG_ 1482 APSB_sw053_a41wiperValidity "APSB ECU: sw053 a41wiper validity";
CM_ SG_ 1482 APSB_sw053_a42xwdValidity "APSB ECU: sw053 a42xwd validity";
CM_ SG_ 1482 APSB_sw053_a43yawOffValidity "APSB ECU: sw053 a43yaw off validity";
CM_ SG_ 1482 APSB_sw053_a44yawValidity "APSB ECU: sw053 a44yaw validity";
CM_ SG_ 1482 APSB_sw053_a48steerAngOffSanity "APSB ECU: sw053 a48steer ang off sanity";
CM_ SG_ 1482 APSB_sw053_a49tireSizeSanity "APSB ECU: sw053 a49tire size sanity";
CM_ SG_ 1482 APSB_sw053_a50velocitySanity "APSB ECU: sw053 a50velocity sanity";
CM_ SG_ 1482 APSB_sw053_a51yawSanity "APSB ECU: sw053 a51yaw sanity";
CM_ SG_ 1482 APSB_sw053_a53espmodValidity "APSB ECU: sw053 a53espmod validity";
CM_ SG_ 1482 APSB_sw053_a54gtwmodValidity "APSB ECU: sw053 a54gtwmod validity";
CM_ SG_ 1482 APSB_sw053_a55stwmodValidity "APSB ECU: sw053 a55stwmod validity";
CM_ SG_ 1482 APSB_sw053_a56bcmodValidity "APSB ECU: sw053 a56bcmod validity";
CM_ SG_ 1482 APSB_sw053_a57dimodValidity "APSB ECU: sw053 a57dimod validity";
CM_ SG_ 1482 APSB_sw053_a59drmiInvalidChkSm "APSB ECU: sw053 a59drmi invalid chk sm";
CM_ SG_ 1482 APSB_sw053_a60drmiInvalidCount "APSB ECU: sw053 a60drmi invalid count";
CM_ SG_ 1482 APSB_sw053_a61radPositionMismatc "APSB ECU: sw053 a61rad position mismatch";
CM_ SG_ 1482 APSB_sw053_a62strRackMismatch "APSB ECU: sw053 a62str rack mismatch";
CM_ SG_ 1482 APSB_sw055_detectedRadcVersion "APSB ECU: sw055 detected radc version";
CM_ SG_ 1482 APSB_sw055_expectedCrcLsw "APSB ECU: sw055 expected crc lsw";
CM_ SG_ 1482 APSB_sw056_diMia "APSB ECU: sw056 di mia";
CM_ SG_ 1482 APSB_sw056_unusedByte "APSB ECU: sw056 unused byte";
CM_ SG_ 1482 APSB_sw056_unusedW0 "APSB ECU: sw056 unused W0";
CM_ SG_ 1482 APSB_sw056_unusedW1 "APSB ECU: sw056 unused W1";
CM_ SG_ 1482 APSB_sw058_epbMia "APSB ECU: sw058 epb mia";
CM_ SG_ 1482 APSB_sw058_unusedByte "APSB ECU: sw058 unused byte";
CM_ SG_ 1482 APSB_sw058_unusedW0 "APSB ECU: sw058 unused W0";
CM_ SG_ 1482 APSB_sw058_unusedW1 "APSB ECU: sw058 unused W1";
CM_ SG_ 1482 APSB_sw059_sdiFront "APSB ECU: sw059 sdi front";
CM_ SG_ 1482 APSB_sw059_sdiRear "APSB ECU: sw059 sdi rear";
CM_ SG_ 1482 APSB_sw059_status "APSB ECU: sw059 status";
CM_ SG_ 1482 APSB_sw059_sensorStatusFront "APSB ECU: sw059 sensor status front";
CM_ SG_ 1482 APSB_sw059_pasFrontMiddle "APSB ECU: sw059 pas front middle";
CM_ SG_ 1482 APSB_sw059_sensorStatusRear "APSB ECU: sw059 sensor status rear";
CM_ SG_ 1482 APSB_sw059_pasRearMiddle "APSB ECU: sw059 pas rear middle";
CM_ SG_ 1482 APSB_sw059_pscStatus "APSB ECU: sw059 psc status";
CM_ SG_ 1482 APSB_sw059_pscVehSlot "APSB ECU: sw059 psc veh slot";
CM_ SG_ 1482 APSB_sw059_status2 "APSB ECU: sw059 status2";
CM_ SG_ 1482 APSB_sw059_oloDict "APSB ECU: sw059 olo dict";
CM_ SG_ 1482 APSB_sw059_oocStatus "APSB ECU: sw059 ooc status";
CM_ SG_ 1482 APSB_sw061_states "APSB ECU: sw061 states";
CM_ SG_ 1482 APSB_sw063_expectedMajorVer "APSB ECU: sw063 expected major ver";
CM_ SG_ 1482 APSB_sw063_detectedMajorVer "APSB ECU: sw063 detected major ver";
CM_ SG_ 1482 APSB_sw063_expectedMinorVer "APSB ECU: sw063 expected minor ver";
CM_ SG_ 1482 APSB_sw063_detectedMinorVer "APSB ECU: sw063 detected minor ver";
CM_ SG_ 1482 APSB_sw063_expectedSubMinorVer "APSB ECU: sw063 expected sub minor ver";
CM_ SG_ 1482 APSB_sw063_detectedSubMinorVer "APSB ECU: sw063 detected sub minor ver";
CM_ SG_ 1482 APSB_sw064_sysStatus "APSB ECU: sw064 sys status";
CM_ SG_ 1482 APSB_sw064_status "APSB ECU: sw064 status";
CM_ SG_ 1482 APSB_sw070_currTireFitment "APSB ECU: sw070 curr tire fitment";
CM_ SG_ 1482 APSB_sw070_lastTireFitment "APSB ECU: sw070 last tire fitment";
CM_ SG_ 1482 APSB_sw070_diGear "APSB ECU: sw070 di gear";
CM_ SG_ 1482 APSB_sw070_driveRail "APSB ECU: sw070 drive rail";
CM_ SG_ 1482 APSB_sw070_accRail "APSB ECU: sw070 acc rail";
CM_ SG_ 1482 APSB_sw070_temperature "APSB ECU: sw070 temperature";
CM_ SG_ 1482 APSB_sw070_currentSpeed "APSB ECU: sw070 current speed";
CM_ SG_ 1482 APSB_sw071_selfParkType "APSB ECU: sw071 self park type";
CM_ SG_ 1482 APSB_sw071_endPosX "APSB ECU: sw071 end pos x";
CM_ SG_ 1482 APSB_sw071_endPosY "APSB ECU: sw071 end pos y";
CM_ SG_ 1482 APSB_sw071_roadClass "APSB ECU: sw071 road class";
CM_ SG_ 1482 APSB_sw071_driverPresent "APSB ECU: sw071 driver present";
CM_ SG_ 1482 APSB_sw071_airSuspension "APSB ECU: sw071 air suspension";
CM_ SG_ 1482 APSB_sw071_temperature "APSB ECU: sw071 temperature";
CM_ SG_ 1482 APSB_sw071_activationType "APSB ECU: sw071 activation type";
CM_ SG_ 1482 APSB_sw072_vehicleX "APSB ECU: sw072 vehicle x";
CM_ SG_ 1482 APSB_sw072_vehicleY "APSB ECU: sw072 vehicle y";
CM_ SG_ 1482 APSB_sw072_vehicleHeading "APSB ECU: sw072 vehicle heading";
CM_ SG_ 1482 APSB_sw072_endDistance "APSB ECU: sw072 end distance";
CM_ SG_ 1482 APSB_sw072_guidanceComplete "APSB ECU: sw072 guidance complete";
CM_ SG_ 1482 APSB_sw072_guidanceRunaway "APSB ECU: sw072 guidance runaway";
CM_ SG_ 1482 APSB_sw072_guidanceTimer "APSB ECU: sw072 guidance timer";
CM_ SG_ 1482 APSB_sw072_handlePress "APSB ECU: sw072 handle press";
CM_ SG_ 1482 APSB_sw072_keyfobPress "APSB ECU: sw072 keyfob press";
CM_ SG_ 1482 APSB_sw072_garageOpened "APSB ECU: sw072 garage opened";
CM_ SG_ 1482 APSB_sw072_userTimeout "APSB ECU: sw072 user timeout";
CM_ SG_ 1482 APSB_sw075_scMia "APSB ECU: sw075 sc mia";
CM_ SG_ 1482 APSB_sw075_unusedByte "APSB ECU: sw075 unused byte";
CM_ SG_ 1482 APSB_sw075_unusedW0 "APSB ECU: sw075 unused W0";
CM_ SG_ 1482 APSB_sw075_unusedW1 "APSB ECU: sw075 unused W1";
CM_ SG_ 1482 APSB_sw077_oocDistance "APSB ECU: sw077 ooc distance";
CM_ SG_ 1482 APSB_sw077_oocConfidence "APSB ECU: sw077 ooc confidence";
CM_ SG_ 1482 APSB_sw077_oocCollisionSide "APSB ECU: sw077 ooc collision side";
CM_ SG_ 1482 APSB_sw077_oocHeight "APSB ECU: sw077 ooc height";
CM_ SG_ 1482 APSB_sw077_vehicleSpeed "APSB ECU: sw077 vehicle speed";
CM_ SG_ 1482 APSB_sw077_oocUntrackedTime "APSB ECU: sw077 ooc untracked time";
CM_ SG_ 1482 APSB_sw077_oocOffCourseDist_cm "APSB ECU: sw077 ooc off course dist cm";
CM_ SG_ 1482 APSB_sw081_radarDistance "APSB ECU: sw081 radar distance";
CM_ SG_ 1482 APSB_sw081_radarTTC "APSB ECU: sw081 radar TTC";
CM_ SG_ 1482 APSB_sw081_cameraDistance "APSB ECU: sw081 camera distance";
CM_ SG_ 1482 APSB_sw081_cameraTTC "APSB ECU: sw081 camera TTC";
CM_ SG_ 1482 APSB_sw081_pedalPosition "APSB ECU: sw081 pedal position";
CM_ SG_ 1482 APSB_sw129_currentVoltage "APSB ECU: sw129 current voltage";
CM_ SG_ 1482 APSB_sw129_maxThreshold "APSB ECU: sw129 max threshold";
CM_ SG_ 1482 APSB_sw129_minThreshold "APSB ECU: sw129 min threshold";
CM_ SG_ 1482 APSB_sw129_powerSequnceError "APSB ECU: sw129 power sequnce error";
CM_ SG_ 1482 APSB_sw129_railControl "APSB ECU: sw129 rail control";
CM_ SG_ 1482 APSB_sw129_railID "APSB ECU: sw129 rail ID";
CM_ SG_ 1482 APSB_sw130_currentTemperature "APSB ECU: sw130 current temperature";
CM_ SG_ 1482 APSB_sw130_maxThreshold "APSB ECU: sw130 max threshold";
CM_ SG_ 1482 APSB_sw130_minThreshold "APSB ECU: sw130 min threshold";
CM_ SG_ 1482 APSB_sw130_tempSensorId "APSB ECU: sw130 temp sensor id";
CM_ SG_ 1482 APSB_sw130_shouldForceApPowerOn "APSB ECU: sw130 should force ap power on";
CM_ SG_ 1482 APSB_sw130_shouldBlockOkToPowerA "APSB ECU: sw130 should block ok to power ap";
CM_ SG_ 1482 APSB_sw132_mismatchType "APSB ECU: sw132 mismatch type";
CM_ SG_ 1482 APSB_sw132_actualHash "APSB ECU: sw132 actual hash";
CM_ SG_ 1482 APSB_sw132_expectedHash "APSB ECU: sw132 expected hash";
CM_ SG_ 1482 APSB_sw133_failedInitStep "APSB ECU: sw133 failed init step";
CM_ SG_ 1482 APSB_sw133_switchInReset "APSB ECU: sw133 switch in reset";
CM_ SG_ 1482 APSB_sw133_phyIsNotRMIIMode "APSB ECU: sw133 phy is not RMII mode";
CM_ SG_ 1482 APSB_sw133_phyInterruptStorm "APSB ECU: sw133 phy interrupt storm";
CM_ SG_ 1482 APSB_sw133_switchEthernetInterLi "APSB ECU: sw133 switch ethernet inter link down";
CM_ SG_ 1482 APSB_sw133_ethSwitchReadFwVerFai "APSB ECU: sw133 eth switch read fw ver failed";
CM_ SG_ 1482 APSB_sw133_ethSwitchFailedToBoot "APSB ECU: sw133 eth switch failed to boot";
CM_ SG_ 1482 APSB_sw133_ethSwitchTimedoutUpda "APSB ECU: sw133 eth switch timedout update";
CM_ SG_ 1482 APSB_sw133_ethSwitchMcuLinkFailo "APSB ECU: sw133 eth switch mcu link failover";
CM_ SG_ 1482 APSB_sw133_ethSwitchMcuLinkDupli "APSB ECU: sw133 eth switch mcu link duplicated";
CM_ SG_ 1482 APSB_sw133_ethSwitchMcuLinkDisco "APSB ECU: sw133 eth switch mcu link disconnected";
CM_ SG_ 1482 APSB_sw133_unused "APSB ECU: sw133 unused";
CM_ SG_ 1482 APSB_sw134_appCamCalibStatus "APSB ECU: sw134 app cam calib status";
CM_ SG_ 1482 APSB_sw134_appCameraLux "APSB ECU: sw134 app camera lux";
CM_ SG_ 1482 APSB_sw134_appInfo "APSB ECU: sw134 app info";
CM_ SG_ 1482 APSB_sw134_appStatus "APSB ECU: sw134 app status";
CM_ SG_ 1482 APSB_sw134_dasAutonomyControlPar "APSB ECU: sw134 das autonomy control party";
CM_ SG_ 1482 APSB_sw134_dasAutonomyControlVeh "APSB ECU: sw134 das autonomy control veh";
CM_ SG_ 1482 APSB_sw134_dasBodyControlsVEH "APSB ECU: sw134 das body controls VEH";
CM_ SG_ 1482 APSB_sw134_dasControl "APSB ECU: sw134 das control";
CM_ SG_ 1482 APSB_sw134_dasControlPty "APSB ECU: sw134 das control pty";
CM_ SG_ 1482 APSB_sw134_dasIntSafetyFrontPty "APSB ECU: sw134 das int safety front pty";
CM_ SG_ 1482 APSB_sw134_dasLanes "APSB ECU: sw134 das lanes";
CM_ SG_ 1482 APSB_sw134_dasObject "APSB ECU: sw134 das object";
CM_ SG_ 1482 APSB_sw134_dasPscControl "APSB ECU: sw134 das psc control";
CM_ SG_ 1482 APSB_sw134_dasStatus "APSB ECU: sw134 das status";
CM_ SG_ 1482 APSB_sw134_dasStatus2 "APSB ECU: sw134 das status2";
CM_ SG_ 1482 APSB_sw134_dasSteeringControl "APSB ECU: sw134 das steering control";
CM_ SG_ 1482 APSB_sw134_dasVisualDebug "APSB ECU: sw134 das visual debug";
CM_ SG_ 1482 APSB_sw134_dasSteeringControlPty "APSB ECU: sw134 das steering control pty";
CM_ SG_ 1482 APSB_sw134_dasChNm "APSB ECU: sw134 das ch nm";
CM_ SG_ 1482 APSB_sw134_appSummon "APSB ECU: sw134 app summon";
CM_ SG_ 1482 APSB_sw134_appEnvironment "APSB ECU: sw134 app environment";
CM_ SG_ 1482 APSB_sw134_dasStatusPty "APSB ECU: sw134 das status pty";
CM_ SG_ 1482 APSB_sw134_dasStatus2Pty "APSB ECU: sw134 das status2 pty";
CM_ SG_ 1482 APSB_sw134_dasMatrixHighBeamRqVE "APSB ECU: sw134 das matrix high beam rq VEH";
CM_ SG_ 1482 APSB_sw134_dasMatrixBendAngleRqP "APSB ECU: sw134 das matrix bend angle rq pty";
CM_ SG_ 1482 APSB_sw134_dasBodyControls2VEH "APSB ECU: sw134 das body controls2 VEH";
CM_ SG_ 1482 APSB_sw134_dasRedundantBrakingCo "APSB ECU: sw134 das redundant braking control";
CM_ SG_ 1482 APSB_sw134_dasRedundantBrak_0001 "APSB ECU: sw134 das redundant braking control pty";
CM_ SG_ 1482 APSB_sw134_timeSinceLastMsg "APSB ECU: sw134 time since last msg";
CM_ SG_ 1482 APSB_sw135_appCriticalReason "APSB ECU: sw135 app critical reason";
CM_ SG_ 1482 APSB_sw135_appTimesyncStatus "APSB ECU: sw135 app timesync status";
CM_ SG_ 1482 APSB_sw136_gpsCommIrrecoverable "APSB ECU: sw136 gps comm irrecoverable";
CM_ SG_ 1482 APSB_sw136_fusionIrrecoverable "APSB ECU: sw136 fusion irrecoverable";
CM_ SG_ 1482 APSB_sw136_antennaUnplugged "APSB ECU: sw136 antenna unplugged";
CM_ SG_ 1482 APSB_sw136_badgpsfix "APSB ECU: sw136 badgpsfix";
CM_ SG_ 1482 APSB_sw137_gpsCommMissing "APSB ECU: sw137 gps comm missing";
CM_ SG_ 1482 APSB_sw137_gpsJunkData "APSB ECU: sw137 gps junk data";
CM_ SG_ 1482 APSB_sw137_gpsNMEAmissing "APSB ECU: sw137 gps NME amissing";
CM_ SG_ 1482 APSB_sw137_gpsUBXmissing "APSB ECU: sw137 gps UB xmissing";
CM_ SG_ 1482 APSB_sw137_fusionModeDisabled "APSB ECU: sw137 fusion mode disabled";
CM_ SG_ 1482 APSB_sw137_gpsCfgFail "APSB ECU: sw137 gps cfg fail";
CM_ SG_ 1482 APSB_sw137_esfStatusMsgMIA "APSB ECU: sw137 esf status msg MIA";
CM_ SG_ 1482 APSB_sw137_wheelTickCfgMissmatch "APSB ECU: sw137 wheel tick cfg missmatch";
CM_ SG_ 1482 APSB_sw137_exitTransportMode "APSB ECU: sw137 exit transport mode";
CM_ SG_ 1482 APSB_sw137_satRejectionTimeout "APSB ECU: sw137 sat rejection timeout";
CM_ SG_ 1482 APSB_sw137_gpsPPSMissing "APSB ECU: sw137 gps PPS missing";
CM_ SG_ 1482 APSB_sw138_cfgBufNull "APSB ECU: sw138 cfg buf null";
CM_ SG_ 1482 APSB_sw138_invalidID "APSB ECU: sw138 invalid ID";
CM_ SG_ 1482 APSB_sw138_gpsBufferOverflow "APSB ECU: sw138 gps buffer overflow";
CM_ SG_ 1482 APSB_sw138_navx5CfgFailed "APSB ECU: sw138 navx5 cfg failed";
CM_ SG_ 1482 APSB_sw138_mcuNMEAmsgUDPinvalid "APSB ECU: sw138 mcu NME amsg UD pinvalid";
CM_ SG_ 1482 APSB_sw138_mcuDbgMsgInvalid "APSB ECU: sw138 mcu dbg msg invalid";
CM_ SG_ 1482 APSB_sw138_mcuDbgMsgTooBig "APSB ECU: sw138 mcu dbg msg too big";
CM_ SG_ 1482 APSB_sw138_mcuFwdNMEAfail "APSB ECU: sw138 mcu fwd NME afail";
CM_ SG_ 1482 APSB_sw138_NMEAinvalidChecksum "APSB ECU: sw138 NME ainvalid checksum";
CM_ SG_ 1482 APSB_sw138_unexpectedNMEAmsg "APSB ECU: sw138 unexpected NME amsg";
CM_ SG_ 1482 APSB_sw138_UARTbusFull "APSB ECU: sw138 UAR tbus full";
CM_ SG_ 1482 APSB_sw138_UARTframeError "APSB ECU: sw138 UAR tframe error";
CM_ SG_ 1482 APSB_sw138_UBXrxFrameTooBig "APSB ECU: sw138 UB xrx frame too big";
CM_ SG_ 1482 APSB_sw138_emptyValidNMEA "APSB ECU: sw138 empty valid NMEA";
CM_ SG_ 1482 APSB_sw138_invalidAsciiNMEA "APSB ECU: sw138 invalid ascii NMEA";
CM_ SG_ 1482 APSB_sw138_wheeltickUARTfault "APSB ECU: sw138 wheeltick UAR tfault";
CM_ SG_ 1482 APSB_sw138_baudrateMismatch "APSB ECU: sw138 baudrate mismatch";
CM_ SG_ 1482 APSB_sw138_wheelTickInvalidSrc "APSB ECU: sw138 wheel tick invalid src";
CM_ SG_ 1482 APSB_sw138_UARTparityError "APSB ECU: sw138 UAR tparity error";
CM_ SG_ 1482 APSB_sw138_UARTrxFifoOverflow "APSB ECU: sw138 UAR trx fifo overflow";
CM_ SG_ 1482 APSB_sw138_UARTrxFifoUnderflow "APSB ECU: sw138 UAR trx fifo underflow";
CM_ SG_ 1482 APSB_sw138_UARTtxFifoOverflow "APSB ECU: sw138 UAR ttx fifo overflow";
CM_ SG_ 1482 APSB_sw138_esfWtMsgTimeout "APSB ECU: sw138 esf wt msg timeout";
CM_ SG_ 1482 APSB_sw138_PFLASHReadError "APSB ECU: sw138 PFLASH read error";
CM_ SG_ 1482 APSB_sw138_PFLASHWriteError "APSB ECU: sw138 PFLASH write error";
CM_ SG_ 1482 APSB_sw138_gpsCfgNack "APSB ECU: sw138 gps cfg nack";
CM_ SG_ 1482 APSB_sw138_gpsCfgIdFail "APSB ECU: sw138 gps cfg id fail";
CM_ SG_ 1482 APSB_sw138_gpsSetCfgNoAck "APSB ECU: sw138 gps set cfg no ack";
CM_ SG_ 1482 APSB_sw138_gpsReadCfgNoResponse "APSB ECU: sw138 gps read cfg no response";
CM_ SG_ 1482 APSB_sw138_ubxErrorReported "APSB ECU: sw138 ubx error reported";
CM_ SG_ 1482 APSB_sw140_lvPowerState "APSB ECU: sw140 lv power state";
CM_ SG_ 1482 APSB_sw140_vehicleStatus "APSB ECU: sw140 vehicle status";
CM_ SG_ 1482 APSB_sw140_status "APSB ECU: sw140 status";
CM_ SG_ 1482 APSB_sw140_lighting "APSB ECU: sw140 lighting";
CM_ SG_ 1482 APSB_sw140_sensors "APSB ECU: sw140 sensors";
CM_ SG_ 1482 APSB_sw140_coolant "APSB ECU: sw140 coolant";
CM_ SG_ 1482 APSB_sw140_okToUseHighPower "APSB ECU: sw140 ok to use high power";
CM_ SG_ 1482 APSB_sw141_inertial1 "APSB ECU: sw141 inertial1";
CM_ SG_ 1482 APSB_sw141_inertial2 "APSB ECU: sw141 inertial2";
CM_ SG_ 1482 APSB_sw142_speed "APSB ECU: sw142 speed";
CM_ SG_ 1482 APSB_sw142_locStatus "APSB ECU: sw142 loc status";
CM_ SG_ 1482 APSB_sw142_locStatus2 "APSB ECU: sw142 loc status2";
CM_ SG_ 1482 APSB_sw142_systemStatus "APSB ECU: sw142 system status";
CM_ SG_ 1482 APSB_sw142_chassisControl "APSB ECU: sw142 chassis control";
CM_ SG_ 1482 APSB_sw142_epbStatus "APSB ECU: sw142 epb status";
CM_ SG_ 1482 APSB_sw142_brakeSystem "APSB ECU: sw142 brake system";
CM_ SG_ 1482 APSB_sw143_status "APSB ECU: sw143 status";
CM_ SG_ 1482 APSB_sw143_wheelRotation "APSB ECU: sw143 wheel rotation";
CM_ SG_ 1482 APSB_sw143_wheelSpeeds "APSB ECU: sw143 wheel speeds";
CM_ SG_ 1482 APSB_sw143_redundantBrakingStatu "APSB ECU: sw143 redundant braking status";
CM_ SG_ 1482 APSB_sw144_restraintStatus "APSB ECU: sw144 restraint status";
CM_ SG_ 1482 APSB_sw145_restraintStatus "APSB ECU: sw145 restraint status";
CM_ SG_ 1482 APSB_sw146_sysStatus "APSB ECU: sw146 sys status";
CM_ SG_ 1482 APSB_sw146_status "APSB ECU: sw146 status";
CM_ SG_ 1482 APSB_sw147_doorStatus "APSB ECU: sw147 door status";
CM_ SG_ 1482 APSB_sw147_switchStatus "APSB ECU: sw147 switch status";
CM_ SG_ 1482 APSB_sw148_doorStatus "APSB ECU: sw148 door status";
CM_ SG_ 1482 APSB_sw148_hvacStatus "APSB ECU: sw148 hvac status";
CM_ SG_ 1482 APSB_sw149_status "APSB ECU: sw149 status";
CM_ SG_ 1482 APSB_sw150_steeringAngleSensor "APSB ECU: sw150 steering angle sensor";
CM_ SG_ 1482 APSB_sw150_rightStalk "APSB ECU: sw150 right stalk";
CM_ SG_ 1482 APSB_sw150_leftStalk "APSB ECU: sw150 left stalk";
CM_ SG_ 1482 APSB_sw153_eacInhibitReason "APSB ECU: sw153 eac inhibit reason";
CM_ SG_ 1482 APSB_sw153_eacInternalState "APSB ECU: sw153 eac internal state";
CM_ SG_ 1482 APSB_sw155_InUnicastError "APSB ECU: sw155 in unicast error";
CM_ SG_ 1482 APSB_sw155_UDPRecvError "APSB ECU: sw155 UDP recv error";
CM_ SG_ 1482 APSB_sw155_UDPMiscError "APSB ECU: sw155 UDP misc error";
CM_ SG_ 1482 APSB_sw155_UDPRTEError "APSB ECU: sw155 UDPRTE error";
CM_ SG_ 1482 APSB_sw155_UDPCheckError "APSB ECU: sw155 UDP check error";
CM_ SG_ 1482 APSB_sw155_UDPDropError "APSB ECU: sw155 UDP drop error";
CM_ SG_ 1482 APSB_sw155_UDPMemError "APSB ECU: sw155 UDP mem error";
CM_ SG_ 1482 APSB_sw155_UDPProtoError "APSB ECU: sw155 UDP proto error";
CM_ SG_ 1482 APSB_sw155_IPRecvError "APSB ECU: sw155 IP recv error";
CM_ SG_ 1482 APSB_sw155_IPMiscError "APSB ECU: sw155 IP misc error";
CM_ SG_ 1482 APSB_sw155_IPRTEError "APSB ECU: sw155 IPRTE error";
CM_ SG_ 1482 APSB_sw155_IPCheckError "APSB ECU: sw155 IP check error";
CM_ SG_ 1482 APSB_sw155_IPMemError "APSB ECU: sw155 IP mem error";
CM_ SG_ 1482 APSB_sw155_IPDropError "APSB ECU: sw155 IP drop error";
CM_ SG_ 1482 APSB_sw155_IPProtoError "APSB ECU: sw155 IP proto error";
CM_ SG_ 1482 APSB_sw158_apbInfo "APSB ECU: sw158 apb info";
CM_ SG_ 1482 APSB_sw158_apbStatus "APSB ECU: sw158 apb status";
CM_ SG_ 1482 APSB_sw158_dasAutonomyControlPar "APSB ECU: sw158 das autonomy control party";
CM_ SG_ 1482 APSB_sw158_dasAutonomyControlVeh "APSB ECU: sw158 das autonomy control veh";
CM_ SG_ 1482 APSB_sw158_dasBodyControlsVEH "APSB ECU: sw158 das body controls VEH";
CM_ SG_ 1482 APSB_sw158_dasControl "APSB ECU: sw158 das control";
CM_ SG_ 1482 APSB_sw158_dasControlPty "APSB ECU: sw158 das control pty";
CM_ SG_ 1482 APSB_sw158_dasIntSafetyFrontPty "APSB ECU: sw158 das int safety front pty";
CM_ SG_ 1482 APSB_sw158_dasLanes "APSB ECU: sw158 das lanes";
CM_ SG_ 1482 APSB_sw158_dasObject "APSB ECU: sw158 das object";
CM_ SG_ 1482 APSB_sw158_dasPscControl "APSB ECU: sw158 das psc control";
CM_ SG_ 1482 APSB_sw158_dasStatus "APSB ECU: sw158 das status";
CM_ SG_ 1482 APSB_sw158_dasStatus2 "APSB ECU: sw158 das status2";
CM_ SG_ 1482 APSB_sw158_dasSteeringControl "APSB ECU: sw158 das steering control";
CM_ SG_ 1482 APSB_sw158_dasVisualDebug "APSB ECU: sw158 das visual debug";
CM_ SG_ 1482 APSB_sw158_dasSteeringControlPty "APSB ECU: sw158 das steering control pty";
CM_ SG_ 1482 APSB_sw158_dasChNm "APSB ECU: sw158 das ch nm";
CM_ SG_ 1482 APSB_sw158_dasStatusPty "APSB ECU: sw158 das status pty";
CM_ SG_ 1482 APSB_sw158_dasStatus2Pty "APSB ECU: sw158 das status2 pty";
CM_ SG_ 1482 APSB_sw158_dasMatrixHighBeamRqVE "APSB ECU: sw158 das matrix high beam rq VEH";
CM_ SG_ 1482 APSB_sw158_dasMatrixBendAngleRqP "APSB ECU: sw158 das matrix bend angle rq pty";
CM_ SG_ 1482 APSB_sw158_dasBodyControls2VEH "APSB ECU: sw158 das body controls2 VEH";
CM_ SG_ 1482 APSB_sw158_dasRedundantBrakingCo "APSB ECU: sw158 das redundant braking control";
CM_ SG_ 1482 APSB_sw158_dasRedundantBrak_0001 "APSB ECU: sw158 das redundant braking control pty";
CM_ SG_ 1482 APSB_sw158_timeSinceLastMsg "APSB ECU: sw158 time since last msg";
CM_ SG_ 1482 APSB_sw159_apbCriticalReason "APSB ECU: sw159 apb critical reason";
CM_ SG_ 1482 APSB_sw159_apbTimesyncStatus "APSB ECU: sw159 apb timesync status";
CM_ SG_ 1482 APSB_sw160_mismatchType "APSB ECU: sw160 mismatch type";
CM_ SG_ 1482 APSB_sw160_actualHash "APSB ECU: sw160 actual hash";
CM_ SG_ 1482 APSB_sw160_expectedHash "APSB ECU: sw160 expected hash";
CM_ SG_ 1482 APSB_sw161_antennaDisconnected "APSB ECU: sw161 antenna disconnected";
CM_ SG_ 1482 APSB_sw172_prolongedUiMia "APSB ECU: sw172 prolonged ui mia";
CM_ SG_ 1482 APSB_sw172_uiMiaAtBootup "APSB ECU: sw172 ui mia at bootup";
CM_ SG_ 1482 APSB_sw188_otherTurbo "APSB ECU: sw188 other turbo";
CM_ SG_ 1482 APSB_sw188_arbUartMiaState "APSB ECU: sw188 arb uart mia state";
CM_ SG_ 1482 APSB_sw188_powerUartMiaState "APSB ECU: sw188 power uart mia state";
CM_ SG_ 1482 APSB_sw188_faultsUartMiaState "APSB ECU: sw188 faults uart mia state";
CM_ SG_ 1482 APSB_sw188_sleepUartMiaState "APSB ECU: sw188 sleep uart mia state";
CM_ SG_ 1482 APSB_sw188_resetUartMiaState "APSB ECU: sw188 reset uart mia state";
CM_ SG_ 1482 APSB_sw188_statMonUartMiaState "APSB ECU: sw188 stat mon uart mia state";
CM_ SG_ 1482 APSB_sw188_wdogStateUartMiaState "APSB ECU: sw188 wdog state uart mia state";
CM_ SG_ 1482 APSB_sw188_critReasUartMiaState "APSB ECU: sw188 crit reas uart mia state";
CM_ SG_ 1482 APSB_sw189_AP_vehicleState10Hz "APSB ECU: sw189 AP vehicle state10 hz";
CM_ SG_ 1482 APSB_sw189_AP_vehicleState1Hz "APSB ECU: sw189 AP vehicle state1 hz";
CM_ SG_ 1482 APSB_sw190_IBST_status "APSB ECU: sw190 IBST status";
CM_ SG_ 1482 APSB_sw192_CANbus "APSB ECU: sw192 CA nbus";
CM_ SG_ 1482 APSB_sw192_SWTxQueueFull "APSB ECU: sw192 SW tx queue full";
CM_ SG_ 1482 APSB_sw192_Busoff "APSB ECU: sw192 busoff";
CM_ SG_ 1482 APSB_sw192_UncorrectedBitError "APSB ECU: sw192 uncorrected bit error";
CM_ SG_ 1482 APSB_sw192_CorrectedBitError "APSB ECU: sw192 corrected bit error";
CM_ SG_ 1482 APSB_sw192_ErrorPassive "APSB ECU: sw192 error passive";
CM_ SG_ 1482 APSB_sw192_RamAccessFailed "APSB ECU: sw192 ram access failed";
CM_ SG_ 1482 APSB_sw192_RxMsgLost "APSB ECU: sw192 rx msg lost";
CM_ SG_ 1482 APSB_sw192_msgIo "APSB ECU: sw192 msg io";
CM_ SG_ 1482 APSB_sw192_queueFailure "APSB ECU: sw192 queue failure";
CM_ SG_ 1482 APSB_sw192_msgId "APSB ECU: sw192 msg id";
CM_ SG_ 1482 APSB_sw199_abortCodeDas "APSB ECU: sw199 abort code das";
CM_ SG_ 1482 APSB_sw199_abortCodePARK "APSB ECU: sw199 abort code PARK";
CM_ SG_ 1482 APSB_sw199_currentSTW "APSB ECU: sw199 current STW";
CM_ SG_ 1482 APSB_sw199_currentSpeed "APSB ECU: sw199 current speed";
CM_ SG_ 1482 APSB_sw199_internalState "APSB ECU: sw199 internal state";
CM_ SG_ 1482 APSB_sw199_maxSpeed "APSB ECU: sw199 max speed";
CM_ SG_ 1482 APSB_sw199_numShifts "APSB ECU: sw199 num shifts";
CM_ SG_ 1482 APSB_sw203_controlType "APSB ECU: sw203 control type";
CM_ SG_ 1482 APSB_sw203_curbType "APSB ECU: sw203 curb type";
CM_ SG_ 1482 APSB_sw203_roadClass "APSB ECU: sw203 road class";
CM_ SG_ 1482 APSB_sw203_slotSizeX "APSB ECU: sw203 slot size x";
CM_ SG_ 1482 APSB_sw203_slotSizeY "APSB ECU: sw203 slot size y";
CM_ SG_ 1482 APSB_sw203_startDistance "APSB ECU: sw203 start distance";
CM_ SG_ 1482 APSB_sw203_vehicleSkew "APSB ECU: sw203 vehicle skew";
CM_ SG_ 1482 APSB_sw204_frLeft "APSB ECU: sw204 fr left";
CM_ SG_ 1482 APSB_sw204_frLeftMiddle "APSB ECU: sw204 fr left middle";
CM_ SG_ 1482 APSB_sw204_frMiddle "APSB ECU: sw204 fr middle";
CM_ SG_ 1482 APSB_sw204_frRight "APSB ECU: sw204 fr right";
CM_ SG_ 1482 APSB_sw204_frRightMiddle "APSB ECU: sw204 fr right middle";
CM_ SG_ 1482 APSB_sw204_maxSpeed "APSB ECU: sw204 max speed";
CM_ SG_ 1482 APSB_sw205_oocDistance "APSB ECU: sw205 ooc distance";
CM_ SG_ 1482 APSB_sw205_rrLeft "APSB ECU: sw205 rr left";
CM_ SG_ 1482 APSB_sw205_rrLeftMiddle "APSB ECU: sw205 rr left middle";
CM_ SG_ 1482 APSB_sw205_rrMiddle "APSB ECU: sw205 rr middle";
CM_ SG_ 1482 APSB_sw205_rrRight "APSB ECU: sw205 rr right";
CM_ SG_ 1482 APSB_sw205_rrRightMiddle "APSB ECU: sw205 rr right middle";
CM_ SG_ 1482 APSB_sw235_resetOrigin "APSB ECU: sw235 reset origin";
CM_ SG_ 1482 APSB_sw235_generalUnrecoverable "APSB ECU: sw235 general unrecoverable";
CM_ SG_ 1482 APSB_sw235_pgoodUnrecoverable "APSB ECU: sw235 pgood unrecoverable";
CM_ SG_ 1482 APSB_sw235_faultUnrecoverable "APSB ECU: sw235 fault unrecoverable";
CM_ SG_ 1482 APSB_sw235_12VFuseUnrecoverable "APSB ECU: sw235 12 v fuse unrecoverable";
CM_ SG_ 1482 APSB_sw235_pgoodLevelUnrcvrble "APSB ECU: sw235 pgood level unrcvrble";
CM_ SG_ 1482 APSB_sw235_faultLevelUnrcvrble "APSB ECU: sw235 fault level unrcvrble";
CM_ SG_ 1482 APSB_sw235_12VFuseLvlUnrcvrble "APSB ECU: sw235 12 v fuse lvl unrcvrble";
CM_ SG_ 1482 APSB_sw235_localSoftwareFault "APSB ECU: sw235 local software fault";
CM_ SG_ 1482 APSB_sw235_unrecoverableFailRese "APSB ECU: sw235 unrecoverable fail reset";
CM_ SG_ 1482 APSB_sw235_generalGic "APSB ECU: sw235 general gic";
CM_ SG_ 1482 APSB_sw235_a72WdtTimeout "APSB ECU: sw235 a72 wdt timeout";
CM_ SG_ 1482 APSB_sw235_generalScs "APSB ECU: sw235 general scs";
CM_ SG_ 1482 APSB_sw235_generalUnexpected "APSB ECU: sw235 general unexpected";
CM_ SG_ 1482 APSB_sw235_canUncorrectedBitErro "APSB ECU: sw235 can uncorrected bit error";
CM_ SG_ 1482 APSB_sw235_canExitBusoffFailed "APSB ECU: sw235 can exit busoff failed";
CM_ SG_ 1482 APSB_sw235_txEnFdbckNotExpected "APSB ECU: sw235 tx en fdbck not expected";
CM_ SG_ 1482 APSB_sw235_nocSmsFailed "APSB ECU: sw235 noc sms failed";
CM_ SG_ 1482 APSB_sw235_nocCamFailed "APSB ECU: sw235 noc cam failed";
CM_ SG_ 1482 APSB_sw235_nocCoreFailed "APSB ECU: sw235 noc core failed";
CM_ SG_ 1482 APSB_sw235_nocScsFailed "APSB ECU: sw235 noc scs failed";
CM_ SG_ 1482 APSB_sw235_model3UiReset "APSB ECU: sw235 model3 ui reset";
CM_ SG_ 1482 APSB_sw235_modelsUiReset "APSB ECU: sw235 models ui reset";
CM_ SG_ 1482 APSB_sw235_pmicApOnPrpUnrcvrble "APSB ECU: sw235 pmic ap on prp unrcvrble";
CM_ SG_ 1482 APSB_sw235_apOnReadyTimeout "APSB ECU: sw235 ap on ready timeout";
CM_ SG_ 1482 APSB_sw235_pmicApOnWaitUnrcvrble "APSB ECU: sw235 pmic ap on wait unrcvrble";
CM_ SG_ 1482 APSB_sw235_apBootingTimeout "APSB ECU: sw235 ap booting timeout";
CM_ SG_ 1482 APSB_sw235_pmicApOffWaitUnrcvrbl "APSB ECU: sw235 pmic ap off wait unrcvrble";
CM_ SG_ 1482 APSB_sw235_resetBeingSent "APSB ECU: sw235 reset being sent";
CM_ SG_ 1482 APSB_sw235_udsResetBeingSent "APSB ECU: sw235 uds reset being sent";
CM_ SG_ 1482 APSB_sw235_smsWdtTimeout "APSB ECU: sw235 sms wdt timeout";
CM_ SG_ 1482 APSB_sw235_smsCanApHealthTimeout "APSB ECU: sw235 sms can ap health timeout";
CM_ SG_ 1482 APSB_sw235_smsTaskWdtTimeout "APSB ECU: sw235 sms task wdt timeout";
CM_ SG_ 1482 APSB_sw237_faultSource "APSB ECU: sw237 fault source";
CM_ SG_ 1482 APSB_sw237_peerSoCFaulted "APSB ECU: sw237 peer so c faulted";
CM_ SG_ 1482 APSB_sw241_unknownVendorOnResume "APSB ECU: sw241 unknown vendor on resume";
CM_ SG_ 1482 APSB_sw241_unknownVendorOnNonRes "APSB ECU: sw241 unknown vendor on non resume";
CM_ SG_ 1482 APSB_sw241_phyReinitFailedOnResu "APSB ECU: sw241 phy reinit failed on resume";
CM_ SG_ 1482 APSB_sw241_phyReinitFailedOnNonR "APSB ECU: sw241 phy reinit failed on non resume";
CM_ SG_ 1482 APSB_sw241_illTestFailed "APSB ECU: sw241 ill test failed";
CM_ SG_ 1482 APSB_sw241_memTestFailed "APSB ECU: sw241 mem test failed";
CM_ SG_ 1482 APSB_sw241_dfiInitCompleteTimeou "APSB ECU: sw241 dfi init complete timeout";
CM_ SG_ 1482 APSB_sw241_phy0TimeoutWaitingFor "APSB ECU: sw241 phy0 timeout waiting for interrupts";
CM_ SG_ 1482 APSB_sw241_phy0Ch0ReadGateOffset "APSB ECU: sw241 phy0 ch0 read gate offset bug";
CM_ SG_ 1482 APSB_sw241_phy0Ch1ReadGateOffset "APSB ECU: sw241 phy0 ch1 read gate offset bug";
CM_ SG_ 1482 APSB_sw241_phy0RdlvlReinitTraini "APSB ECU: sw241 phy0 rdlvl reinit training timeout";
CM_ SG_ 1482 APSB_sw241_phy0RdlvlReinitFailed "APSB ECU: sw241 phy0 rdlvl reinit failed";
CM_ SG_ 1482 APSB_sw241_phy0WdqlvlReinitTrain "APSB ECU: sw241 phy0 wdqlvl reinit training timeout";
CM_ SG_ 1482 APSB_sw241_phy0WdqlvlPhaseMargin "APSB ECU: sw241 phy0 wdqlvl phase margin out of range";
CM_ SG_ 1482 APSB_sw241_phy0WdqlvlReinitFaile "APSB ECU: sw241 phy0 wdqlvl reinit failed";
CM_ SG_ 1482 APSB_sw241_phy1TimeoutWaitingFor "APSB ECU: sw241 phy1 timeout waiting for interrupts";
CM_ SG_ 1482 APSB_sw241_phy1Ch0ReadGateOffset "APSB ECU: sw241 phy1 ch0 read gate offset bug";
CM_ SG_ 1482 APSB_sw241_phy1Ch1ReadGateOffset "APSB ECU: sw241 phy1 ch1 read gate offset bug";
CM_ SG_ 1482 APSB_sw241_phy1RdlvlReinitTraini "APSB ECU: sw241 phy1 rdlvl reinit training timeout";
CM_ SG_ 1482 APSB_sw241_phy1RdlvlReinitFailed "APSB ECU: sw241 phy1 rdlvl reinit failed";
CM_ SG_ 1482 APSB_sw241_phy1WdqlvlReinitTrain "APSB ECU: sw241 phy1 wdqlvl reinit training timeout";
CM_ SG_ 1482 APSB_sw241_phy1WdqlvlPhaseMargin "APSB ECU: sw241 phy1 wdqlvl phase margin out of range";
CM_ SG_ 1482 APSB_sw241_phy1WdqlvlReinitFaile "APSB ECU: sw241 phy1 wdqlvl reinit failed";
CM_ SG_ 1482 APSB_sw241_phy2TimeoutWaitingFor "APSB ECU: sw241 phy2 timeout waiting for interrupts";
CM_ SG_ 1482 APSB_sw241_phy2Ch0ReadGateOffset "APSB ECU: sw241 phy2 ch0 read gate offset bug";
CM_ SG_ 1482 APSB_sw241_phy2Ch1ReadGateOffset "APSB ECU: sw241 phy2 ch1 read gate offset bug";
CM_ SG_ 1482 APSB_sw241_phy2RdlvlReinitTraini "APSB ECU: sw241 phy2 rdlvl reinit training timeout";
CM_ SG_ 1482 APSB_sw241_phy2RdlvlReinitFailed "APSB ECU: sw241 phy2 rdlvl reinit failed";
CM_ SG_ 1482 APSB_sw241_phy2WdqlvlReinitTrain "APSB ECU: sw241 phy2 wdqlvl reinit training timeout";
CM_ SG_ 1482 APSB_sw241_phy2WdqlvlPhaseMargin "APSB ECU: sw241 phy2 wdqlvl phase margin out of range";
CM_ SG_ 1482 APSB_sw241_phy2WdqlvlReinitFaile "APSB ECU: sw241 phy2 wdqlvl reinit failed";
CM_ SG_ 1482 APSB_sw241_phy3TimeoutWaitingFor "APSB ECU: sw241 phy3 timeout waiting for interrupts";
CM_ SG_ 1482 APSB_sw241_phy3Ch0ReadGateOffset "APSB ECU: sw241 phy3 ch0 read gate offset bug";
CM_ SG_ 1482 APSB_sw241_phy3Ch1ReadGateOffset "APSB ECU: sw241 phy3 ch1 read gate offset bug";
CM_ SG_ 1482 APSB_sw241_phy3RdlvlReinitTraini "APSB ECU: sw241 phy3 rdlvl reinit training timeout";
CM_ SG_ 1482 APSB_sw241_phy3RdlvlReinitFailed "APSB ECU: sw241 phy3 rdlvl reinit failed";
CM_ SG_ 1482 APSB_sw241_phy3WdqlvlReinitTrain "APSB ECU: sw241 phy3 wdqlvl reinit training timeout";
CM_ SG_ 1482 APSB_sw241_phy3WdqlvlPhaseMargin "APSB ECU: sw241 phy3 wdqlvl phase margin out of range";
CM_ SG_ 1482 APSB_sw241_phy3WdqlvlReinitFaile "APSB ECU: sw241 phy3 wdqlvl reinit failed";
CM_ SG_ 1482 APSB_sw242_instance "APSB ECU: sw242 instance";
CM_ SG_ 1482 APSB_sw242_clusterSRAMMBISTFaile "APSB ECU: sw242 cluster SRAMMBIST failed";
CM_ SG_ 1482 APSB_sw242_SRAMBankMBISTFailed "APSB ECU: sw242 SRAM bank MBIST failed";
CM_ SG_ 1482 APSB_sw243_instance "APSB ECU: sw243 instance";
CM_ SG_ 1482 APSB_sw243_errorStatus "APSB ECU: sw243 error status";
CM_ SG_ 1482 APSB_sw243_extendedErrorStatus "APSB ECU: sw243 extended error status";
CM_ SG_ 1482 APSB_sw244_instance "APSB ECU: sw244 instance";
CM_ SG_ 1482 APSB_sw244_exceptionCode "APSB ECU: sw244 exception code";
CM_ SG_ 1482 APSB_sw245_unknownMACAddrByte0 "APSB ECU: sw245 unknown MAC addr byte0";
CM_ SG_ 1482 APSB_sw245_unknownMACAddrByte1 "APSB ECU: sw245 unknown MAC addr byte1";
CM_ SG_ 1482 APSB_sw245_unknownMACAddrByte2 "APSB ECU: sw245 unknown MAC addr byte2";
CM_ SG_ 1482 APSB_sw245_unknownMACAddrByte3 "APSB ECU: sw245 unknown MAC addr byte3";
CM_ SG_ 1482 APSB_sw245_unknownMACAddrByte4 "APSB ECU: sw245 unknown MAC addr byte4";
CM_ SG_ 1482 APSB_sw245_unknownMACAddrByte5 "APSB ECU: sw245 unknown MAC addr byte5";
CM_ SG_ 1482 APSB_sw246_ethloopSwitchPort0 "APSB ECU: sw246 ethloop switch port0";
CM_ SG_ 1482 APSB_sw246_ethloopSwitchPort1 "APSB ECU: sw246 ethloop switch port1";
CM_ SG_ 1482 APSB_sw246_ethloopSwitchPort2 "APSB ECU: sw246 ethloop switch port2";
CM_ SG_ 1482 APSB_sw246_ethloopSwitchPort3 "APSB ECU: sw246 ethloop switch port3";
CM_ SG_ 1482 APSB_sw246_ethloopSwitchPort4 "APSB ECU: sw246 ethloop switch port4";
CM_ SG_ 1482 APSB_sw246_ethloopSwitchPort5 "APSB ECU: sw246 ethloop switch port5";
CM_ SG_ 1482 APSB_sw246_ethloopSwitchPort6 "APSB ECU: sw246 ethloop switch port6";
CM_ SG_ 1482 APSB_sw246_ethloopSwitchPort7 "APSB ECU: sw246 ethloop switch port7";
CM_ SG_ 1482 APSB_sw247_crcError "APSB ECU: sw247 crc error";
CM_ SG_ 1482 APSB_sw247_dribbleError "APSB ECU: sw247 dribble error";
CM_ SG_ 1482 APSB_sw247_receiveError "APSB ECU: sw247 receive error";
CM_ SG_ 1482 APSB_sw247_wdogTimeout "APSB ECU: sw247 wdog timeout";
CM_ SG_ 1482 APSB_sw247_overflowError "APSB ECU: sw247 overflow error";
CM_ SG_ 1482 APSB_sw247_giantPacket "APSB ECU: sw247 giant packet";
CM_ SG_ 1482 APSB_sw247_destAddrFilterFail "APSB ECU: sw247 dest addr filter fail";
CM_ SG_ 1482 APSB_sw247_saAddressFilterFail "APSB ECU: sw247 sa address filter fail";
CM_ SG_ 1482 APSB_sw248_ethloopSwitchPort2Sqi "APSB ECU: sw248 ethloop switch port2 sqi";
CM_ SG_ 1482 APSB_sw248_ethloopSwitchPort3Sqi "APSB ECU: sw248 ethloop switch port3 sqi";
CM_ SG_ 1482 APSB_sw249_ufsInitFailureReason "APSB ECU: sw249 ufs init failure reason";
CM_ SG_ 1482 APSB_sw252_ethSwitchPort2 "APSB ECU: sw252 eth switch port2";
CM_ SG_ 1482 APSB_sw253_apWaitForShutdownTime "APSB ECU: sw253 ap wait for shutdown timeout";
CM_ SG_ 1482 APSB_sw253_apOffPrepareTimeout "APSB ECU: sw253 ap off prepare timeout";
CM_ SG_ 1482 APSB_sw253_apSuspendedTimeout "APSB ECU: sw253 ap suspended timeout";
CM_ SG_ 1482 APSB_sw253_socOffReadyTimeout "APSB ECU: sw253 soc off ready timeout";
CM_ SG_ 1482 APSB_sw253_apInLinuxTimeout "APSB ECU: sw253 ap in linux timeout";
CM_ SG_ 1482 APSB_sw253_apInCorebootTimeout "APSB ECU: sw253 ap in coreboot timeout";
CM_ SG_ 1482 APSB_sw253_apBootingTimeout "APSB ECU: sw253 ap booting timeout";
CM_ SG_ 1482 APSB_sw253_apOnTimeout "APSB ECU: sw253 ap on timeout";
CM_ SG_ 1482 APSB_sw254_waitForBusSilenceTime "APSB ECU: sw254 wait for bus silence timeout";
CM_ SG_ 1482 APSB_sw254_sleepReadyTimeout "APSB ECU: sw254 sleep ready timeout";
CM_ SG_ 1482 APSB_sw254_sleepingTimeout "APSB ECU: sw254 sleeping timeout";
CM_ SG_ 1482 APSB_sw255_unknownBootError "APSB ECU: sw255 unknown boot error";
CM_ SG_ 1482 APSB_sw255_adcWrapperInitBootErr "APSB ECU: sw255 adc wrapper init boot error";
CM_ SG_ 1482 APSB_sw255_boardRevisionInitBoot "APSB ECU: sw255 board revision init boot error";
CM_ SG_ 1482 APSB_sw255_i2cInitBootError "APSB ECU: sw255 i2c init boot error";
CM_ SG_ 1482 APSB_sw255_provisionInitBootErro "APSB ECU: sw255 provision init boot error";
CM_ SG_ 1482 APSB_sw255_rtcInitBootError "APSB ECU: sw255 rtc init boot error";
CM_ SG_ 1482 APSB_sw255_vrmInitConfigBootErro "APSB ECU: sw255 vrm init config boot error";
CM_ SG_ 1482 APSB_sw255_powerAonIoBootError "APSB ECU: sw255 power aon io boot error";
CM_ SG_ 1482 APSB_sw255_bl1TocInitBootError "APSB ECU: sw255 bl1 toc init boot error";
CM_ SG_ 1482 APSB_sw255_tmuInitBootError "APSB ECU: sw255 tmu init boot error";
CM_ SG_ 1482 APSB_sw255_udpInitBootError "APSB ECU: sw255 udp init boot error";
CM_ SG_ 1482 APSB_sw255_gpsInitBootError "APSB ECU: sw255 gps init boot error";
CM_ SG_ 1482 APSB_sw255_canInitBootError "APSB ECU: sw255 can init boot error";
CM_ SG_ 1482 APSB_sw255_dfuCheckinSubsystemBo "APSB ECU: sw255 dfu checkin subsystem boot error";
CM_ SG_ 1482 APSB_sw255_sectorProtectionBootE "APSB ECU: sw255 sector protection boot error";
CM_ SG_ 1482 APSB_sw255_flashOpBootError "APSB ECU: sw255 flash op boot error";
CM_ SG_ 1482 APSB_sw255_socIdInitBootError "APSB ECU: sw255 soc id init boot error";
CM_ SG_ 1482 APSB_sw260_pgoodTripSramStatus "APSB ECU: sw260 pgood trip sram status";
CM_ SG_ 1482 APSB_sw260_pgoodPmicFaultSd0 "APSB ECU: sw260 pgood pmic fault sd0";
CM_ SG_ 1482 APSB_sw260_pgoodPmicFaultSd1 "APSB ECU: sw260 pgood pmic fault sd1";
CM_ SG_ 1482 APSB_sw260_pgoodPmicFaultSd2 "APSB ECU: sw260 pgood pmic fault sd2";
CM_ SG_ 1482 APSB_sw260_pgoodPmicFaultSd3 "APSB ECU: sw260 pgood pmic fault sd3";
CM_ SG_ 1482 APSB_sw260_pgoodPmicFaultSd4 "APSB ECU: sw260 pgood pmic fault sd4";
CM_ SG_ 1482 APSB_sw260_pgoodPmicFaultLdo0 "APSB ECU: sw260 pgood pmic fault ldo0";
CM_ SG_ 1482 APSB_sw260_pgoodPmicFaultLdo1 "APSB ECU: sw260 pgood pmic fault ldo1";
CM_ SG_ 1482 APSB_sw260_pgoodPmicFaultLdo2 "APSB ECU: sw260 pgood pmic fault ldo2";
CM_ SG_ 1482 APSB_sw260_pgoodPmicFaultLdo3 "APSB ECU: sw260 pgood pmic fault ldo3";
CM_ SG_ 1482 APSB_sw260_pgoodPmicFaultLdo4 "APSB ECU: sw260 pgood pmic fault ldo4";
CM_ SG_ 1482 APSB_sw260_pgoodPmicFaultLdo5 "APSB ECU: sw260 pgood pmic fault ldo5";
CM_ SG_ 1482 APSB_sw260_pgoodPmicFaultLdo6 "APSB ECU: sw260 pgood pmic fault ldo6";
CM_ SG_ 1482 APSB_sw260_pgoodPmicFaultLdo7 "APSB ECU: sw260 pgood pmic fault ldo7";
CM_ SG_ 1482 APSB_sw260_pgoodPmicFaultLdo8 "APSB ECU: sw260 pgood pmic fault ldo8";
CM_ SG_ 1482 APSB_sw260_pgoodUfs3V3Fail "APSB ECU: sw260 pgood ufs3 V3 fail";
CM_ SG_ 1482 APSB_sw260_pgoodTripVrmRailFail "APSB ECU: sw260 pgood trip vrm rail fail";
CM_ SG_ 1482 APSB_sw260_pgoodIntVrmRailFail "APSB ECU: sw260 pgood int vrm rail fail";
CM_ SG_ 1482 APSB_sw260_pgoodCpuVrmRailFail "APSB ECU: sw260 pgood cpu vrm rail fail";
CM_ SG_ 1482 APSB_sw260_pgoodGpuVrmRailFail "APSB ECU: sw260 pgood gpu vrm rail fail";
CM_ SG_ 1482 APSB_sw260_pgoodDdr0V75VrmRailFa "APSB ECU: sw260 pgood ddr0 V75 vrm rail fail";
CM_ SG_ 1482 APSB_sw260_pgoodDdr1V25VrmRailFa "APSB ECU: sw260 pgood ddr1 V25 vrm rail fail";
CM_ SG_ 1482 APSB_sw260_unknownSource "APSB ECU: sw260 unknown source";
CM_ SG_ 1482 APSB_sw261_vrmPublicFaultValues "APSB ECU: sw261 vrm public fault values";
CM_ SG_ 1482 APSB_sw261_vrmRail1FaultValues "APSB ECU: sw261 vrm rail1 fault values";
CM_ SG_ 1482 APSB_sw261_vrmRail2FaultValues "APSB ECU: sw261 vrm rail2 fault values";
CM_ SG_ 1482 APSB_sw261_vrmRail3FaultValues "APSB ECU: sw261 vrm rail3 fault values";
CM_ SG_ 1482 APSB_sw261_vrmType "APSB ECU: sw261 vrm type";
CM_ SG_ 1482 APSB_sw262_vrmPublicFaultValues "APSB ECU: sw262 vrm public fault values";
CM_ SG_ 1482 APSB_sw262_vrmRail1FaultValues "APSB ECU: sw262 vrm rail1 fault values";
CM_ SG_ 1482 APSB_sw262_vrmRail2FaultValues "APSB ECU: sw262 vrm rail2 fault values";
CM_ SG_ 1482 APSB_sw262_vrmRail3FaultValues "APSB ECU: sw262 vrm rail3 fault values";
CM_ SG_ 1482 APSB_sw262_vrmType "APSB ECU: sw262 vrm type";
CM_ SG_ 1482 APSB_sw263_vrmPublicFaultValues "APSB ECU: sw263 vrm public fault values";
CM_ SG_ 1482 APSB_sw263_vrmRail1FaultValues "APSB ECU: sw263 vrm rail1 fault values";
CM_ SG_ 1482 APSB_sw263_vrmRail2FaultValues "APSB ECU: sw263 vrm rail2 fault values";
CM_ SG_ 1482 APSB_sw263_vrmType "APSB ECU: sw263 vrm type";
CM_ SG_ 1482 APSB_sw279_corruptDirectorySourc "APSB ECU: sw279 corrupt directory source";
CM_ SG_ 1482 APSB_sw279_errorCode "APSB ECU: sw279 error code";
CM_ SG_ 1482 APSB_sw280_pepsStatus "APSB ECU: sw280 peps status";
CM_ SG_ 1482 APSB_sw281_rearSteerStatus "APSB ECU: sw281 rear steer status";
CM_ SG_ 1482 APSB_sw283_psfaStatus "APSB ECU: sw283 psfa status";
CM_ SG_ 1482 APSB_sw288_status "APSB ECU: sw288 status";
CM_ SG_ 1482 APSB_sw289_turboTemperature "APSB ECU: sw289 turbo temperature";
CM_ SG_ 1482 APSB_sw289_turboProbe "APSB ECU: sw289 turbo probe";
CM_ SG_ 1482 APSB_sw289_peer_turboTemperature "APSB ECU: sw289 peer turbo temperature";
CM_ SG_ 1482 APSB_sw289_peer_turboProbe "APSB ECU: sw289 peer turbo probe";
CM_ SG_ 1482 APSB_sw315_sysStatus "APSB ECU: sw315 sys status";
CM_ SG_ 1482 APSB_sw315_status "APSB ECU: sw315 status";
CM_ SG_ 1482 APSB_sw317_motionControlCommand "APSB ECU: sw317 motion control command";
CM_ SG_ 1482 APSB_sw317_vehicleControl2 "APSB ECU: sw317 vehicle control2";
CM_ BO_ 731 "APSB ECU message: eac monitor";
CM_ SG_ 731 APSB_eacAllow "Indicates whether or not the Aurix external angle control (EAC) monitor logic currently allows angle control for Autopilot functions.";
CM_ SG_ 731 APSB_eacMonitorCounter "APSB ECU: eac monitor counter";
CM_ SG_ 731 APSB_eacMonitorChecksum "APSB ECU: eac monitor checksum";
CM_ BO_ 992 "APSB ECU message: power state inputs";
CM_ SG_ 992 APSB_A_lowPowerRequest "APSB ECU: a low power request";
CM_ SG_ 992 APSB_A_lowPowerRequestor "APSB ECU: a low power requestor";
CM_ SG_ 992 APSB_A_forcePowerOffRequest "APSB ECU: a force power off request";
CM_ SG_ 992 APSB_B_lowPowerRequest "APSB ECU: b low power request";
CM_ SG_ 992 APSB_B_lowPowerRequestor "APSB ECU: b low power requestor";
CM_ SG_ 992 APSB_B_forcePowerOffRequest "APSB ECU: b force power off request";
CM_ BO_ 1864 "APSB ECU message: state";
CM_ SG_ 1864 APSB_primaryTurbo "APSB ECU: primary turbo";
CM_ SG_ 1864 APSB_A_arbState "APSB ECU: a arb state";
CM_ SG_ 1864 APSB_A_powerState "The state of the power state machine of Turbo A.";
CM_ SG_ 1864 APSB_A_sleepState "APSB ECU: a sleep state";
CM_ SG_ 1864 APSB_A_resetState "APSB ECU: a reset state";
CM_ SG_ 1864 APSB_A_faultState "APSB ECU: a fault state";
CM_ SG_ 1864 APSB_secondaryTurbo "APSB ECU: secondary turbo";
CM_ SG_ 1864 APSB_B_arbState "APSB ECU: b arb state";
CM_ SG_ 1864 APSB_B_powerState "The state of the power state machine of Turbo B.";
CM_ SG_ 1864 APSB_B_sleepState "APSB ECU: b sleep state";
CM_ SG_ 1864 APSB_B_resetState "APSB ECU: b reset state";
CM_ SG_ 1864 APSB_B_faultState "APSB ECU: b fault state";
CM_ SG_ 1864 APSB_A_autosteerMonitorState "The state of the autosteer Monitor state machine for TurboA.";
CM_ SG_ 1864 APSB_B_autosteerMonitorState "The state of the autosteer Monitor state machine for TurboB.";
CM_ SG_ 1864 APSB_eplannerState "The state of the Eplanner of Turbo B.";
CM_ SG_ 1864 APSB_A_faultInduced "SGK Fault induced on Turbo A or not.";
CM_ SG_ 1864 APSB_B_faultInduced "SGK Fault induced on Turbo B or not.";
CM_ SG_ 1864 APSB_stateCounter "APSB ECU: state counter";
CM_ BO_ 971 "APSB ECU message: status";
CM_ SG_ 971 APSB_appStatusMonitorState "APSB ECU: app status monitor state";
CM_ SG_ 971 APSB_vehBehaviorState "APSB ECU: veh behavior state";
CM_ SG_ 971 APSB_canMaster "Indicates which of the autopilot computers is currently controlling outgoing CAN traffic.";
CM_ SG_ 971 APSB_appGpioState "APSB ECU: app gpio state";
CM_ SG_ 971 APSB_eacInternalState "APSB ECU: eac internal state";
CM_ SG_ 971 APSB_switchState "APSB ECU: switch state";
CM_ SG_ 971 APSB_apbStatusMonitorState "APSB ECU: apb status monitor state";
CM_ SG_ 971 APSB_apbGpioState "APSB ECU: apb gpio state";
CM_ SG_ 971 APSB_statusCounter "APSB ECU: status counter";
CM_ SG_ 971 APSB_locLimitReason "APSB ECU: loc limit reason";
CM_ SG_ 971 APSB_appPowerStateRequest "APSB ECU: app power state request";
CM_ SG_ 971 APSB_appPowerStateReason "APSB ECU: app power state reason";
CM_ SG_ 971 APSB_apbPowerStateRequest "APSB ECU: apb power state request";
CM_ SG_ 971 APSB_apbPowerStateReason "APSB ECU: apb power state reason";
CM_ SG_ 971 APSB_heaterStateDebug "APSB ECU: heater state debug";
CM_ SG_ 971 APSB_autosummonCounter "APSB ECU: autosummon counter";
CM_ SG_ 971 APSB_autosummonAlert "APSB ECU: autosummon alert";
CM_ SG_ 971 APSB_gpsAntennaState "APSB ECU: gps antenna state";
CM_ SG_ 971 APSB_arbState "APSB ECU: arb state";
CM_ SG_ 971 APSB_socPowerOperatingMode "APSB ECU: soc power operating mode";
BA_DEF_ BO_ "GenMsgCycleTime" INT 0 3600000;
BA_DEF_ BO_ "GenMsgSendType" ENUM "Cyclic","NotUsed","NotUsed","NotUsed","NotUsed","NotUsed","NotUsed","IfActive","NoMsgSendType","NotUsed";
BA_DEF_ BO_ "VFrameFormat" ENUM "StandardCAN","ExtendedCAN","reserved","J1939PG","reserved","reserved","reserved","reserved","reserved","reserved","reserved","reserved","reserved","reserved","StandardCAN_FD","ExtendedCAN_FD";
BA_DEF_ BO_ "CANFD_BRS" ENUM "0","1";
BA_DEF_ SG_ "SystemSignalLongSymbol" STRING;
BA_DEF_ SG_ "Confidence" ENUM "layout-only","plausible","validated";
BA_DEF_DEF_ "GenMsgCycleTime" 0;
BA_DEF_DEF_ "GenMsgSendType" "NoMsgSendType";
BA_DEF_DEF_ "VFrameFormat" "StandardCAN";
BA_DEF_DEF_ "CANFD_BRS" "1";
BA_DEF_DEF_ "SystemSignalLongSymbol" "";
BA_DEF_DEF_ "Confidence" "layout-only";
BA_ "SystemSignalLongSymbol" SG_ 1151 APP_w349_cameraPersistentlyFault "APP_w349_cameraPersistentlyFaulted";
BA_ "SystemSignalLongSymbol" SG_ 1149 APP_w388_windshieldCameraHeaterF "APP_w388_windshieldCameraHeaterFaulted";
BA_ "SystemSignalLongSymbol" SG_ 1149 APP_w401_leftPillarCameraHeaterF "APP_w401_leftPillarCameraHeaterFaulted";
BA_ "SystemSignalLongSymbol" SG_ 1149 APP_w402_rightPillarCameraHeater "APP_w402_rightPillarCameraHeaterFaulted";
BA_ "SystemSignalLongSymbol" SG_ 1149 APP_w403_notifyCameraSelfCleanAc "APP_w403_notifyCameraSelfCleanAction";
BA_ "SystemSignalLongSymbol" SG_ 1149 APP_w415_autonomyUnavailableSyst "APP_w415_autonomyUnavailableSystem";
BA_ "SystemSignalLongSymbol" SG_ 1149 APP_w417_autonomyUnavailableVisi "APP_w417_autonomyUnavailableVisibility";
BA_ "SystemSignalLongSymbol" SG_ 1149 APP_w418_autonomyDegradedVisibil "APP_w418_autonomyDegradedVisibility";
BA_ "SystemSignalLongSymbol" SG_ 1149 APP_w419_autonomyUnavailableApSy "APP_w419_autonomyUnavailableApSystem";
BA_ "SystemSignalLongSymbol" SG_ 1149 APP_w420_autonomyDegradedApSyste "APP_w420_autonomyDegradedApSystem";
BA_ "SystemSignalLongSymbol" SG_ 1149 APP_w430_frontVisibilityDegraded "APP_w430_frontVisibilityDegraded_LOW";
BA_ "SystemSignalLongSymbol" SG_ 1149 APP_w431_frontVisibilityDegraded "APP_w431_frontVisibilityDegraded_MEDIUM";
BA_ "SystemSignalLongSymbol" SG_ 1149 APP_w432_frontVisibilityDegraded "APP_w432_frontVisibilityDegraded_HIGH";
BA_ "SystemSignalLongSymbol" SG_ 1149 APP_w433_leftRepeaterDowngradeDe "APP_w433_leftRepeaterDowngradeDetected";
BA_ "SystemSignalLongSymbol" SG_ 1149 APP_w434_rightRepeaterDowngradeD "APP_w434_rightRepeaterDowngradeDetected";
BA_ "SystemSignalLongSymbol" SG_ 1149 APP_w435_repeaterAeroRibInfoMism "APP_w435_repeaterAeroRibInfoMismatched";
BA_ "SystemSignalLongSymbol" SG_ 1149 APP_w443_mainImagerConfigMismatc "APP_w443_mainImagerConfigMismatch";
BA_ "SystemSignalLongSymbol" SG_ 1149 APP_w444_narrowImagerConfigMisma "APP_w444_narrowImagerConfigMismatch";
BA_ "SystemSignalLongSymbol" SG_ 1149 APP_w445_fisheyeImagerConfigMism "APP_w445_fisheyeImagerConfigMismatch";
BA_ "SystemSignalLongSymbol" SG_ 1149 APP_w446_leftPillarImagerConfigM "APP_w446_leftPillarImagerConfigMismatch";
BA_ "SystemSignalLongSymbol" SG_ 1149 APP_w447_rightPillarImagerConfig "APP_w447_rightPillarImagerConfigMismatch";
BA_ "SystemSignalLongSymbol" SG_ 1149 APP_w448_leftRepeaterImagerConfi "APP_w448_leftRepeaterImagerConfigMismatch";
BA_ "SystemSignalLongSymbol" SG_ 1233 APP_w449_rightRepeaterImagerConf "APP_w449_rightRepeaterImagerConfigMismatch";
BA_ "SystemSignalLongSymbol" SG_ 1233 APP_w450_backupImagerConfigMisma "APP_w450_backupImagerConfigMismatch";
BA_ "SystemSignalLongSymbol" SG_ 1233 APP_w451_fasciaImagerConfigMisma "APP_w451_fasciaImagerConfigMismatch";
BA_ "SystemSignalLongSymbol" SG_ 1233 APP_w452_selfieImagerConfigMisma "APP_w452_selfieImagerConfigMismatch";
BA_ "SystemSignalLongSymbol" SG_ 1233 APP_w454_appAutonomySystemUnheal "APP_w454_appAutonomySystemUnhealthy";
BA_ "SystemSignalLongSymbol" SG_ 1233 APP_w455_apbAutonomySystemUnheal "APP_w455_apbAutonomySystemUnhealthy";
BA_ "SystemSignalLongSymbol" SG_ 1233 APP_w456_autonomyUnavailableColl "APP_w456_autonomyUnavailableCollision";
BA_ "SystemSignalLongSymbol" SG_ 1233 APP_w457_autonomyDegradedCollisi "APP_w457_autonomyDegradedCollision";
BA_ "SystemSignalLongSymbol" SG_ 1233 APP_w482_appVisionFailoverActiva "APP_w482_appVisionFailoverActivated";
BA_ "SystemSignalLongSymbol" SG_ 1233 APP_w483_apbVisionFailoverActiva "APP_w483_apbVisionFailoverActivated";
BA_ "SystemSignalLongSymbol" SG_ 1482 APSB_sw010_HorizontalMisalignmen "APSB_sw010_HorizontalMisalignment";
BA_ "SystemSignalLongSymbol" SG_ 1482 APSB_sw035_redundantBrakingStatu "APSB_sw035_redundantBrakingStatus";
BA_ "SystemSignalLongSymbol" SG_ 1482 APSB_sw053_a34steerAngSpdValidit "APSB_sw053_a34steerAngSpdValidity";
BA_ "SystemSignalLongSymbol" SG_ 1482 APSB_sw053_a61radPositionMismatc "APSB_sw053_a61radPositionMismatch";
BA_ "SystemSignalLongSymbol" SG_ 1482 APSB_sw130_shouldBlockOkToPowerA "APSB_sw130_shouldBlockOkToPowerAp";
BA_ "SystemSignalLongSymbol" SG_ 1482 APSB_sw133_switchEthernetInterLi "APSB_sw133_switchEthernetInterLinkDown";
BA_ "SystemSignalLongSymbol" SG_ 1482 APSB_sw133_ethSwitchReadFwVerFai "APSB_sw133_ethSwitchReadFwVerFailed";
BA_ "SystemSignalLongSymbol" SG_ 1482 APSB_sw133_ethSwitchTimedoutUpda "APSB_sw133_ethSwitchTimedoutUpdate";
BA_ "SystemSignalLongSymbol" SG_ 1482 APSB_sw133_ethSwitchMcuLinkFailo "APSB_sw133_ethSwitchMcuLinkFailover";
BA_ "SystemSignalLongSymbol" SG_ 1482 APSB_sw133_ethSwitchMcuLinkDupli "APSB_sw133_ethSwitchMcuLinkDuplicated";
BA_ "SystemSignalLongSymbol" SG_ 1482 APSB_sw133_ethSwitchMcuLinkDisco "APSB_sw133_ethSwitchMcuLinkDisconnected";
BA_ "SystemSignalLongSymbol" SG_ 1482 APSB_sw134_dasAutonomyControlPar "APSB_sw134_dasAutonomyControlParty";
BA_ "SystemSignalLongSymbol" SG_ 1482 APSB_sw134_dasMatrixHighBeamRqVE "APSB_sw134_dasMatrixHighBeamRqVEH";
BA_ "SystemSignalLongSymbol" SG_ 1482 APSB_sw134_dasMatrixBendAngleRqP "APSB_sw134_dasMatrixBendAngleRqPty";
BA_ "SystemSignalLongSymbol" SG_ 1482 APSB_sw134_dasRedundantBrakingCo "APSB_sw134_dasRedundantBrakingControl";
BA_ "SystemSignalLongSymbol" SG_ 1482 APSB_sw134_dasRedundantBrak_0001 "APSB_sw134_dasRedundantBrakingControlPty";
BA_ "SystemSignalLongSymbol" SG_ 1482 APSB_sw143_redundantBrakingStatu "APSB_sw143_redundantBrakingStatus";
BA_ "SystemSignalLongSymbol" SG_ 1482 APSB_sw158_dasAutonomyControlPar "APSB_sw158_dasAutonomyControlParty";
BA_ "SystemSignalLongSymbol" SG_ 1482 APSB_sw158_dasMatrixHighBeamRqVE "APSB_sw158_dasMatrixHighBeamRqVEH";
BA_ "SystemSignalLongSymbol" SG_ 1482 APSB_sw158_dasMatrixBendAngleRqP "APSB_sw158_dasMatrixBendAngleRqPty";
BA_ "SystemSignalLongSymbol" SG_ 1482 APSB_sw158_dasRedundantBrakingCo "APSB_sw158_dasRedundantBrakingControl";
BA_ "SystemSignalLongSymbol" SG_ 1482 APSB_sw158_dasRedundantBrak_0001 "APSB_sw158_dasRedundantBrakingControlPty";
BA_ "SystemSignalLongSymbol" SG_ 1482 APSB_sw235_unrecoverableFailRese "APSB_sw235_unrecoverableFailReset";
BA_ "SystemSignalLongSymbol" SG_ 1482 APSB_sw235_canUncorrectedBitErro "APSB_sw235_canUncorrectedBitError";
BA_ "SystemSignalLongSymbol" SG_ 1482 APSB_sw235_pmicApOffWaitUnrcvrbl "APSB_sw235_pmicApOffWaitUnrcvrble";
BA_ "SystemSignalLongSymbol" SG_ 1482 APSB_sw241_unknownVendorOnNonRes "APSB_sw241_unknownVendorOnNonResume";
BA_ "SystemSignalLongSymbol" SG_ 1482 APSB_sw241_phyReinitFailedOnResu "APSB_sw241_phyReinitFailedOnResume";
BA_ "SystemSignalLongSymbol" SG_ 1482 APSB_sw241_phyReinitFailedOnNonR "APSB_sw241_phyReinitFailedOnNonResume";
BA_ "SystemSignalLongSymbol" SG_ 1482 APSB_sw241_dfiInitCompleteTimeou "APSB_sw241_dfiInitCompleteTimeout";
BA_ "SystemSignalLongSymbol" SG_ 1482 APSB_sw241_phy0TimeoutWaitingFor "APSB_sw241_phy0TimeoutWaitingForInterrupts";
BA_ "SystemSignalLongSymbol" SG_ 1482 APSB_sw241_phy0Ch0ReadGateOffset "APSB_sw241_phy0Ch0ReadGateOffsetBug";
BA_ "SystemSignalLongSymbol" SG_ 1482 APSB_sw241_phy0Ch1ReadGateOffset "APSB_sw241_phy0Ch1ReadGateOffsetBug";
BA_ "SystemSignalLongSymbol" SG_ 1482 APSB_sw241_phy0RdlvlReinitTraini "APSB_sw241_phy0RdlvlReinitTrainingTimeout";
BA_ "SystemSignalLongSymbol" SG_ 1482 APSB_sw241_phy0WdqlvlReinitTrain "APSB_sw241_phy0WdqlvlReinitTrainingTimeout";
BA_ "SystemSignalLongSymbol" SG_ 1482 APSB_sw241_phy0WdqlvlPhaseMargin "APSB_sw241_phy0WdqlvlPhaseMarginOutOfRange";
BA_ "SystemSignalLongSymbol" SG_ 1482 APSB_sw241_phy0WdqlvlReinitFaile "APSB_sw241_phy0WdqlvlReinitFailed";
BA_ "SystemSignalLongSymbol" SG_ 1482 APSB_sw241_phy1TimeoutWaitingFor "APSB_sw241_phy1TimeoutWaitingForInterrupts";
BA_ "SystemSignalLongSymbol" SG_ 1482 APSB_sw241_phy1Ch0ReadGateOffset "APSB_sw241_phy1Ch0ReadGateOffsetBug";
BA_ "SystemSignalLongSymbol" SG_ 1482 APSB_sw241_phy1Ch1ReadGateOffset "APSB_sw241_phy1Ch1ReadGateOffsetBug";
BA_ "SystemSignalLongSymbol" SG_ 1482 APSB_sw241_phy1RdlvlReinitTraini "APSB_sw241_phy1RdlvlReinitTrainingTimeout";
BA_ "SystemSignalLongSymbol" SG_ 1482 APSB_sw241_phy1WdqlvlReinitTrain "APSB_sw241_phy1WdqlvlReinitTrainingTimeout";
BA_ "SystemSignalLongSymbol" SG_ 1482 APSB_sw241_phy1WdqlvlPhaseMargin "APSB_sw241_phy1WdqlvlPhaseMarginOutOfRange";
BA_ "SystemSignalLongSymbol" SG_ 1482 APSB_sw241_phy1WdqlvlReinitFaile "APSB_sw241_phy1WdqlvlReinitFailed";
BA_ "SystemSignalLongSymbol" SG_ 1482 APSB_sw241_phy2TimeoutWaitingFor "APSB_sw241_phy2TimeoutWaitingForInterrupts";
BA_ "SystemSignalLongSymbol" SG_ 1482 APSB_sw241_phy2Ch0ReadGateOffset "APSB_sw241_phy2Ch0ReadGateOffsetBug";
BA_ "SystemSignalLongSymbol" SG_ 1482 APSB_sw241_phy2Ch1ReadGateOffset "APSB_sw241_phy2Ch1ReadGateOffsetBug";
BA_ "SystemSignalLongSymbol" SG_ 1482 APSB_sw241_phy2RdlvlReinitTraini "APSB_sw241_phy2RdlvlReinitTrainingTimeout";
BA_ "SystemSignalLongSymbol" SG_ 1482 APSB_sw241_phy2WdqlvlReinitTrain "APSB_sw241_phy2WdqlvlReinitTrainingTimeout";
BA_ "SystemSignalLongSymbol" SG_ 1482 APSB_sw241_phy2WdqlvlPhaseMargin "APSB_sw241_phy2WdqlvlPhaseMarginOutOfRange";
BA_ "SystemSignalLongSymbol" SG_ 1482 APSB_sw241_phy2WdqlvlReinitFaile "APSB_sw241_phy2WdqlvlReinitFailed";
BA_ "SystemSignalLongSymbol" SG_ 1482 APSB_sw241_phy3TimeoutWaitingFor "APSB_sw241_phy3TimeoutWaitingForInterrupts";
BA_ "SystemSignalLongSymbol" SG_ 1482 APSB_sw241_phy3Ch0ReadGateOffset "APSB_sw241_phy3Ch0ReadGateOffsetBug";
BA_ "SystemSignalLongSymbol" SG_ 1482 APSB_sw241_phy3Ch1ReadGateOffset "APSB_sw241_phy3Ch1ReadGateOffsetBug";
BA_ "SystemSignalLongSymbol" SG_ 1482 APSB_sw241_phy3RdlvlReinitTraini "APSB_sw241_phy3RdlvlReinitTrainingTimeout";
BA_ "SystemSignalLongSymbol" SG_ 1482 APSB_sw241_phy3WdqlvlReinitTrain "APSB_sw241_phy3WdqlvlReinitTrainingTimeout";
BA_ "SystemSignalLongSymbol" SG_ 1482 APSB_sw241_phy3WdqlvlPhaseMargin "APSB_sw241_phy3WdqlvlPhaseMarginOutOfRange";
BA_ "SystemSignalLongSymbol" SG_ 1482 APSB_sw241_phy3WdqlvlReinitFaile "APSB_sw241_phy3WdqlvlReinitFailed";
BA_ "SystemSignalLongSymbol" SG_ 1482 APSB_sw242_clusterSRAMMBISTFaile "APSB_sw242_clusterSRAMMBISTFailed";
BA_ "SystemSignalLongSymbol" SG_ 1482 APSB_sw253_apWaitForShutdownTime "APSB_sw253_apWaitForShutdownTimeout";
BA_ "SystemSignalLongSymbol" SG_ 1482 APSB_sw254_waitForBusSilenceTime "APSB_sw254_waitForBusSilenceTimeout";
BA_ "SystemSignalLongSymbol" SG_ 1482 APSB_sw255_adcWrapperInitBootErr "APSB_sw255_adcWrapperInitBootError";
BA_ "SystemSignalLongSymbol" SG_ 1482 APSB_sw255_boardRevisionInitBoot "APSB_sw255_boardRevisionInitBootError";
BA_ "SystemSignalLongSymbol" SG_ 1482 APSB_sw255_provisionInitBootErro "APSB_sw255_provisionInitBootError";
BA_ "SystemSignalLongSymbol" SG_ 1482 APSB_sw255_vrmInitConfigBootErro "APSB_sw255_vrmInitConfigBootError";
BA_ "SystemSignalLongSymbol" SG_ 1482 APSB_sw255_dfuCheckinSubsystemBo "APSB_sw255_dfuCheckinSubsystemBootError";
BA_ "SystemSignalLongSymbol" SG_ 1482 APSB_sw255_sectorProtectionBootE "APSB_sw255_sectorProtectionBootError";
BA_ "SystemSignalLongSymbol" SG_ 1482 APSB_sw260_pgoodDdr0V75VrmRailFa "APSB_sw260_pgoodDdr0V75VrmRailFail";
BA_ "SystemSignalLongSymbol" SG_ 1482 APSB_sw260_pgoodDdr1V25VrmRailFa "APSB_sw260_pgoodDdr1V25VrmRailFail";
BA_ "SystemSignalLongSymbol" SG_ 1482 APSB_sw279_corruptDirectorySourc "APSB_sw279_corruptDirectorySource";
BA_ "Confidence" SG_ 731 APSB_eacAllow 1;
BA_ "Confidence" SG_ 992 APSB_A_lowPowerRequest 1;
BA_ "Confidence" SG_ 992 APSB_A_lowPowerRequestor 1;
BA_ "Confidence" SG_ 992 APSB_B_lowPowerRequest 1;
BA_ "Confidence" SG_ 992 APSB_B_lowPowerRequestor 1;
BA_ "Confidence" SG_ 1864 APSB_primaryTurbo 1;
BA_ "Confidence" SG_ 1864 APSB_A_arbState 1;
BA_ "Confidence" SG_ 1864 APSB_A_powerState 1;
BA_ "Confidence" SG_ 1864 APSB_A_sleepState 1;
BA_ "Confidence" SG_ 1864 APSB_A_resetState 1;
BA_ "Confidence" SG_ 1864 APSB_A_faultState 1;
BA_ "Confidence" SG_ 1864 APSB_secondaryTurbo 1;
BA_ "Confidence" SG_ 1864 APSB_B_arbState 1;
BA_ "Confidence" SG_ 1864 APSB_B_powerState 1;
BA_ "Confidence" SG_ 1864 APSB_B_sleepState 1;
BA_ "Confidence" SG_ 1864 APSB_B_resetState 1;
BA_ "Confidence" SG_ 1864 APSB_B_faultState 1;
BA_ "Confidence" SG_ 1864 APSB_A_autosteerMonitorState 1;
BA_ "Confidence" SG_ 1864 APSB_B_autosteerMonitorState 1;
BA_ "Confidence" SG_ 1864 APSB_eplannerState 1;
BA_ "Confidence" SG_ 1864 APSB_A_faultInduced 1;
BA_ "Confidence" SG_ 1864 APSB_B_faultInduced 1;
BA_ "Confidence" SG_ 971 APSB_appStatusMonitorState 1;
BA_ "Confidence" SG_ 971 APSB_vehBehaviorState 1;
BA_ "Confidence" SG_ 971 APSB_canMaster 1;
BA_ "Confidence" SG_ 971 APSB_appGpioState 1;
BA_ "Confidence" SG_ 971 APSB_eacInternalState 1;
BA_ "Confidence" SG_ 971 APSB_apbStatusMonitorState 1;
BA_ "Confidence" SG_ 971 APSB_apbGpioState 1;
BA_ "Confidence" SG_ 971 APSB_locLimitReason 1;
BA_ "Confidence" SG_ 971 APSB_appPowerStateRequest 1;
BA_ "Confidence" SG_ 971 APSB_appPowerStateReason 1;
BA_ "Confidence" SG_ 971 APSB_apbPowerStateRequest 1;
BA_ "Confidence" SG_ 971 APSB_apbPowerStateReason 1;
BA_ "Confidence" SG_ 971 APSB_heaterStateDebug 1;
BA_ "Confidence" SG_ 971 APSB_gpsAntennaState 1;
BA_ "Confidence" SG_ 971 APSB_arbState 1;
BA_ "Confidence" SG_ 971 APSB_socPowerOperatingMode 1;
VAL_ 731 APSB_eacAllow 3 "APS_EAC_SNA" 2 "APS_EAC_RESERVED" 1 "APS_EAC_ALLOW" 0 "APS_EAC_INHIBIT" ;
VAL_ 992 APSB_A_lowPowerRequest 5 "APS_LOW_POWER_COLD_RESET" 4 "APS_LOW_POWER_SOC_WARM_RESET" 3 "APS_LOW_POWER_AP_WARM_RESET" 2 "APS_LOW_POWER_OFF" 1 "APS_LOW_POWER_SUSPEND" 0 "APS_LOW_POWER_NONE" ;
VAL_ 992 APSB_A_lowPowerRequestor 10 "APS_LOW_POWER_REQ_COUNT" 9 "APS_LOW_POWER_REQ_SGK_PGOOD_IRQ" 8 "APS_LOW_POWER_REQ_SGK_CONSOLE" 7 "APS_LOW_POWER_REQ_SGK_SLEEP" 6 "APS_LOW_POWER_REQ_SGK_UDS" 5 "APS_LOW_POWER_REQ_SGK_BRIDGE" 4 "APS_LOW_POWER_REQ_SGK_FM" 3 "APS_LOW_POWER_REQ_SGK_POWER" 2 "APS_LOW_POWER_REQ_AP_MAILBOX" 1 "APS_LOW_POWER_REQ_AP_ATF" 0 "APS_LOW_POWER_REQ_NONE" ;
VAL_ 992 APSB_B_lowPowerRequest 5 "APS_LOW_POWER_COLD_RESET" 4 "APS_LOW_POWER_SOC_WARM_RESET" 3 "APS_LOW_POWER_AP_WARM_RESET" 2 "APS_LOW_POWER_OFF" 1 "APS_LOW_POWER_SUSPEND" 0 "APS_LOW_POWER_NONE" ;
VAL_ 992 APSB_B_lowPowerRequestor 10 "APS_LOW_POWER_REQ_COUNT" 9 "APS_LOW_POWER_REQ_SGK_PGOOD_IRQ" 8 "APS_LOW_POWER_REQ_SGK_CONSOLE" 7 "APS_LOW_POWER_REQ_SGK_SLEEP" 6 "APS_LOW_POWER_REQ_SGK_UDS" 5 "APS_LOW_POWER_REQ_SGK_BRIDGE" 4 "APS_LOW_POWER_REQ_SGK_FM" 3 "APS_LOW_POWER_REQ_SGK_POWER" 2 "APS_LOW_POWER_REQ_AP_MAILBOX" 1 "APS_LOW_POWER_REQ_AP_ATF" 0 "APS_LOW_POWER_REQ_NONE" ;
VAL_ 1864 APSB_primaryTurbo 2 "TURBO_UNKNOWN" 1 "TURBO_B" 0 "TURBO_A" ;
VAL_ 1864 APSB_A_arbState 7 "ARB_STATE_COUNT" 6 "ARB_STATE_UNKNOWN" 5 "ARB_STATE_MIA" 4 "ARB_STATE_FAULT" 3 "ARB_STATE_SECONDARY" 2 "ARB_STATE_PRIMARY" 1 "ARB_STATE_IDLE" 0 "ARB_STATE_INIT" ;
VAL_ 1864 APSB_A_powerState 28 "POWER_STATE_AP_FORCE_POWER_OFF" 27 "POWER_STATE_AP_WAIT_FOR_SHUTDOWN_ABORT" 26 "POWER_STATE_AP_IN_LINUX" 25 "POWER_STATE_AP_IDLE" 24 "POWER_STATE_VEH_BOOTING" 23 "POWER_STATE_UNKNOWN" 22 "POWER_STATE_MIA" 21 "POWER_STATE_FAULT" 20 "POWER_STATE_SOC_OFF_ABORT" 19 "POWER_STATE_SOC_OFF" 18 "POWER_STATE_SOC_OFF_READY" 17 "POWER_STATE_AP_SUSPENDED" 16 "POWER_STATE_AP_OFF_ABORT_WAIT_FOR_ACK" 15 "POWER_STATE_AP_OFF_ABORT" 14 "POWER_STATE_AP_OFF_READY_WAIT_FOR_RESPONSE" 13 "POWER_STATE_AP_OFF_READY_WAIT_FOR_ACK" 12 "POWER_STATE_AP_OFF_READY" 11 "POWER_STATE_AP_OFF_PREPARE" 10 "POWER_STATE_AP_WAIT_FOR_SHUTDOWN" 9 "POWER_STATE_AP_ON" 8 "POWER_STATE_AP_IN_COREBOOT" 7 "POWER_STATE_AP_BOOTING" 6 "POWER_STATE_AP_ON_READY_WAIT_FOR_RESPONSE" 5 "POWER_STATE_AP_ON_READY_WAIT_FOR_ACK" 4 "POWER_STATE_AP_ON_READY" 3 "POWER_STATE_AP_ON_PREPARE_WAIT_FOR_RESPONSE" 2 "POWER_STATE_AP_ON_PREPARE_WAIT_FOR_ACK" 1 "POWER_STATE_AP_ON_PREPARE" 0 "POWER_STATE_IDLE" ;
VAL_ 1864 APSB_A_sleepState 9 "SLEEP_STATE_COUNT" 8 "SLEEP_STATE_UNKNOWN" 7 "SLEEP_STATE_MIA" 6 "SLEEP_STATE_FAULT" 5 "SLEEP_STATE_ABORT" 4 "SLEEP_STATE_SLEEPING" 3 "SLEEP_STATE_GOING_TO_SLEEP" 2 "SLEEP_STATE_READY" 1 "SLEEP_STATE_WAIT_FOR_BUS_SILENCE" 0 "SLEEP_STATE_IDLE" ;
VAL_ 1864 APSB_A_resetState 5 "RESET_STATE_COUNT" 4 "RESET_STATE_UNKNOWN" 3 "RESET_STATE_MIA" 2 "RESET_STATE_FAULT" 1 "RESET_STATE_RESETTING" 0 "RESET_STATE_NOT_RESETTING" ;
VAL_ 1864 APSB_A_faultState 27 "FAULT_STATE_COUNT" 26 "FAULT_STATE_UNKNOWN" 25 "FAULT_STATE_MIA" 24 "FAULT_STATE_UNEXPECTED" 23 "FAULT_STATE_SCS" 22 "FAULT_STATE_SOFTWARE_FAULT" 21 "FAULT_STATE_TRIP1_FAULT" 20 "FAULT_STATE_TRIP0_FAULT" 19 "FAULT_STATE_WDT" 18 "FAULT_STATE_CPU_FAULT" 17 "FAULT_STATE_DROOP_TRIP" 16 "FAULT_STATE_DROOP_GPU" 15 "FAULT_STATE_DROOP_CPUCL2" 14 "FAULT_STATE_DROOP_CPUCL1" 13 "FAULT_STATE_DROOP_CPUCL0" 12 "FAULT_STATE_MIF_ECC_AP" 11 "FAULT_STATE_MIF7_DFI_ALERT" 10 "FAULT_STATE_MIF6_DFI_ALERT" 9 "FAULT_STATE_MIF5_DFI_ALERT" 8 "FAULT_STATE_MIF4_DFI_ALERT" 7 "FAULT_STATE_MIF3_DFI_ALERT" 6 "FAULT_STATE_MIF2_DFI_ALERT" 5 "FAULT_STATE_MIF1_DFI_ALERT" 4 "FAULT_STATE_MIF0_DFI_ALERT" 3 "FAULT_STATE_MIF_ECC_UNCORRECTED" 2 "FAULT_STATE_MIF_ECC_CORRECTED" 1 "FAULT_STATE_GIC" 0 "FAULT_STATE_NONE" ;
VAL_ 1864 APSB_secondaryTurbo 2 "TURBO_UNKNOWN" 1 "TURBO_B" 0 "TURBO_A" ;
VAL_ 1864 APSB_B_arbState 7 "ARB_STATE_COUNT" 6 "ARB_STATE_UNKNOWN" 5 "ARB_STATE_MIA" 4 "ARB_STATE_FAULT" 3 "ARB_STATE_SECONDARY" 2 "ARB_STATE_PRIMARY" 1 "ARB_STATE_IDLE" 0 "ARB_STATE_INIT" ;
VAL_ 1864 APSB_B_powerState 28 "POWER_STATE_AP_FORCE_POWER_OFF" 27 "POWER_STATE_AP_WAIT_FOR_SHUTDOWN_ABORT" 26 "POWER_STATE_AP_IN_LINUX" 25 "POWER_STATE_AP_IDLE" 24 "POWER_STATE_VEH_BOOTING" 23 "POWER_STATE_UNKNOWN" 22 "POWER_STATE_MIA" 21 "POWER_STATE_FAULT" 20 "POWER_STATE_SOC_OFF_ABORT" 19 "POWER_STATE_SOC_OFF" 18 "POWER_STATE_SOC_OFF_READY" 17 "POWER_STATE_AP_SUSPENDED" 16 "POWER_STATE_AP_OFF_ABORT_WAIT_FOR_ACK" 15 "POWER_STATE_AP_OFF_ABORT" 14 "POWER_STATE_AP_OFF_READY_WAIT_FOR_RESPONSE" 13 "POWER_STATE_AP_OFF_READY_WAIT_FOR_ACK" 12 "POWER_STATE_AP_OFF_READY" 11 "POWER_STATE_AP_OFF_PREPARE" 10 "POWER_STATE_AP_WAIT_FOR_SHUTDOWN" 9 "POWER_STATE_AP_ON" 8 "POWER_STATE_AP_IN_COREBOOT" 7 "POWER_STATE_AP_BOOTING" 6 "POWER_STATE_AP_ON_READY_WAIT_FOR_RESPONSE" 5 "POWER_STATE_AP_ON_READY_WAIT_FOR_ACK" 4 "POWER_STATE_AP_ON_READY" 3 "POWER_STATE_AP_ON_PREPARE_WAIT_FOR_RESPONSE" 2 "POWER_STATE_AP_ON_PREPARE_WAIT_FOR_ACK" 1 "POWER_STATE_AP_ON_PREPARE" 0 "POWER_STATE_IDLE" ;
VAL_ 1864 APSB_B_sleepState 9 "SLEEP_STATE_COUNT" 8 "SLEEP_STATE_UNKNOWN" 7 "SLEEP_STATE_MIA" 6 "SLEEP_STATE_FAULT" 5 "SLEEP_STATE_ABORT" 4 "SLEEP_STATE_SLEEPING" 3 "SLEEP_STATE_GOING_TO_SLEEP" 2 "SLEEP_STATE_READY" 1 "SLEEP_STATE_WAIT_FOR_BUS_SILENCE" 0 "SLEEP_STATE_IDLE" ;
VAL_ 1864 APSB_B_resetState 5 "RESET_STATE_COUNT" 4 "RESET_STATE_UNKNOWN" 3 "RESET_STATE_MIA" 2 "RESET_STATE_FAULT" 1 "RESET_STATE_RESETTING" 0 "RESET_STATE_NOT_RESETTING" ;
VAL_ 1864 APSB_B_faultState 27 "FAULT_STATE_COUNT" 26 "FAULT_STATE_UNKNOWN" 25 "FAULT_STATE_MIA" 24 "FAULT_STATE_UNEXPECTED" 23 "FAULT_STATE_SCS" 22 "FAULT_STATE_SOFTWARE_FAULT" 21 "FAULT_STATE_TRIP1_FAULT" 20 "FAULT_STATE_TRIP0_FAULT" 19 "FAULT_STATE_WDT" 18 "FAULT_STATE_CPU_FAULT" 17 "FAULT_STATE_DROOP_TRIP" 16 "FAULT_STATE_DROOP_GPU" 15 "FAULT_STATE_DROOP_CPUCL2" 14 "FAULT_STATE_DROOP_CPUCL1" 13 "FAULT_STATE_DROOP_CPUCL0" 12 "FAULT_STATE_MIF_ECC_AP" 11 "FAULT_STATE_MIF7_DFI_ALERT" 10 "FAULT_STATE_MIF6_DFI_ALERT" 9 "FAULT_STATE_MIF5_DFI_ALERT" 8 "FAULT_STATE_MIF4_DFI_ALERT" 7 "FAULT_STATE_MIF3_DFI_ALERT" 6 "FAULT_STATE_MIF2_DFI_ALERT" 5 "FAULT_STATE_MIF1_DFI_ALERT" 4 "FAULT_STATE_MIF0_DFI_ALERT" 3 "FAULT_STATE_MIF_ECC_UNCORRECTED" 2 "FAULT_STATE_MIF_ECC_CORRECTED" 1 "FAULT_STATE_GIC" 0 "FAULT_STATE_NONE" ;
VAL_ 1864 APSB_A_autosteerMonitorState 5 "AUTOSTEER_MONITOR_COUNT" 4 "AUTOSTEER_MONITOR_MIA" 3 "AUTOSTEER_MONITOR_TOI_TRIGGER" 2 "AUTOSTEER_MONITOR_WAIT_FOR_MIA" 1 "AUTOSTEER_MONITOR_ACTIVE" 0 "AUTOSTEER_MONITOR_IDLE" ;
VAL_ 1864 APSB_B_autosteerMonitorState 5 "AUTOSTEER_MONITOR_COUNT" 4 "AUTOSTEER_MONITOR_MIA" 3 "AUTOSTEER_MONITOR_TOI_TRIGGER" 2 "AUTOSTEER_MONITOR_WAIT_FOR_MIA" 1 "AUTOSTEER_MONITOR_ACTIVE" 0 "AUTOSTEER_MONITOR_IDLE" ;
VAL_ 1864 APSB_eplannerState 6 "APS_EPLANNER_NUM_STATES" 5 "APS_EPLANNER_STATE_EXECUTING_BOOT_FIXED_TRAJ" 4 "APS_EPLANNER_STATE_EXECUTING_FIXED_TRAJ" 3 "APS_EPLANNER_STATE_EXECUTING_PLAN_TRAJ" 2 "APS_EPLANNER_STATE_VALID_PLAN" 1 "APS_EPLANNER_STATE_READY" 0 "APS_EPLANNER_STATE_INIT" ;
VAL_ 971 APSB_appStatusMonitorState 7 "STATUS_MONITOR_NUM_STATES" 6 "STATUS_MONITOR_STATE_RECOVERY" 5 "STATUS_MONITOR_STATE_SHUTTING_DOWN" 4 "STATUS_MONITOR_STATE_CRITICAL" 3 "STATUS_MONITOR_STATE_NOMINAL" 2 "STATUS_MONITOR_STATE_INIT" 1 "STATUS_MONITOR_STATE_PWR_OFF" 0 "STATUS_MONITOR_STATE_UNKNOWN" ;
VAL_ 971 APSB_vehBehaviorState 8 "VEH_BEHAVIOR_NUM_STATES" 7 "VEH_BEHAVIOR_STATE_SYSTEM_FAULT" 6 "VEH_BEHAVIOR_STATE_APS_OVERRIDE" 5 "VEH_BEHAVIOR_STATE_APS_FAIL_SAFE" 4 "VEH_BEHAVIOR_STATE_APS_BRIDGE_APB" 3 "VEH_BEHAVIOR_STATE_APS_BRIDGE_APP" 2 "VEH_BEHAVIOR_STATE_APS_CONTROL" 1 "VEH_BEHAVIOR_STATE_APS_AVAILABLE" 0 "VEH_BEHAVIOR_STATE_UNKNOWN" ;
VAL_ 971 APSB_canMaster 3 "CAN_MASTER_SNA" 2 "CAN_MASTER_APB" 1 "CAN_MASTER_APP" 0 "CAN_MASTER_APS" ;
VAL_ 971 APSB_appGpioState 3 "AP_GPIO_STATE_HEALTHY" 2 "AP_GPIO_STATE_CRITICAL" 1 "AP_GPIO_STATE_DISABLED" 0 "AP_GPIO_STATE_PWR_DOWN_REBOOT" ;
VAL_ 971 APSB_eacInternalState 7 "APS_EAC_NUM_STATES" 6 "APS_EAC_STATE_LSS" 5 "APS_EAC_STATE_OVERRIDE" 4 "APS_EAC_STATE_INHIBIT" 3 "APS_EAC_STATE_AUTOPARK" 2 "APS_EAC_STATE_CONTINUOUS" 1 "APS_EAC_STATE_MOMENTARY" 0 "APS_EAC_STATE_INIT" ;
VAL_ 971 APSB_apbStatusMonitorState 7 "STATUS_MONITOR_NUM_STATES" 6 "STATUS_MONITOR_STATE_RECOVERY" 5 "STATUS_MONITOR_STATE_SHUTTING_DOWN" 4 "STATUS_MONITOR_STATE_CRITICAL" 3 "STATUS_MONITOR_STATE_NOMINAL" 2 "STATUS_MONITOR_STATE_INIT" 1 "STATUS_MONITOR_STATE_PWR_OFF" 0 "STATUS_MONITOR_STATE_UNKNOWN" ;
VAL_ 971 APSB_apbGpioState 3 "AP_GPIO_STATE_HEALTHY" 2 "AP_GPIO_STATE_CRITICAL" 1 "AP_GPIO_STATE_DISABLED" 0 "AP_GPIO_STATE_PWR_DOWN_REBOOT" ;
VAL_ 971 APSB_locLimitReason 7 "LOC_LIMITS_EXTENDED" 6 "LOC_MONITOR_UNAVAILABLE" 5 "NO_RADAR_TARGET" 4 "RADAR_NOT_HEALTHY" 3 "PRIMARY_AP_NOT_HEALTHY" 2 "ACC_AND_AEB_UNAVAILABLE" 1 "NOT_IN_DRIVE" 0 "NOMINAL_DEFAULT" ;
VAL_ 971 APSB_appPowerStateRequest 3 "AP_POWER_STATE_SLEEP" 2 "AP_POWER_STATE_SUSPEND" 1 "AP_POWER_STATE_SENTRY" 0 "AP_POWER_STATE_NOMINAL" ;
VAL_ 971 APSB_appPowerStateReason 12 "UI_SUMMON_STANDBY_MODE_ENABLED" 11 "SLEEP_REQUEST_RECVD" 10 "AP_POWER_REQUEST_OVERHEATED" 9 "LOADSHED_POWER_REQUEST_PENDING" 8 "VC_POWER_REQUEST" 7 "AP_POWER_REQUEST_OVERRIDE" 6 "AP_POWER_REQUEST_OVERHEATING" 5 "AP_POWER_REQUEST_HYSTERESIS" 4 "GTW_GOTO_FULL_POWER" 3 "AP_NOT_IN_PARK" 2 "AP_NM_REASON_SET" 1 "AP_WDOG_UNHEALTHY" 0 "UI_POWER_STATE_REQUEST" ;
VAL_ 971 APSB_apbPowerStateRequest 3 "AP_POWER_STATE_SLEEP" 2 "AP_POWER_STATE_SUSPEND" 1 "AP_POWER_STATE_SENTRY" 0 "AP_POWER_STATE_NOMINAL" ;
VAL_ 971 APSB_apbPowerStateReason 12 "UI_SUMMON_STANDBY_MODE_ENABLED" 11 "SLEEP_REQUEST_RECVD" 10 "AP_POWER_REQUEST_OVERHEATED" 9 "LOADSHED_POWER_REQUEST_PENDING" 8 "VC_POWER_REQUEST" 7 "AP_POWER_REQUEST_OVERRIDE" 6 "AP_POWER_REQUEST_OVERHEATING" 5 "AP_POWER_REQUEST_HYSTERESIS" 4 "GTW_GOTO_FULL_POWER" 3 "AP_NOT_IN_PARK" 2 "AP_NM_REASON_SET" 1 "AP_WDOG_UNHEALTHY" 0 "UI_POWER_STATE_REQUEST" ;
VAL_ 971 APSB_heaterStateDebug 7 "APS_HEATER_SNA" 4 "APS_HEATER_FAULT_SHORT" 3 "APS_HEATER_FAULT_OPEN" 2 "APS_HEATER_ON_NOT_HEATING" 1 "APS_HEATER_ON_HEATING" 0 "APS_HEATER_OFF" ;
VAL_ 971 APSB_gpsAntennaState 2 "GPS_ANTENNA_CONNECTED" 1 "GPS_ANTENNA_UNKNOWN" 0 "GPS_ANTENNA_DISCONNECTED" ;
VAL_ 971 APSB_arbState 7 "ARB_STATE_N_COUNT" 6 "ARB_STATE_N_UNKNOWN" 5 "ARB_STATE_N_MIA" 4 "ARB_STATE_N_FAULT" 3 "ARB_STATE_N_SECONDARY" 2 "ARB_STATE_N_PRIMARY" 1 "ARB_STATE_N_IDLE" 0 "ARB_STATE_N_INIT" ;
VAL_ 971 APSB_socPowerOperatingMode 2 "APS_DUAL_SOC" 1 "APS_SINGLE_SOC" 0 "APS_UNKNOWN" ;
